VERSION ""

NS_ :

BS_:

BU_: ACU BrakeTemp_FL BrakeTemp_FR BrakeTemp_RL BrakeTemp_RR DGPS Debugger ECU InboardFloor_FL InboardFloor_FR InboardFloor_RL InboardFloor_RR Steering_Wheel Suspension_FL Suspension_FR Suspension_RL Suspension_RR TCM TireTemp_FL TireTemp_FR TireTemp_RL TireTemp_RR ALL

BO_ 2183159554 Steering_Wheel_Regen_Buttons_to_: 1 Steering_Wheel
 SG_ button_flags : 0|8@1+ (1,0) [0|0] ""  ECU

BO_ 2150629633 ACU_Debug_FD_to_Debugger: 64 ACU
 SG_ Debug_0 : 0|8@1+ (1,0) [0|0] ""  Debugger
 SG_ Debug_1 : 8|8@1+ (1,0) [0|0] ""  Debugger
 SG_ Debug_2 : 16|8@1+ (1,0) [0|0] ""  Debugger
 SG_ Debug_3 : 24|8@1+ (1,0) [0|0] ""  Debugger
 SG_ Debug_4 : 32|8@1+ (1,0) [0|0] ""  Debugger
 SG_ Debug_5 : 40|8@1+ (1,0) [0|0] ""  Debugger
 SG_ Debug_6 : 48|8@1+ (1,0) [0|0] ""  Debugger
 SG_ Debug_7 : 56|8@1+ (1,0) [0|0] ""  Debugger
 SG_ Debug_8 : 64|8@1+ (1,0) [0|0] ""  Debugger
 SG_ Debug_9 : 72|8@1+ (1,0) [0|0] ""  Debugger
 SG_ Debug_10 : 80|8@1+ (1,0) [0|0] ""  Debugger
 SG_ Debug_11 : 88|8@1+ (1,0) [0|0] ""  Debugger
 SG_ Debug_12 : 96|8@1+ (1,0) [0|0] ""  Debugger
 SG_ Debug_13 : 104|8@1+ (1,0) [0|0] ""  Debugger
 SG_ Debug_14 : 112|8@1+ (1,0) [0|0] ""  Debugger
 SG_ Debug_15 : 120|8@1+ (1,0) [0|0] ""  Debugger
 SG_ Debug_16 : 128|8@1+ (1,0) [0|0] ""  Debugger
 SG_ Debug_17 : 136|8@1+ (1,0) [0|0] ""  Debugger
 SG_ Debug_18 : 144|8@1+ (1,0) [0|0] ""  Debugger
 SG_ Debug_19 : 152|8@1+ (1,0) [0|0] ""  Debugger
 SG_ Debug_20 : 160|8@1+ (1,0) [0|0] ""  Debugger
 SG_ Debug_21 : 168|8@1+ (1,0) [0|0] ""  Debugger
 SG_ Debug_22 : 176|8@1+ (1,0) [0|0] ""  Debugger
 SG_ Debug_23 : 184|8@1+ (1,0) [0|0] ""  Debugger
 SG_ Debug_24 : 192|8@1+ (1,0) [0|0] ""  Debugger
 SG_ Debug_25 : 200|8@1+ (1,0) [0|0] ""  Debugger
 SG_ Debug_26 : 208|8@1+ (1,0) [0|0] ""  Debugger
 SG_ Debug_27 : 216|8@1+ (1,0) [0|0] ""  Debugger
 SG_ Debug_28 : 224|8@1+ (1,0) [0|0] ""  Debugger
 SG_ Debug_29 : 232|8@1+ (1,0) [0|0] ""  Debugger
 SG_ Debug_30 : 240|8@1+ (1,0) [0|0] ""  Debugger
 SG_ Debug_31 : 248|8@1+ (1,0) [0|0] ""  Debugger
 SG_ Debug_32 : 256|8@1+ (1,0) [0|0] ""  Debugger
 SG_ Debug_33 : 264|8@1+ (1,0) [0|0] ""  Debugger
 SG_ Debug_34 : 272|8@1+ (1,0) [0|0] ""  Debugger
 SG_ Debug_35 : 280|8@1+ (1,0) [0|0] ""  Debugger
 SG_ Debug_36 : 288|8@1+ (1,0) [0|0] ""  Debugger
 SG_ Debug_37 : 296|8@1+ (1,0) [0|0] ""  Debugger
 SG_ Debug_38 : 304|8@1+ (1,0) [0|0] ""  Debugger
 SG_ Debug_39 : 312|8@1+ (1,0) [0|0] ""  Debugger
 SG_ Debug_40 : 320|8@1+ (1,0) [0|0] ""  Debugger
 SG_ Debug_41 : 328|8@1+ (1,0) [0|0] ""  Debugger
 SG_ Debug_42 : 336|8@1+ (1,0) [0|0] ""  Debugger
 SG_ Debug_43 : 344|8@1+ (1,0) [0|0] ""  Debugger
 SG_ Debug_44 : 352|8@1+ (1,0) [0|0] ""  Debugger
 SG_ Debug_45 : 360|8@1+ (1,0) [0|0] ""  Debugger
 SG_ Debug_46 : 368|8@1+ (1,0) [0|0] ""  Debugger
 SG_ Debug_47 : 376|8@1+ (1,0) [0|0] ""  Debugger
 SG_ Debug_48 : 384|8@1+ (1,0) [0|0] ""  Debugger
 SG_ Debug_49 : 392|8@1+ (1,0) [0|0] ""  Debugger
 SG_ Debug_50 : 400|8@1+ (1,0) [0|0] ""  Debugger
 SG_ Debug_51 : 408|8@1+ (1,0) [0|0] ""  Debugger
 SG_ Debug_52 : 416|8@1+ (1,0) [0|0] ""  Debugger
 SG_ Debug_53 : 424|8@1+ (1,0) [0|0] ""  Debugger
 SG_ Debug_54 : 432|8@1+ (1,0) [0|0] ""  Debugger
 SG_ Debug_55 : 440|8@1+ (1,0) [0|0] ""  Debugger
 SG_ Debug_56 : 448|8@1+ (1,0) [0|0] ""  Debugger
 SG_ Debug_57 : 456|8@1+ (1,0) [0|0] ""  Debugger
 SG_ Debug_58 : 464|8@1+ (1,0) [0|0] ""  Debugger
 SG_ Debug_59 : 472|8@1+ (1,0) [0|0] ""  Debugger
 SG_ Debug_60 : 480|8@1+ (1,0) [0|0] ""  Debugger
 SG_ Debug_61 : 488|8@1+ (1,0) [0|0] ""  Debugger
 SG_ Debug_62 : 496|8@1+ (1,0) [0|0] ""  Debugger
 SG_ Debug_63 : 504|8@1+ (1,0) [0|0] ""  Debugger

BO_ 2150629889 ACU_Ping_to_Debugger: 4 ACU
 SG_ Timestamp : 0|32@1+ (1,0) [0|4294967295] "ms"  Debugger

BO_ 2150629890 ACU_Ping_to_ECU: 4 ACU
 SG_ Timestamp : 0|32@1+ (1,0) [0|4294967295] "ms"  ECU

BO_ 2150632706 ACU_ACU_Cell_Data_1_to_ECU: 64 ACU
 SG_ Cell_0_Voltage : 0|8@1+ (0.01,2) [2|4.55] "Volts"  ECU
 SG_ Cell_0_Temp : 8|8@1+ (0.25,0) [0|63.75] "Celsius"  ECU
 SG_ Cell_1_Voltage : 16|8@1+ (0.01,2) [2|4.55] "Volts"  ECU
 SG_ Cell_1_Temp : 24|8@1+ (0.25,0) [0|63.75] "Celsius"  ECU
 SG_ Cell_2_Voltage : 32|8@1+ (0.01,2) [2|4.55] "Volts"  ECU
 SG_ Cell_2_Temp : 40|8@1+ (0.25,0) [0|63.75] "Celsius"  ECU
 SG_ Cell_3_Voltage : 48|8@1+ (0.01,2) [2|4.55] "Volts"  ECU
 SG_ Cell_3_Temp : 56|8@1+ (0.25,0) [0|63.75] "Celsius"  ECU
 SG_ Cell_4_Voltage : 64|8@1+ (0.01,2) [2|4.55] "Volts"  ECU
 SG_ Cell_4_Temp : 72|8@1+ (0.25,0) [0|63.75] "Celsius"  ECU
 SG_ Cell_5_Voltage : 80|8@1+ (0.01,2) [2|4.55] "Volts"  ECU
 SG_ Cell_5_Temp : 88|8@1+ (0.25,0) [0|63.75] "Celsius"  ECU
 SG_ Cell_6_Voltage : 96|8@1+ (0.01,2) [2|4.55] "Volts"  ECU
 SG_ Cell_6_Temp : 104|8@1+ (0.25,0) [0|63.75] "Celsius"  ECU
 SG_ Cell_7_Voltage : 112|8@1+ (0.01,2) [2|4.55] "Volts"  ECU
 SG_ Cell_7_Temp : 120|8@1+ (0.25,0) [0|63.75] "Celsius"  ECU
 SG_ Cell_8_Voltage : 128|8@1+ (0.01,2) [2|4.55] "Volts"  ECU
 SG_ Cell_8_Temp : 136|8@1+ (0.25,0) [0|63.75] "Celsius"  ECU
 SG_ Cell_9_Voltage : 144|8@1+ (0.01,2) [2|4.55] "Volts"  ECU
 SG_ Cell_9_Temp : 152|8@1+ (0.25,0) [0|63.75] "Celsius"  ECU
 SG_ Cell_10_Voltage : 160|8@1+ (0.01,2) [2|4.55] "Volts"  ECU
 SG_ Cell_10_Temp : 168|8@1+ (0.25,0) [0|63.75] "Celsius"  ECU
 SG_ Cell_11_Voltage : 176|8@1+ (0.01,2) [2|4.55] "Volts"  ECU
 SG_ Cell_11_Temp : 184|8@1+ (0.25,0) [0|63.75] "Celsius"  ECU
 SG_ Cell_12_Voltage : 192|8@1+ (0.01,2) [2|4.55] "Volts"  ECU
 SG_ Cell_12_Temp : 200|8@1+ (0.25,0) [0|63.75] "Celsius"  ECU
 SG_ Cell_13_Voltage : 208|8@1+ (0.01,2) [2|4.55] "Volts"  ECU
 SG_ Cell_13_Temp : 216|8@1+ (0.25,0) [0|63.75] "Celsius"  ECU
 SG_ Cell_14_Voltage : 224|8@1+ (0.01,2) [2|4.55] "Volts"  ECU
 SG_ Cell_14_Temp : 232|8@1+ (0.25,0) [0|63.75] "Celsius"  ECU
 SG_ Cell_15_Voltage : 240|8@1+ (0.01,2) [2|4.55] "Volts"  ECU
 SG_ Cell_15_Temp : 248|8@1+ (0.25,0) [0|63.75] "Celsius"  ECU
 SG_ Cell_16_Voltage : 256|8@1+ (0.01,2) [2|4.55] "Volts"  ECU
 SG_ Cell_16_Temp : 264|8@1+ (0.25,0) [0|63.75] "Celsius"  ECU
 SG_ Cell_17_Voltage : 272|8@1+ (0.01,2) [2|4.55] "Volts"  ECU
 SG_ Cell_17_Temp : 280|8@1+ (0.25,0) [0|63.75] "Celsius"  ECU
 SG_ Cell_18_Voltage : 288|8@1+ (0.01,2) [2|4.55] "Volts"  ECU
 SG_ Cell_18_Temp : 296|8@1+ (0.25,0) [0|63.75] "Celsius"  ECU
 SG_ Cell_19_Voltage : 304|8@1+ (0.01,2) [2|4.55] "Volts"  ECU
 SG_ Cell_19_Temp : 312|8@1+ (0.25,0) [0|63.75] "Celsius"  ECU
 SG_ Cell_20_Voltage : 320|8@1+ (0.01,2) [2|4.55] "Volts"  ECU
 SG_ Cell_20_Temp : 328|8@1+ (0.25,0) [0|63.75] "Celsius"  ECU
 SG_ Cell_21_Voltage : 336|8@1+ (0.01,2) [2|4.55] "Volts"  ECU
 SG_ Cell_21_Temp : 344|8@1+ (0.25,0) [0|63.75] "Celsius"  ECU
 SG_ Cell_22_Voltage : 352|8@1+ (0.01,2) [2|4.55] "Volts"  ECU
 SG_ Cell_22_Temp : 360|8@1+ (0.25,0) [0|63.75] "Celsius"  ECU
 SG_ Cell_23_Voltage : 368|8@1+ (0.01,2) [2|4.55] "Volts"  ECU
 SG_ Cell_23_Temp : 376|8@1+ (0.25,0) [0|63.75] "Celsius"  ECU
 SG_ Cell_24_Voltage : 384|8@1+ (0.01,2) [2|4.55] "Volts"  ECU
 SG_ Cell_24_Temp : 392|8@1+ (0.25,0) [0|63.75] "Celsius"  ECU
 SG_ Cell_25_Voltage : 400|8@1+ (0.01,2) [2|4.55] "Volts"  ECU
 SG_ Cell_25_Temp : 408|8@1+ (0.25,0) [0|63.75] "Celsius"  ECU
 SG_ Cell_26_Voltage : 416|8@1+ (0.01,2) [2|4.55] "Volts"  ECU
 SG_ Cell_26_Temp : 424|8@1+ (0.25,0) [0|63.75] "Celsius"  ECU
 SG_ Cell_27_Voltage : 432|8@1+ (0.01,2) [2|4.55] "Volts"  ECU
 SG_ Cell_27_Temp : 440|8@1+ (0.25,0) [0|63.75] "Celsius"  ECU
 SG_ Cell_28_Voltage : 448|8@1+ (0.01,2) [2|4.55] "Volts"  ECU
 SG_ Cell_28_Temp : 456|8@1+ (0.25,0) [0|63.75] "Celsius"  ECU
 SG_ Cell_29_Voltage : 464|8@1+ (0.01,2) [2|4.55] "Volts"  ECU
 SG_ Cell_29_Temp : 472|8@1+ (0.25,0) [0|63.75] "Celsius"  ECU
 SG_ Cell_30_Voltage : 480|8@1+ (0.01,2) [2|4.55] "Volts"  ECU
 SG_ Cell_30_Temp : 488|8@1+ (0.25,0) [0|63.75] "Celsius"  ECU
 SG_ Cell_31_Voltage : 496|8@1+ (0.01,2) [2|4.55] "Volts"  ECU
 SG_ Cell_31_Temp : 504|8@1+ (0.25,0) [0|63.75] "Celsius"  ECU

BO_ 2150632962 ACU_ACU_Cell_Data_2_to_ECU: 64 ACU
 SG_ Cell_32_Voltage : 0|8@1+ (0.01,2) [2|4.55] "Volts"  ECU
 SG_ Cell_32_Temp : 8|8@1+ (0.25,0) [0|63.75] "Celsius"  ECU
 SG_ Cell_33_Voltage : 16|8@1+ (0.01,2) [2|4.55] "Volts"  ECU
 SG_ Cell_33_Temp : 24|8@1+ (0.25,0) [0|63.75] "Celsius"  ECU
 SG_ Cell_34_Voltage : 32|8@1+ (0.01,2) [2|4.55] "Volts"  ECU
 SG_ Cell_34_Temp : 40|8@1+ (0.25,0) [0|63.75] "Celsius"  ECU
 SG_ Cell_35_Voltage : 48|8@1+ (0.01,2) [2|4.55] "Volts"  ECU
 SG_ Cell_35_Temp : 56|8@1+ (0.25,0) [0|63.75] "Celsius"  ECU
 SG_ Cell_36_Voltage : 64|8@1+ (0.01,2) [2|4.55] "Volts"  ECU
 SG_ Cell_36_Temp : 72|8@1+ (0.25,0) [0|63.75] "Celsius"  ECU
 SG_ Cell_37_Voltage : 80|8@1+ (0.01,2) [2|4.55] "Volts"  ECU
 SG_ Cell_37_Temp : 88|8@1+ (0.25,0) [0|63.75] "Celsius"  ECU
 SG_ Cell_38_Voltage : 96|8@1+ (0.01,2) [2|4.55] "Volts"  ECU
 SG_ Cell_38_Temp : 104|8@1+ (0.25,0) [0|63.75] "Celsius"  ECU
 SG_ Cell_39_Voltage : 112|8@1+ (0.01,2) [2|4.55] "Volts"  ECU
 SG_ Cell_39_Temp : 120|8@1+ (0.25,0) [0|63.75] "Celsius"  ECU
 SG_ Cell_40_Voltage : 128|8@1+ (0.01,2) [2|4.55] "Volts"  ECU
 SG_ Cell_40_Temp : 136|8@1+ (0.25,0) [0|63.75] "Celsius"  ECU
 SG_ Cell_41_Voltage : 144|8@1+ (0.01,2) [2|4.55] "Volts"  ECU
 SG_ Cell_41_Temp : 152|8@1+ (0.25,0) [0|63.75] "Celsius"  ECU
 SG_ Cell_42_Voltage : 160|8@1+ (0.01,2) [2|4.55] "Volts"  ECU
 SG_ Cell_42_Temp : 168|8@1+ (0.25,0) [0|63.75] "Celsius"  ECU
 SG_ Cell_43_Voltage : 176|8@1+ (0.01,2) [2|4.55] "Volts"  ECU
 SG_ Cell_43_Temp : 184|8@1+ (0.25,0) [0|63.75] "Celsius"  ECU
 SG_ Cell_44_Voltage : 192|8@1+ (0.01,2) [2|4.55] "Volts"  ECU
 SG_ Cell_44_Temp : 200|8@1+ (0.25,0) [0|63.75] "Celsius"  ECU
 SG_ Cell_45_Voltage : 208|8@1+ (0.01,2) [2|4.55] "Volts"  ECU
 SG_ Cell_45_Temp : 216|8@1+ (0.25,0) [0|63.75] "Celsius"  ECU
 SG_ Cell_46_Voltage : 224|8@1+ (0.01,2) [2|4.55] "Volts"  ECU
 SG_ Cell_46_Temp : 232|8@1+ (0.25,0) [0|63.75] "Celsius"  ECU
 SG_ Cell_47_Voltage : 240|8@1+ (0.01,2) [2|4.55] "Volts"  ECU
 SG_ Cell_47_Temp : 248|8@1+ (0.25,0) [0|63.75] "Celsius"  ECU
 SG_ Cell_48_Voltage : 256|8@1+ (0.01,2) [2|4.55] "Volts"  ECU
 SG_ Cell_48_Temp : 264|8@1+ (0.25,0) [0|63.75] "Celsius"  ECU
 SG_ Cell_49_Voltage : 272|8@1+ (0.01,2) [2|4.55] "Volts"  ECU
 SG_ Cell_49_Temp : 280|8@1+ (0.25,0) [0|63.75] "Celsius"  ECU
 SG_ Cell_50_Voltage : 288|8@1+ (0.01,2) [2|4.55] "Volts"  ECU
 SG_ Cell_50_Temp : 296|8@1+ (0.25,0) [0|63.75] "Celsius"  ECU
 SG_ Cell_51_Voltage : 304|8@1+ (0.01,2) [2|4.55] "Volts"  ECU
 SG_ Cell_51_Temp : 312|8@1+ (0.25,0) [0|63.75] "Celsius"  ECU
 SG_ Cell_52_Voltage : 320|8@1+ (0.01,2) [2|4.55] "Volts"  ECU
 SG_ Cell_52_Temp : 328|8@1+ (0.25,0) [0|63.75] "Celsius"  ECU
 SG_ Cell_53_Voltage : 336|8@1+ (0.01,2) [2|4.55] "Volts"  ECU
 SG_ Cell_53_Temp : 344|8@1+ (0.25,0) [0|63.75] "Celsius"  ECU
 SG_ Cell_54_Voltage : 352|8@1+ (0.01,2) [2|4.55] "Volts"  ECU
 SG_ Cell_54_Temp : 360|8@1+ (0.25,0) [0|63.75] "Celsius"  ECU
 SG_ Cell_55_Voltage : 368|8@1+ (0.01,2) [2|4.55] "Volts"  ECU
 SG_ Cell_55_Temp : 376|8@1+ (0.25,0) [0|63.75] "Celsius"  ECU
 SG_ Cell_56_Voltage : 384|8@1+ (0.01,2) [2|4.55] "Volts"  ECU
 SG_ Cell_56_Temp : 392|8@1+ (0.25,0) [0|63.75] "Celsius"  ECU
 SG_ Cell_57_Voltage : 400|8@1+ (0.01,2) [2|4.55] "Volts"  ECU
 SG_ Cell_57_Temp : 408|8@1+ (0.25,0) [0|63.75] "Celsius"  ECU
 SG_ Cell_58_Voltage : 416|8@1+ (0.01,2) [2|4.55] "Volts"  ECU
 SG_ Cell_58_Temp : 424|8@1+ (0.25,0) [0|63.75] "Celsius"  ECU
 SG_ Cell_59_Voltage : 432|8@1+ (0.01,2) [2|4.55] "Volts"  ECU
 SG_ Cell_59_Temp : 440|8@1+ (0.25,0) [0|63.75] "Celsius"  ECU
 SG_ Cell_60_Voltage : 448|8@1+ (0.01,2) [2|4.55] "Volts"  ECU
 SG_ Cell_60_Temp : 456|8@1+ (0.25,0) [0|63.75] "Celsius"  ECU
 SG_ Cell_61_Voltage : 464|8@1+ (0.01,2) [2|4.55] "Volts"  ECU
 SG_ Cell_61_Temp : 472|8@1+ (0.25,0) [0|63.75] "Celsius"  ECU
 SG_ Cell_62_Voltage : 480|8@1+ (0.01,2) [2|4.55] "Volts"  ECU
 SG_ Cell_62_Temp : 488|8@1+ (0.25,0) [0|63.75] "Celsius"  ECU
 SG_ Cell_63_Voltage : 496|8@1+ (0.01,2) [2|4.55] "Volts"  ECU
 SG_ Cell_63_Temp : 504|8@1+ (0.25,0) [0|63.75] "Celsius"  ECU

BO_ 2150633218 ACU_ACU_Cell_Data_3_to_ECU: 64 ACU
 SG_ Cell_64_Voltage : 0|8@1+ (0.01,2) [2|4.55] "Volts"  ECU
 SG_ Cell_64_Temp : 8|8@1+ (0.25,0) [0|63.75] "Celsius"  ECU
 SG_ Cell_65_Voltage : 16|8@1+ (0.01,2) [2|4.55] "Volts"  ECU
 SG_ Cell_65_Temp : 24|8@1+ (0.25,0) [0|63.75] "Celsius"  ECU
 SG_ Cell_66_Voltage : 32|8@1+ (0.01,2) [2|4.55] "Volts"  ECU
 SG_ Cell_66_Temp : 40|8@1+ (0.25,0) [0|63.75] "Celsius"  ECU
 SG_ Cell_67_Voltage : 48|8@1+ (0.01,2) [2|4.55] "Volts"  ECU
 SG_ Cell_67_Temp : 56|8@1+ (0.25,0) [0|63.75] "Celsius"  ECU
 SG_ Cell_68_Voltage : 64|8@1+ (0.01,2) [2|4.55] "Volts"  ECU
 SG_ Cell_68_Temp : 72|8@1+ (0.25,0) [0|63.75] "Celsius"  ECU
 SG_ Cell_69_Voltage : 80|8@1+ (0.01,2) [2|4.55] "Volts"  ECU
 SG_ Cell_69_Temp : 88|8@1+ (0.25,0) [0|63.75] "Celsius"  ECU
 SG_ Cell_70_Voltage : 96|8@1+ (0.01,2) [2|4.55] "Volts"  ECU
 SG_ Cell_70_Temp : 104|8@1+ (0.25,0) [0|63.75] "Celsius"  ECU
 SG_ Cell_71_Voltage : 112|8@1+ (0.01,2) [2|4.55] "Volts"  ECU
 SG_ Cell_71_Temp : 120|8@1+ (0.25,0) [0|63.75] "Celsius"  ECU
 SG_ Cell_72_Voltage : 128|8@1+ (0.01,2) [2|4.55] "Volts"  ECU
 SG_ Cell_72_Temp : 136|8@1+ (0.25,0) [0|63.75] "Celsius"  ECU
 SG_ Cell_73_Voltage : 144|8@1+ (0.01,2) [2|4.55] "Volts"  ECU
 SG_ Cell_73_Temp : 152|8@1+ (0.25,0) [0|63.75] "Celsius"  ECU
 SG_ Cell_74_Voltage : 160|8@1+ (0.01,2) [2|4.55] "Volts"  ECU
 SG_ Cell_74_Temp : 168|8@1+ (0.25,0) [0|63.75] "Celsius"  ECU
 SG_ Cell_75_Voltage : 176|8@1+ (0.01,2) [2|4.55] "Volts"  ECU
 SG_ Cell_75_Temp : 184|8@1+ (0.25,0) [0|63.75] "Celsius"  ECU
 SG_ Cell_76_Voltage : 192|8@1+ (0.01,2) [2|4.55] "Volts"  ECU
 SG_ Cell_76_Temp : 200|8@1+ (0.25,0) [0|63.75] "Celsius"  ECU
 SG_ Cell_77_Voltage : 208|8@1+ (0.01,2) [2|4.55] "Volts"  ECU
 SG_ Cell_77_Temp : 216|8@1+ (0.25,0) [0|63.75] "Celsius"  ECU
 SG_ Cell_78_Voltage : 224|8@1+ (0.01,2) [2|4.55] "Volts"  ECU
 SG_ Cell_78_Temp : 232|8@1+ (0.25,0) [0|63.75] "Celsius"  ECU
 SG_ Cell_79_Voltage : 240|8@1+ (0.01,2) [2|4.55] "Volts"  ECU
 SG_ Cell_79_Temp : 248|8@1+ (0.25,0) [0|63.75] "Celsius"  ECU
 SG_ Cell_80_Voltage : 256|8@1+ (0.01,2) [2|4.55] "Volts"  ECU
 SG_ Cell_80_Temp : 264|8@1+ (0.25,0) [0|63.75] "Celsius"  ECU
 SG_ Cell_81_Voltage : 272|8@1+ (0.01,2) [2|4.55] "Volts"  ECU
 SG_ Cell_81_Temp : 280|8@1+ (0.25,0) [0|63.75] "Celsius"  ECU
 SG_ Cell_82_Voltage : 288|8@1+ (0.01,2) [2|4.55] "Volts"  ECU
 SG_ Cell_82_Temp : 296|8@1+ (0.25,0) [0|63.75] "Celsius"  ECU
 SG_ Cell_83_Voltage : 304|8@1+ (0.01,2) [2|4.55] "Volts"  ECU
 SG_ Cell_83_Temp : 312|8@1+ (0.25,0) [0|63.75] "Celsius"  ECU
 SG_ Cell_84_Voltage : 320|8@1+ (0.01,2) [2|4.55] "Volts"  ECU
 SG_ Cell_84_Temp : 328|8@1+ (0.25,0) [0|63.75] "Celsius"  ECU
 SG_ Cell_85_Voltage : 336|8@1+ (0.01,2) [2|4.55] "Volts"  ECU
 SG_ Cell_85_Temp : 344|8@1+ (0.25,0) [0|63.75] "Celsius"  ECU
 SG_ Cell_86_Voltage : 352|8@1+ (0.01,2) [2|4.55] "Volts"  ECU
 SG_ Cell_86_Temp : 360|8@1+ (0.25,0) [0|63.75] "Celsius"  ECU
 SG_ Cell_87_Voltage : 368|8@1+ (0.01,2) [2|4.55] "Volts"  ECU
 SG_ Cell_87_Temp : 376|8@1+ (0.25,0) [0|63.75] "Celsius"  ECU
 SG_ Cell_88_Voltage : 384|8@1+ (0.01,2) [2|4.55] "Volts"  ECU
 SG_ Cell_88_Temp : 392|8@1+ (0.25,0) [0|63.75] "Celsius"  ECU
 SG_ Cell_89_Voltage : 400|8@1+ (0.01,2) [2|4.55] "Volts"  ECU
 SG_ Cell_89_Temp : 408|8@1+ (0.25,0) [0|63.75] "Celsius"  ECU
 SG_ Cell_90_Voltage : 416|8@1+ (0.01,2) [2|4.55] "Volts"  ECU
 SG_ Cell_90_Temp : 424|8@1+ (0.25,0) [0|63.75] "Celsius"  ECU
 SG_ Cell_91_Voltage : 432|8@1+ (0.01,2) [2|4.55] "Volts"  ECU
 SG_ Cell_91_Temp : 440|8@1+ (0.25,0) [0|63.75] "Celsius"  ECU
 SG_ Cell_92_Voltage : 448|8@1+ (0.01,2) [2|4.55] "Volts"  ECU
 SG_ Cell_92_Temp : 456|8@1+ (0.25,0) [0|63.75] "Celsius"  ECU
 SG_ Cell_93_Voltage : 464|8@1+ (0.01,2) [2|4.55] "Volts"  ECU
 SG_ Cell_93_Temp : 472|8@1+ (0.25,0) [0|63.75] "Celsius"  ECU
 SG_ Cell_94_Voltage : 480|8@1+ (0.01,2) [2|4.55] "Volts"  ECU
 SG_ Cell_94_Temp : 488|8@1+ (0.25,0) [0|63.75] "Celsius"  ECU
 SG_ Cell_95_Voltage : 496|8@1+ (0.01,2) [2|4.55] "Volts"  ECU
 SG_ Cell_95_Temp : 504|8@1+ (0.25,0) [0|63.75] "Celsius"  ECU

BO_ 2150633474 ACU_ACU_Cell_Data_4_to_ECU: 64 ACU
 SG_ Cell_96_Voltage : 0|8@1+ (0.01,2) [2|4.55] "Volts"  ECU
 SG_ Cell_96_Temp : 8|8@1+ (0.25,0) [0|63.75] "Celsius"  ECU
 SG_ Cell_97_Voltage : 16|8@1+ (0.01,2) [2|4.55] "Volts"  ECU
 SG_ Cell_97_Temp : 24|8@1+ (0.25,0) [0|63.75] "Celsius"  ECU
 SG_ Cell_98_Voltage : 32|8@1+ (0.01,2) [2|4.55] "Volts"  ECU
 SG_ Cell_98_Temp : 40|8@1+ (0.25,0) [0|63.75] "Celsius"  ECU
 SG_ Cell_99_Voltage : 48|8@1+ (0.01,2) [2|4.55] "Volts"  ECU
 SG_ Cell_99_Temp : 56|8@1+ (0.25,0) [0|63.75] "Celsius"  ECU
 SG_ Cell_100_Voltage : 64|8@1+ (0.01,2) [2|4.55] "Volts"  ECU
 SG_ Cell_100_Temp : 72|8@1+ (0.25,0) [0|63.75] "Celsius"  ECU
 SG_ Cell_101_Voltage : 80|8@1+ (0.01,2) [2|4.55] "Volts"  ECU
 SG_ Cell_101_Temp : 88|8@1+ (0.25,0) [0|63.75] "Celsius"  ECU
 SG_ Cell_102_Voltage : 96|8@1+ (0.01,2) [2|4.55] "Volts"  ECU
 SG_ Cell_102_Temp : 104|8@1+ (0.25,0) [0|63.75] "Celsius"  ECU
 SG_ Cell_103_Voltage : 112|8@1+ (0.01,2) [2|4.55] "Volts"  ECU
 SG_ Cell_103_Temp : 120|8@1+ (0.25,0) [0|63.75] "Celsius"  ECU
 SG_ Cell_104_Voltage : 128|8@1+ (0.01,2) [2|4.55] "Volts"  ECU
 SG_ Cell_104_Temp : 136|8@1+ (0.25,0) [0|63.75] "Celsius"  ECU
 SG_ Cell_105_Voltage : 144|8@1+ (0.01,2) [2|4.55] "Volts"  ECU
 SG_ Cell_105_Temp : 152|8@1+ (0.25,0) [0|63.75] "Celsius"  ECU
 SG_ Cell_106_Voltage : 160|8@1+ (0.01,2) [2|4.55] "Volts"  ECU
 SG_ Cell_106_Temp : 168|8@1+ (0.25,0) [0|63.75] "Celsius"  ECU
 SG_ Cell_107_Voltage : 176|8@1+ (0.01,2) [2|4.55] "Volts"  ECU
 SG_ Cell_107_Temp : 184|8@1+ (0.25,0) [0|63.75] "Celsius"  ECU
 SG_ Cell_108_Voltage : 192|8@1+ (0.01,2) [2|4.55] "Volts"  ECU
 SG_ Cell_108_Temp : 200|8@1+ (0.25,0) [0|63.75] "Celsius"  ECU
 SG_ Cell_109_Voltage : 208|8@1+ (0.01,2) [2|4.55] "Volts"  ECU
 SG_ Cell_109_Temp : 216|8@1+ (0.25,0) [0|63.75] "Celsius"  ECU
 SG_ Cell_110_Voltage : 224|8@1+ (0.01,2) [2|4.55] "Volts"  ECU
 SG_ Cell_110_Temp : 232|8@1+ (0.25,0) [0|63.75] "Celsius"  ECU
 SG_ Cell_111_Voltage : 240|8@1+ (0.01,2) [2|4.55] "Volts"  ECU
 SG_ Cell_111_Temp : 248|8@1+ (0.25,0) [0|63.75] "Celsius"  ECU
 SG_ Cell_112_Voltage : 256|8@1+ (0.01,2) [2|4.55] "Volts"  ECU
 SG_ Cell_112_Temp : 264|8@1+ (0.25,0) [0|63.75] "Celsius"  ECU
 SG_ Cell_113_Voltage : 272|8@1+ (0.01,2) [2|4.55] "Volts"  ECU
 SG_ Cell_113_Temp : 280|8@1+ (0.25,0) [0|63.75] "Celsius"  ECU
 SG_ Cell_114_Voltage : 288|8@1+ (0.01,2) [2|4.55] "Volts"  ECU
 SG_ Cell_114_Temp : 296|8@1+ (0.25,0) [0|63.75] "Celsius"  ECU
 SG_ Cell_115_Voltage : 304|8@1+ (0.01,2) [2|4.55] "Volts"  ECU
 SG_ Cell_115_Temp : 312|8@1+ (0.25,0) [0|63.75] "Celsius"  ECU
 SG_ Cell_116_Voltage : 320|8@1+ (0.01,2) [2|4.55] "Volts"  ECU
 SG_ Cell_116_Temp : 328|8@1+ (0.25,0) [0|63.75] "Celsius"  ECU
 SG_ Cell_117_Voltage : 336|8@1+ (0.01,2) [2|4.55] "Volts"  ECU
 SG_ Cell_117_Temp : 344|8@1+ (0.25,0) [0|63.75] "Celsius"  ECU
 SG_ Cell_118_Voltage : 352|8@1+ (0.01,2) [2|4.55] "Volts"  ECU
 SG_ Cell_118_Temp : 360|8@1+ (0.25,0) [0|63.75] "Celsius"  ECU
 SG_ Cell_119_Voltage : 368|8@1+ (0.01,2) [2|4.55] "Volts"  ECU
 SG_ Cell_119_Temp : 376|8@1+ (0.25,0) [0|63.75] "Celsius"  ECU
 SG_ Cell_120_Voltage : 384|8@1+ (0.01,2) [2|4.55] "Volts"  ECU
 SG_ Cell_120_Temp : 392|8@1+ (0.25,0) [0|63.75] "Celsius"  ECU
 SG_ Cell_121_Voltage : 400|8@1+ (0.01,2) [2|4.55] "Volts"  ECU
 SG_ Cell_121_Temp : 408|8@1+ (0.25,0) [0|63.75] "Celsius"  ECU
 SG_ Cell_122_Voltage : 416|8@1+ (0.01,2) [2|4.55] "Volts"  ECU
 SG_ Cell_122_Temp : 424|8@1+ (0.25,0) [0|63.75] "Celsius"  ECU
 SG_ Cell_123_Voltage : 432|8@1+ (0.01,2) [2|4.55] "Volts"  ECU
 SG_ Cell_123_Temp : 440|8@1+ (0.25,0) [0|63.75] "Celsius"  ECU
 SG_ Cell_124_Voltage : 448|8@1+ (0.01,2) [2|4.55] "Volts"  ECU
 SG_ Cell_124_Temp : 456|8@1+ (0.25,0) [0|63.75] "Celsius"  ECU
 SG_ Cell_125_Voltage : 464|8@1+ (0.01,2) [2|4.55] "Volts"  ECU
 SG_ Cell_125_Temp : 472|8@1+ (0.25,0) [0|63.75] "Celsius"  ECU
 SG_ Cell_126_Voltage : 480|8@1+ (0.01,2) [2|4.55] "Volts"  ECU
 SG_ Cell_126_Temp : 488|8@1+ (0.25,0) [0|63.75] "Celsius"  ECU
 SG_ Cell_127_Voltage : 496|8@1+ (0.01,2) [2|4.55] "Volts"  ECU
 SG_ Cell_127_Temp : 504|8@1+ (0.25,0) [0|63.75] "Celsius"  ECU

BO_ 2150633730 ACU_ACU_Cell_Data_5_to_ECU: 64 ACU
 SG_ Cell_128_Voltage : 0|8@1+ (0.01,2) [2|4.55] "Volts"  ECU
 SG_ Cell_128_Temp : 8|8@1+ (0.25,0) [0|63.75] "Celsius"  ECU
 SG_ Cell_129_Voltage : 16|8@1+ (0.01,2) [2|4.55] "Volts"  ECU
 SG_ Cell_129_Temp : 24|8@1+ (0.25,0) [0|63.75] "Celsius"  ECU
 SG_ Cell_130_Voltage : 32|8@1+ (0.01,2) [2|4.55] "Volts"  ECU
 SG_ Cell_130_Temp : 40|8@1+ (0.25,0) [0|63.75] "Celsius"  ECU
 SG_ Cell_131_Voltage : 48|8@1+ (0.01,2) [2|4.55] "Volts"  ECU
 SG_ Cell_131_Temp : 56|8@1+ (0.25,0) [0|63.75] "Celsius"  ECU
 SG_ Cell_132_Voltage : 64|8@1+ (0.01,2) [2|4.55] "Volts"  ECU
 SG_ Cell_132_Temp : 72|8@1+ (0.25,0) [0|63.75] "Celsius"  ECU
 SG_ Cell_133_Voltage : 80|8@1+ (0.01,2) [2|4.55] "Volts"  ECU
 SG_ Cell_133_Temp : 88|8@1+ (0.25,0) [0|63.75] "Celsius"  ECU
 SG_ Cell_134_Voltage : 96|8@1+ (0.01,2) [2|4.55] "Volts"  ECU
 SG_ Cell_134_Temp : 104|8@1+ (0.25,0) [0|63.75] "Celsius"  ECU
 SG_ Cell_135_Voltage : 112|8@1+ (0.01,2) [2|4.55] "Volts"  ECU
 SG_ Cell_135_Temp : 120|8@1+ (0.25,0) [0|63.75] "Celsius"  ECU
 SG_ Cell_136_Voltage : 128|8@1+ (0.01,2) [2|4.55] "Volts"  ECU
 SG_ Cell_136_Temp : 136|8@1+ (0.25,0) [0|63.75] "Celsius"  ECU
 SG_ Cell_137_Voltage : 144|8@1+ (0.01,2) [2|4.55] "Volts"  ECU
 SG_ Cell_137_Temp : 152|8@1+ (0.25,0) [0|63.75] "Celsius"  ECU
 SG_ Cell_138_Voltage : 160|8@1+ (0.01,2) [2|4.55] "Volts"  ECU
 SG_ Cell_138_Temp : 168|8@1+ (0.25,0) [0|63.75] "Celsius"  ECU
 SG_ Cell_139_Voltage : 176|8@1+ (0.01,2) [2|4.55] "Volts"  ECU
 SG_ Cell_139_Temp : 184|8@1+ (0.25,0) [0|63.75] "Celsius"  ECU
 SG_ Cell_140_Voltage : 192|8@1+ (0.01,2) [2|4.55] "Volts"  ECU
 SG_ Cell_140_Temp : 200|8@1+ (0.25,0) [0|63.75] "Celsius"  ECU
 SG_ Cell_141_Voltage : 208|8@1+ (0.01,2) [2|4.55] "Volts"  ECU
 SG_ Cell_141_Temp : 216|8@1+ (0.25,0) [0|63.75] "Celsius"  ECU
 SG_ Cell_142_Voltage : 224|8@1+ (0.01,2) [2|4.55] "Volts"  ECU
 SG_ Cell_142_Temp : 232|8@1+ (0.25,0) [0|63.75] "Celsius"  ECU
 SG_ Cell_143_Voltage : 240|8@1+ (0.01,2) [2|4.55] "Volts"  ECU
 SG_ Cell_143_Temp : 248|8@1+ (0.25,0) [0|63.75] "Celsius"  ECU
 SG_ Cell_144_Voltage : 256|8@1+ (0.01,2) [2|4.55] "Volts"  ECU
 SG_ Cell_144_Temp : 264|8@1+ (0.25,0) [0|63.75] "Celsius"  ECU
 SG_ Cell_145_Voltage : 272|8@1+ (0.01,2) [2|4.55] "Volts"  ECU
 SG_ Cell_145_Temp : 280|8@1+ (0.25,0) [0|63.75] "Celsius"  ECU
 SG_ Cell_146_Voltage : 288|8@1+ (0.01,2) [2|4.55] "Volts"  ECU
 SG_ Cell_146_Temp : 296|8@1+ (0.25,0) [0|63.75] "Celsius"  ECU
 SG_ Cell_147_Voltage : 304|8@1+ (0.01,2) [2|4.55] "Volts"  ECU
 SG_ Cell_147_Temp : 312|8@1+ (0.25,0) [0|63.75] "Celsius"  ECU
 SG_ Cell_148_Voltage : 320|8@1+ (0.01,2) [2|4.55] "Volts"  ECU
 SG_ Cell_148_Temp : 328|8@1+ (0.25,0) [0|63.75] "Celsius"  ECU
 SG_ Cell_149_Voltage : 336|8@1+ (0.01,2) [2|4.55] "Volts"  ECU
 SG_ Cell_149_Temp : 344|8@1+ (0.25,0) [0|63.75] "Celsius"  ECU
 SG_ Cell_150_Voltage : 352|8@1+ (0.01,2) [2|4.55] "Volts"  ECU
 SG_ Cell_150_Temp : 360|8@1+ (0.25,0) [0|63.75] "Celsius"  ECU
 SG_ Cell_151_Voltage : 368|8@1+ (0.01,2) [2|4.55] "Volts"  ECU
 SG_ Cell_151_Temp : 376|8@1+ (0.25,0) [0|63.75] "Celsius"  ECU
 SG_ Cell_152_Voltage : 384|8@1+ (0.01,2) [2|4.55] "Volts"  ECU
 SG_ Cell_152_Temp : 392|8@1+ (0.25,0) [0|63.75] "Celsius"  ECU
 SG_ Cell_153_Voltage : 400|8@1+ (0.01,2) [2|4.55] "Volts"  ECU
 SG_ Cell_153_Temp : 408|8@1+ (0.25,0) [0|63.75] "Celsius"  ECU
 SG_ Cell_154_Voltage : 416|8@1+ (0.01,2) [2|4.55] "Volts"  ECU
 SG_ Cell_154_Temp : 424|8@1+ (0.25,0) [0|63.75] "Celsius"  ECU
 SG_ Cell_155_Voltage : 432|8@1+ (0.01,2) [2|4.55] "Volts"  ECU
 SG_ Cell_155_Temp : 440|8@1+ (0.25,0) [0|63.75] "Celsius"  ECU
 SG_ Cell_156_Voltage : 448|8@1+ (0.01,2) [2|4.55] "Volts"  ECU
 SG_ Cell_156_Temp : 456|8@1+ (0.25,0) [0|63.75] "Celsius"  ECU
 SG_ Cell_157_Voltage : 464|8@1+ (0.01,2) [2|4.55] "Volts"  ECU
 SG_ Cell_157_Temp : 472|8@1+ (0.25,0) [0|63.75] "Celsius"  ECU
 SG_ Cell_158_Voltage : 480|8@1+ (0.01,2) [2|4.55] "Volts"  ECU
 SG_ Cell_158_Temp : 488|8@1+ (0.25,0) [0|63.75] "Celsius"  ECU
 SG_ Cell_159_Voltage : 496|8@1+ (0.01,2) [2|4.55] "Volts"  ECU
 SG_ Cell_159_Temp : 504|8@1+ (0.25,0) [0|63.75] "Celsius"  ECU

BO_ 2148532482 Debugger_FD_to_ECU: 64 Debugger
 SG_ Debug_0 : 0|8@1+ (1,0) [0|0] ""  ECU
 SG_ Debug_1 : 8|8@1+ (1,0) [0|0] ""  ECU
 SG_ Debug_2 : 16|8@1+ (1,0) [0|0] ""  ECU
 SG_ Debug_3 : 24|8@1+ (1,0) [0|0] ""  ECU
 SG_ Debug_4 : 32|8@1+ (1,0) [0|0] ""  ECU
 SG_ Debug_5 : 40|8@1+ (1,0) [0|0] ""  ECU
 SG_ Debug_6 : 48|8@1+ (1,0) [0|0] ""  ECU
 SG_ Debug_7 : 56|8@1+ (1,0) [0|0] ""  ECU
 SG_ Debug_8 : 64|8@1+ (1,0) [0|0] ""  ECU
 SG_ Debug_9 : 72|8@1+ (1,0) [0|0] ""  ECU
 SG_ Debug_10 : 80|8@1+ (1,0) [0|0] ""  ECU
 SG_ Debug_11 : 88|8@1+ (1,0) [0|0] ""  ECU
 SG_ Debug_12 : 96|8@1+ (1,0) [0|0] ""  ECU
 SG_ Debug_13 : 104|8@1+ (1,0) [0|0] ""  ECU
 SG_ Debug_14 : 112|8@1+ (1,0) [0|0] ""  ECU
 SG_ Debug_15 : 120|8@1+ (1,0) [0|0] ""  ECU
 SG_ Debug_16 : 128|8@1+ (1,0) [0|0] ""  ECU
 SG_ Debug_17 : 136|8@1+ (1,0) [0|0] ""  ECU
 SG_ Debug_18 : 144|8@1+ (1,0) [0|0] ""  ECU
 SG_ Debug_19 : 152|8@1+ (1,0) [0|0] ""  ECU
 SG_ Debug_20 : 160|8@1+ (1,0) [0|0] ""  ECU
 SG_ Debug_21 : 168|8@1+ (1,0) [0|0] ""  ECU
 SG_ Debug_22 : 176|8@1+ (1,0) [0|0] ""  ECU
 SG_ Debug_23 : 184|8@1+ (1,0) [0|0] ""  ECU
 SG_ Debug_24 : 192|8@1+ (1,0) [0|0] ""  ECU
 SG_ Debug_25 : 200|8@1+ (1,0) [0|0] ""  ECU
 SG_ Debug_26 : 208|8@1+ (1,0) [0|0] ""  ECU
 SG_ Debug_27 : 216|8@1+ (1,0) [0|0] ""  ECU
 SG_ Debug_28 : 224|8@1+ (1,0) [0|0] ""  ECU
 SG_ Debug_29 : 232|8@1+ (1,0) [0|0] ""  ECU
 SG_ Debug_30 : 240|8@1+ (1,0) [0|0] ""  ECU
 SG_ Debug_31 : 248|8@1+ (1,0) [0|0] ""  ECU
 SG_ Debug_32 : 256|8@1+ (1,0) [0|0] ""  ECU
 SG_ Debug_33 : 264|8@1+ (1,0) [0|0] ""  ECU
 SG_ Debug_34 : 272|8@1+ (1,0) [0|0] ""  ECU
 SG_ Debug_35 : 280|8@1+ (1,0) [0|0] ""  ECU
 SG_ Debug_36 : 288|8@1+ (1,0) [0|0] ""  ECU
 SG_ Debug_37 : 296|8@1+ (1,0) [0|0] ""  ECU
 SG_ Debug_38 : 304|8@1+ (1,0) [0|0] ""  ECU
 SG_ Debug_39 : 312|8@1+ (1,0) [0|0] ""  ECU
 SG_ Debug_40 : 320|8@1+ (1,0) [0|0] ""  ECU
 SG_ Debug_41 : 328|8@1+ (1,0) [0|0] ""  ECU
 SG_ Debug_42 : 336|8@1+ (1,0) [0|0] ""  ECU
 SG_ Debug_43 : 344|8@1+ (1,0) [0|0] ""  ECU
 SG_ Debug_44 : 352|8@1+ (1,0) [0|0] ""  ECU
 SG_ Debug_45 : 360|8@1+ (1,0) [0|0] ""  ECU
 SG_ Debug_46 : 368|8@1+ (1,0) [0|0] ""  ECU
 SG_ Debug_47 : 376|8@1+ (1,0) [0|0] ""  ECU
 SG_ Debug_48 : 384|8@1+ (1,0) [0|0] ""  ECU
 SG_ Debug_49 : 392|8@1+ (1,0) [0|0] ""  ECU
 SG_ Debug_50 : 400|8@1+ (1,0) [0|0] ""  ECU
 SG_ Debug_51 : 408|8@1+ (1,0) [0|0] ""  ECU
 SG_ Debug_52 : 416|8@1+ (1,0) [0|0] ""  ECU
 SG_ Debug_53 : 424|8@1+ (1,0) [0|0] ""  ECU
 SG_ Debug_54 : 432|8@1+ (1,0) [0|0] ""  ECU
 SG_ Debug_55 : 440|8@1+ (1,0) [0|0] ""  ECU
 SG_ Debug_56 : 448|8@1+ (1,0) [0|0] ""  ECU
 SG_ Debug_57 : 456|8@1+ (1,0) [0|0] ""  ECU
 SG_ Debug_58 : 464|8@1+ (1,0) [0|0] ""  ECU
 SG_ Debug_59 : 472|8@1+ (1,0) [0|0] ""  ECU
 SG_ Debug_60 : 480|8@1+ (1,0) [0|0] ""  ECU
 SG_ Debug_61 : 488|8@1+ (1,0) [0|0] ""  ECU
 SG_ Debug_62 : 496|8@1+ (1,0) [0|0] ""  ECU
 SG_ Debug_63 : 504|8@1+ (1,0) [0|0] ""  ECU

BO_ 2148532738 Debugger_Ping_to_ECU: 4 Debugger
 SG_ Timestamp : 0|32@1+ (1,0) [0|4294967295] "ms"  ECU

BO_ 2148532483 Debugger_FD_to_ACU: 64 Debugger
 SG_ Debug_0 : 0|8@1+ (1,0) [0|0] ""  ACU
 SG_ Debug_1 : 8|8@1+ (1,0) [0|0] ""  ACU
 SG_ Debug_2 : 16|8@1+ (1,0) [0|0] ""  ACU
 SG_ Debug_3 : 24|8@1+ (1,0) [0|0] ""  ACU
 SG_ Debug_4 : 32|8@1+ (1,0) [0|0] ""  ACU
 SG_ Debug_5 : 40|8@1+ (1,0) [0|0] ""  ACU
 SG_ Debug_6 : 48|8@1+ (1,0) [0|0] ""  ACU
 SG_ Debug_7 : 56|8@1+ (1,0) [0|0] ""  ACU
 SG_ Debug_8 : 64|8@1+ (1,0) [0|0] ""  ACU
 SG_ Debug_9 : 72|8@1+ (1,0) [0|0] ""  ACU
 SG_ Debug_10 : 80|8@1+ (1,0) [0|0] ""  ACU
 SG_ Debug_11 : 88|8@1+ (1,0) [0|0] ""  ACU
 SG_ Debug_12 : 96|8@1+ (1,0) [0|0] ""  ACU
 SG_ Debug_13 : 104|8@1+ (1,0) [0|0] ""  ACU
 SG_ Debug_14 : 112|8@1+ (1,0) [0|0] ""  ACU
 SG_ Debug_15 : 120|8@1+ (1,0) [0|0] ""  ACU
 SG_ Debug_16 : 128|8@1+ (1,0) [0|0] ""  ACU
 SG_ Debug_17 : 136|8@1+ (1,0) [0|0] ""  ACU
 SG_ Debug_18 : 144|8@1+ (1,0) [0|0] ""  ACU
 SG_ Debug_19 : 152|8@1+ (1,0) [0|0] ""  ACU
 SG_ Debug_20 : 160|8@1+ (1,0) [0|0] ""  ACU
 SG_ Debug_21 : 168|8@1+ (1,0) [0|0] ""  ACU
 SG_ Debug_22 : 176|8@1+ (1,0) [0|0] ""  ACU
 SG_ Debug_23 : 184|8@1+ (1,0) [0|0] ""  ACU
 SG_ Debug_24 : 192|8@1+ (1,0) [0|0] ""  ACU
 SG_ Debug_25 : 200|8@1+ (1,0) [0|0] ""  ACU
 SG_ Debug_26 : 208|8@1+ (1,0) [0|0] ""  ACU
 SG_ Debug_27 : 216|8@1+ (1,0) [0|0] ""  ACU
 SG_ Debug_28 : 224|8@1+ (1,0) [0|0] ""  ACU
 SG_ Debug_29 : 232|8@1+ (1,0) [0|0] ""  ACU
 SG_ Debug_30 : 240|8@1+ (1,0) [0|0] ""  ACU
 SG_ Debug_31 : 248|8@1+ (1,0) [0|0] ""  ACU
 SG_ Debug_32 : 256|8@1+ (1,0) [0|0] ""  ACU
 SG_ Debug_33 : 264|8@1+ (1,0) [0|0] ""  ACU
 SG_ Debug_34 : 272|8@1+ (1,0) [0|0] ""  ACU
 SG_ Debug_35 : 280|8@1+ (1,0) [0|0] ""  ACU
 SG_ Debug_36 : 288|8@1+ (1,0) [0|0] ""  ACU
 SG_ Debug_37 : 296|8@1+ (1,0) [0|0] ""  ACU
 SG_ Debug_38 : 304|8@1+ (1,0) [0|0] ""  ACU
 SG_ Debug_39 : 312|8@1+ (1,0) [0|0] ""  ACU
 SG_ Debug_40 : 320|8@1+ (1,0) [0|0] ""  ACU
 SG_ Debug_41 : 328|8@1+ (1,0) [0|0] ""  ACU
 SG_ Debug_42 : 336|8@1+ (1,0) [0|0] ""  ACU
 SG_ Debug_43 : 344|8@1+ (1,0) [0|0] ""  ACU
 SG_ Debug_44 : 352|8@1+ (1,0) [0|0] ""  ACU
 SG_ Debug_45 : 360|8@1+ (1,0) [0|0] ""  ACU
 SG_ Debug_46 : 368|8@1+ (1,0) [0|0] ""  ACU
 SG_ Debug_47 : 376|8@1+ (1,0) [0|0] ""  ACU
 SG_ Debug_48 : 384|8@1+ (1,0) [0|0] ""  ACU
 SG_ Debug_49 : 392|8@1+ (1,0) [0|0] ""  ACU
 SG_ Debug_50 : 400|8@1+ (1,0) [0|0] ""  ACU
 SG_ Debug_51 : 408|8@1+ (1,0) [0|0] ""  ACU
 SG_ Debug_52 : 416|8@1+ (1,0) [0|0] ""  ACU
 SG_ Debug_53 : 424|8@1+ (1,0) [0|0] ""  ACU
 SG_ Debug_54 : 432|8@1+ (1,0) [0|0] ""  ACU
 SG_ Debug_55 : 440|8@1+ (1,0) [0|0] ""  ACU
 SG_ Debug_56 : 448|8@1+ (1,0) [0|0] ""  ACU
 SG_ Debug_57 : 456|8@1+ (1,0) [0|0] ""  ACU
 SG_ Debug_58 : 464|8@1+ (1,0) [0|0] ""  ACU
 SG_ Debug_59 : 472|8@1+ (1,0) [0|0] ""  ACU
 SG_ Debug_60 : 480|8@1+ (1,0) [0|0] ""  ACU
 SG_ Debug_61 : 488|8@1+ (1,0) [0|0] ""  ACU
 SG_ Debug_62 : 496|8@1+ (1,0) [0|0] ""  ACU
 SG_ Debug_63 : 504|8@1+ (1,0) [0|0] ""  ACU

BO_ 2148532739 Debugger_Ping_to_ACU: 4 Debugger
 SG_ Timestamp : 0|32@1+ (1,0) [0|4294967295] "ms"  ACU

BO_ 2148532484 Debugger_FD_to_TCM: 64 Debugger
 SG_ Debug_0 : 0|8@1+ (1,0) [0|0] ""  TCM
 SG_ Debug_1 : 8|8@1+ (1,0) [0|0] ""  TCM
 SG_ Debug_2 : 16|8@1+ (1,0) [0|0] ""  TCM
 SG_ Debug_3 : 24|8@1+ (1,0) [0|0] ""  TCM
 SG_ Debug_4 : 32|8@1+ (1,0) [0|0] ""  TCM
 SG_ Debug_5 : 40|8@1+ (1,0) [0|0] ""  TCM
 SG_ Debug_6 : 48|8@1+ (1,0) [0|0] ""  TCM
 SG_ Debug_7 : 56|8@1+ (1,0) [0|0] ""  TCM
 SG_ Debug_8 : 64|8@1+ (1,0) [0|0] ""  TCM
 SG_ Debug_9 : 72|8@1+ (1,0) [0|0] ""  TCM
 SG_ Debug_10 : 80|8@1+ (1,0) [0|0] ""  TCM
 SG_ Debug_11 : 88|8@1+ (1,0) [0|0] ""  TCM
 SG_ Debug_12 : 96|8@1+ (1,0) [0|0] ""  TCM
 SG_ Debug_13 : 104|8@1+ (1,0) [0|0] ""  TCM
 SG_ Debug_14 : 112|8@1+ (1,0) [0|0] ""  TCM
 SG_ Debug_15 : 120|8@1+ (1,0) [0|0] ""  TCM
 SG_ Debug_16 : 128|8@1+ (1,0) [0|0] ""  TCM
 SG_ Debug_17 : 136|8@1+ (1,0) [0|0] ""  TCM
 SG_ Debug_18 : 144|8@1+ (1,0) [0|0] ""  TCM
 SG_ Debug_19 : 152|8@1+ (1,0) [0|0] ""  TCM
 SG_ Debug_20 : 160|8@1+ (1,0) [0|0] ""  TCM
 SG_ Debug_21 : 168|8@1+ (1,0) [0|0] ""  TCM
 SG_ Debug_22 : 176|8@1+ (1,0) [0|0] ""  TCM
 SG_ Debug_23 : 184|8@1+ (1,0) [0|0] ""  TCM
 SG_ Debug_24 : 192|8@1+ (1,0) [0|0] ""  TCM
 SG_ Debug_25 : 200|8@1+ (1,0) [0|0] ""  TCM
 SG_ Debug_26 : 208|8@1+ (1,0) [0|0] ""  TCM
 SG_ Debug_27 : 216|8@1+ (1,0) [0|0] ""  TCM
 SG_ Debug_28 : 224|8@1+ (1,0) [0|0] ""  TCM
 SG_ Debug_29 : 232|8@1+ (1,0) [0|0] ""  TCM
 SG_ Debug_30 : 240|8@1+ (1,0) [0|0] ""  TCM
 SG_ Debug_31 : 248|8@1+ (1,0) [0|0] ""  TCM
 SG_ Debug_32 : 256|8@1+ (1,0) [0|0] ""  TCM
 SG_ Debug_33 : 264|8@1+ (1,0) [0|0] ""  TCM
 SG_ Debug_34 : 272|8@1+ (1,0) [0|0] ""  TCM
 SG_ Debug_35 : 280|8@1+ (1,0) [0|0] ""  TCM
 SG_ Debug_36 : 288|8@1+ (1,0) [0|0] ""  TCM
 SG_ Debug_37 : 296|8@1+ (1,0) [0|0] ""  TCM
 SG_ Debug_38 : 304|8@1+ (1,0) [0|0] ""  TCM
 SG_ Debug_39 : 312|8@1+ (1,0) [0|0] ""  TCM
 SG_ Debug_40 : 320|8@1+ (1,0) [0|0] ""  TCM
 SG_ Debug_41 : 328|8@1+ (1,0) [0|0] ""  TCM
 SG_ Debug_42 : 336|8@1+ (1,0) [0|0] ""  TCM
 SG_ Debug_43 : 344|8@1+ (1,0) [0|0] ""  TCM
 SG_ Debug_44 : 352|8@1+ (1,0) [0|0] ""  TCM
 SG_ Debug_45 : 360|8@1+ (1,0) [0|0] ""  TCM
 SG_ Debug_46 : 368|8@1+ (1,0) [0|0] ""  TCM
 SG_ Debug_47 : 376|8@1+ (1,0) [0|0] ""  TCM
 SG_ Debug_48 : 384|8@1+ (1,0) [0|0] ""  TCM
 SG_ Debug_49 : 392|8@1+ (1,0) [0|0] ""  TCM
 SG_ Debug_50 : 400|8@1+ (1,0) [0|0] ""  TCM
 SG_ Debug_51 : 408|8@1+ (1,0) [0|0] ""  TCM
 SG_ Debug_52 : 416|8@1+ (1,0) [0|0] ""  TCM
 SG_ Debug_53 : 424|8@1+ (1,0) [0|0] ""  TCM
 SG_ Debug_54 : 432|8@1+ (1,0) [0|0] ""  TCM
 SG_ Debug_55 : 440|8@1+ (1,0) [0|0] ""  TCM
 SG_ Debug_56 : 448|8@1+ (1,0) [0|0] ""  TCM
 SG_ Debug_57 : 456|8@1+ (1,0) [0|0] ""  TCM
 SG_ Debug_58 : 464|8@1+ (1,0) [0|0] ""  TCM
 SG_ Debug_59 : 472|8@1+ (1,0) [0|0] ""  TCM
 SG_ Debug_60 : 480|8@1+ (1,0) [0|0] ""  TCM
 SG_ Debug_61 : 488|8@1+ (1,0) [0|0] ""  TCM
 SG_ Debug_62 : 496|8@1+ (1,0) [0|0] ""  TCM
 SG_ Debug_63 : 504|8@1+ (1,0) [0|0] ""  TCM

BO_ 2148532740 Debugger_Ping_to_TCM: 4 Debugger
 SG_ Timestamp : 0|32@1+ (1,0) [0|4294967295] "ms"  TCM

BO_ 2149581057 ECU_Debug_FD_to_Debugger: 64 ECU
 SG_ Debug_0 : 0|8@1+ (1,0) [0|0] ""  Debugger
 SG_ Debug_1 : 8|8@1+ (1,0) [0|0] ""  Debugger
 SG_ Debug_2 : 16|8@1+ (1,0) [0|0] ""  Debugger
 SG_ Debug_3 : 24|8@1+ (1,0) [0|0] ""  Debugger
 SG_ Debug_4 : 32|8@1+ (1,0) [0|0] ""  Debugger
 SG_ Debug_5 : 40|8@1+ (1,0) [0|0] ""  Debugger
 SG_ Debug_6 : 48|8@1+ (1,0) [0|0] ""  Debugger
 SG_ Debug_7 : 56|8@1+ (1,0) [0|0] ""  Debugger
 SG_ Debug_8 : 64|8@1+ (1,0) [0|0] ""  Debugger
 SG_ Debug_9 : 72|8@1+ (1,0) [0|0] ""  Debugger
 SG_ Debug_10 : 80|8@1+ (1,0) [0|0] ""  Debugger
 SG_ Debug_11 : 88|8@1+ (1,0) [0|0] ""  Debugger
 SG_ Debug_12 : 96|8@1+ (1,0) [0|0] ""  Debugger
 SG_ Debug_13 : 104|8@1+ (1,0) [0|0] ""  Debugger
 SG_ Debug_14 : 112|8@1+ (1,0) [0|0] ""  Debugger
 SG_ Debug_15 : 120|8@1+ (1,0) [0|0] ""  Debugger
 SG_ Debug_16 : 128|8@1+ (1,0) [0|0] ""  Debugger
 SG_ Debug_17 : 136|8@1+ (1,0) [0|0] ""  Debugger
 SG_ Debug_18 : 144|8@1+ (1,0) [0|0] ""  Debugger
 SG_ Debug_19 : 152|8@1+ (1,0) [0|0] ""  Debugger
 SG_ Debug_20 : 160|8@1+ (1,0) [0|0] ""  Debugger
 SG_ Debug_21 : 168|8@1+ (1,0) [0|0] ""  Debugger
 SG_ Debug_22 : 176|8@1+ (1,0) [0|0] ""  Debugger
 SG_ Debug_23 : 184|8@1+ (1,0) [0|0] ""  Debugger
 SG_ Debug_24 : 192|8@1+ (1,0) [0|0] ""  Debugger
 SG_ Debug_25 : 200|8@1+ (1,0) [0|0] ""  Debugger
 SG_ Debug_26 : 208|8@1+ (1,0) [0|0] ""  Debugger
 SG_ Debug_27 : 216|8@1+ (1,0) [0|0] ""  Debugger
 SG_ Debug_28 : 224|8@1+ (1,0) [0|0] ""  Debugger
 SG_ Debug_29 : 232|8@1+ (1,0) [0|0] ""  Debugger
 SG_ Debug_30 : 240|8@1+ (1,0) [0|0] ""  Debugger
 SG_ Debug_31 : 248|8@1+ (1,0) [0|0] ""  Debugger
 SG_ Debug_32 : 256|8@1+ (1,0) [0|0] ""  Debugger
 SG_ Debug_33 : 264|8@1+ (1,0) [0|0] ""  Debugger
 SG_ Debug_34 : 272|8@1+ (1,0) [0|0] ""  Debugger
 SG_ Debug_35 : 280|8@1+ (1,0) [0|0] ""  Debugger
 SG_ Debug_36 : 288|8@1+ (1,0) [0|0] ""  Debugger
 SG_ Debug_37 : 296|8@1+ (1,0) [0|0] ""  Debugger
 SG_ Debug_38 : 304|8@1+ (1,0) [0|0] ""  Debugger
 SG_ Debug_39 : 312|8@1+ (1,0) [0|0] ""  Debugger
 SG_ Debug_40 : 320|8@1+ (1,0) [0|0] ""  Debugger
 SG_ Debug_41 : 328|8@1+ (1,0) [0|0] ""  Debugger
 SG_ Debug_42 : 336|8@1+ (1,0) [0|0] ""  Debugger
 SG_ Debug_43 : 344|8@1+ (1,0) [0|0] ""  Debugger
 SG_ Debug_44 : 352|8@1+ (1,0) [0|0] ""  Debugger
 SG_ Debug_45 : 360|8@1+ (1,0) [0|0] ""  Debugger
 SG_ Debug_46 : 368|8@1+ (1,0) [0|0] ""  Debugger
 SG_ Debug_47 : 376|8@1+ (1,0) [0|0] ""  Debugger
 SG_ Debug_48 : 384|8@1+ (1,0) [0|0] ""  Debugger
 SG_ Debug_49 : 392|8@1+ (1,0) [0|0] ""  Debugger
 SG_ Debug_50 : 400|8@1+ (1,0) [0|0] ""  Debugger
 SG_ Debug_51 : 408|8@1+ (1,0) [0|0] ""  Debugger
 SG_ Debug_52 : 416|8@1+ (1,0) [0|0] ""  Debugger
 SG_ Debug_53 : 424|8@1+ (1,0) [0|0] ""  Debugger
 SG_ Debug_54 : 432|8@1+ (1,0) [0|0] ""  Debugger
 SG_ Debug_55 : 440|8@1+ (1,0) [0|0] ""  Debugger
 SG_ Debug_56 : 448|8@1+ (1,0) [0|0] ""  Debugger
 SG_ Debug_57 : 456|8@1+ (1,0) [0|0] ""  Debugger
 SG_ Debug_58 : 464|8@1+ (1,0) [0|0] ""  Debugger
 SG_ Debug_59 : 472|8@1+ (1,0) [0|0] ""  Debugger
 SG_ Debug_60 : 480|8@1+ (1,0) [0|0] ""  Debugger
 SG_ Debug_61 : 488|8@1+ (1,0) [0|0] ""  Debugger
 SG_ Debug_62 : 496|8@1+ (1,0) [0|0] ""  Debugger
 SG_ Debug_63 : 504|8@1+ (1,0) [0|0] ""  Debugger

BO_ 2149581313 ECU_Ping_to_Debugger: 4 ECU
 SG_ Timestamp : 0|32@1+ (1,0) [0|4294967295] "ms"  Debugger

BO_ 2149592580 ECU_ECU_Analog_Data_to_TCM: 20 ECU
 SG_ BSPD_Signal : 0|16@1+ (0.0015259021896696422,0) [0|100] "%"  TCM
 SG_ BSE_Signal : 16|16@1+ (0.0015259021896696422,0) [0|100] "%"  TCM
 SG_ APPS_1_Signal : 32|16@1+ (0.0015259021896696422,0) [0|100] "%"  TCM
 SG_ APPS_2_Signal : 48|16@1+ (0.0015259021896696422,0) [0|100] "%"  TCM
 SG_ Brakeline_F_Signal : 64|16@1+ (0.0015259021896696422,0) [0|100] "%"  TCM
 SG_ Brakeline_R_Signal : 80|16@1+ (0.0015259021896696422,0) [0|100] "%"  TCM
 SG_ Steering_Angle_Signal : 96|16@1+ (0.0015259021896696422,0) [0|100] "%"  TCM
 SG_ AUX_Signal : 112|16@1+ (0.0015259021896696422,0) [0|100] "%"  TCM
 SG_ Acc_Pedal_Travel : 128|16@1+ (0.0015259021896696422,0) [0|100] "%"  TCM
 SG_ Brake_Pedal_Pressure : 144|16@1+ (1,0) [0|5000] "PSI"  TCM

BO_ 2149592324 ECU_ECU_Pinging_RTT_to_TCM: 24 ECU
 SG_ ACU_RTT : 0|8@1+ (1,0) [0|0] "ms"  TCM
 SG_ GR_Inv_RTT : 8|8@1+ (1,0) [0|0] "ms"  TCM
 SG_ Fan_Ctrl_1_RTT : 16|8@1+ (1,0) [0|0] "ms"  TCM
 SG_ Fan_Ctrl_2_RTT : 24|8@1+ (1,0) [0|0] "ms"  TCM
 SG_ Fan_Ctrl_3_RTT : 32|8@1+ (1,0) [0|0] "ms"  TCM
 SG_ Dash_Panel_RTT : 40|8@1+ (1,0) [0|0] "ms"  TCM
 SG_ TCM_RTT : 48|8@1+ (1,0) [0|0] "ms"  TCM
 SG_ Tire_Temp_FL_RTT : 56|8@1+ (1,0) [0|0] "ms"  TCM
 SG_ Tire_Temp_FR_RTT : 64|8@1+ (1,0) [0|0] "ms"  TCM
 SG_ Tire_Temp_RL_RTT : 72|8@1+ (1,0) [0|0] "ms"  TCM
 SG_ Tire_Temp_RR_RTT : 80|8@1+ (1,0) [0|0] "ms"  TCM
 SG_ Suspension_Node_FL_RTT : 88|8@1+ (1,0) [0|0] "ms"  TCM
 SG_ Suspension_Node_FR_RTT : 96|8@1+ (1,0) [0|0] "ms"  TCM
 SG_ Suspension_Node_RL_RTT : 104|8@1+ (1,0) [0|0] "ms"  TCM
 SG_ Suspension_Node_RR_RTT : 112|8@1+ (1,0) [0|0] "ms"  TCM
 SG_ Inboard_Floor_FL_RTT : 120|8@1+ (1,0) [0|0] "ms"  TCM
 SG_ Inboard_Floor_FR_RTT : 128|8@1+ (1,0) [0|0] "ms"  TCM
 SG_ Inboard_Floor_RL_RTT : 136|8@1+ (1,0) [0|0] "ms"  TCM
 SG_ Inboard_Floor_RR_RTT : 144|8@1+ (1,0) [0|0] "ms"  TCM
 SG_ Brake_Temp_FL_RTT : 152|8@1+ (1,0) [0|0] "ms"  TCM
 SG_ Brake_Temp_FR_RTT : 160|8@1+ (1,0) [0|0] "ms"  TCM
 SG_ Brake_Temp_RL_RTT : 168|8@1+ (1,0) [0|0] "ms"  TCM
 SG_ Brake_Temp_RR_RTT : 176|8@1+ (1,0) [0|0] "ms"  TCM
 SG_ DGPS_RTT : 184|8@1+ (1,0) [0|0] "ms"  TCM

BO_ 2149592836 ECU_ECU_Config_to_TCM: 20 ECU
 SG_ Ping_Timeout_Delay : 0|8@1+ (10,0) [0|2550] "ms"  TCM
 SG_ Brake_F_Min : 8|8@1+ (25,0) [0|6375] "PSI"  TCM
 SG_ Brake_R_Min : 16|8@1+ (25,0) [0|6375] "PSI"  TCM
 SG_ Brake_BSE_Min : 24|8@1+ (25,0) [0|6375] "PSI"  TCM
 SG_ APPS_1_Min : 32|8@1+ (10,0) [0|2550] "ADC"  TCM
 SG_ APPS_2_Min : 40|8@1+ (10,0) [0|2550] "ADC"  TCM
 SG_ APPS_1_Max : 48|8@1+ (10,0) [0|2550] "ADC"  TCM
 SG_ APPS_2_Max : 56|8@1+ (10,0) [0|2550] "ADC"  TCM
 SG_ APPS_Deadzone : 64|8@1+ (0.0392156862745098,0) [0|100] "%"  TCM
 SG_ BMS_Min_Threshold : 72|8@1+ (0.05,0) [0|12.75] "V"  TCM
 SG_ BMS_Max_Threshold : 80|8@1+ (0.05,0) [0|12.75] "V"  TCM
 SG_ IMD_Min_Threshold : 88|8@1+ (0.05,0) [0|12.75] "V"  TCM
 SG_ IMD_Max_Threshold : 96|8@1+ (0.05,0) [0|12.75] "V"  TCM
 SG_ BSPD_Min_Threshold : 104|8@1+ (0.05,0) [0|12.75] "V"  TCM
 SG_ BSPD_Max_Threshold : 112|8@1+ (0.05,0) [0|12.75] "V"  TCM
 SG_ Max_Precharge_Time : 120|8@1+ (10,0) [0|2550] "ms"  TCM
 SG_ Regen_Strength : 128|8@1+ (0.1,0) [0|25.5] "Ratio"  TCM
 SG_ Enable_Regen : 136|1@1+ (1,0) [0|0] "Bool"  TCM

BO_ 2149581312 ECU_Ping_to_ALL: 4 ECU
 SG_ Timestamp : 0|32@1+ (1,0) [0|4294967295] "ms"  ALL

BO_ 2151689986 TCM_ECU_Config_to_ECU: 20 TCM
 SG_ Ping_Timeout_Delay : 0|8@1+ (10,0) [0|2550] "ms"  ECU
 SG_ Brake_F_Min : 8|8@1+ (25,0) [0|6375] "PSI"  ECU
 SG_ Brake_R_Min : 16|8@1+ (25,0) [0|6375] "PSI"  ECU
 SG_ Brake_BSE_Min : 24|8@1+ (25,0) [0|6375] "PSI"  ECU
 SG_ APPS_1_Min : 32|8@1+ (10,0) [0|2550] "ADC"  ECU
 SG_ APPS_2_Min : 40|8@1+ (10,0) [0|2550] "ADC"  ECU
 SG_ APPS_1_Max : 48|8@1+ (10,0) [0|2550] "ADC"  ECU
 SG_ APPS_2_Max : 56|8@1+ (10,0) [0|2550] "ADC"  ECU
 SG_ APPS_Deadzone : 64|8@1+ (0.0392156862745098,0) [0|100] "%"  ECU
 SG_ BMS_Min_Threshold : 72|8@1+ (0.05,0) [0|12.75] "V"  ECU
 SG_ BMS_Max_Threshold : 80|8@1+ (0.05,0) [0|12.75] "V"  ECU
 SG_ IMD_Min_Threshold : 88|8@1+ (0.05,0) [0|12.75] "V"  ECU
 SG_ IMD_Max_Threshold : 96|8@1+ (0.05,0) [0|12.75] "V"  ECU
 SG_ BSPD_Min_Threshold : 104|8@1+ (0.05,0) [0|12.75] "V"  ECU
 SG_ BSPD_Max_Threshold : 112|8@1+ (0.05,0) [0|12.75] "V"  ECU
 SG_ Max_Precharge_Time : 120|8@1+ (10,0) [0|2550] "ms"  ECU
 SG_ Regen_Strength : 128|8@1+ (0.1,0) [0|25.5] "Ratio"  ECU
 SG_ Enable_Regen : 136|1@1+ (1,0) [0|0] "Bool"  ECU

BO_ 2151678465 TCM_Ping_to_Debugger: 4 TCM
 SG_ Timestamp : 0|32@1+ (1,0) [0|4294967295] "ms"  Debugger

BO_ 2181038594 DGPS_Ping_to_ECU: 4 DGPS
 SG_ Timestamp : 0|32@1+ (1,0) [0|4294967295] "ms"  ECU

BO_ 2181051140 DGPS_GPS_ALT_to_TCM: 8 DGPS
 SG_ ALT : 0|64@1- (1,0) [0|0] ""  TCM

BO_ 2181050628 DGPS_GPS_LAT_to_TCM: 8 DGPS
 SG_ LAT : 0|64@1- (1,0) [0|0] ""  TCM

BO_ 2181050884 DGPS_GPS_LON_to_TCM: 8 DGPS
 SG_ LON : 0|64@1- (1,0) [0|0] ""  TCM

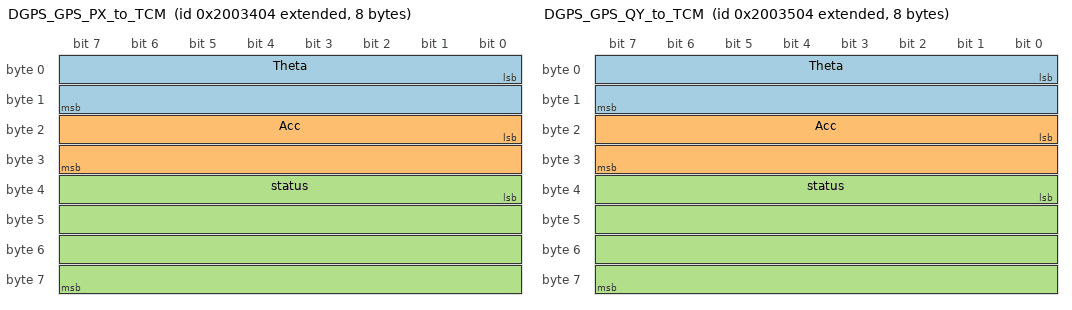
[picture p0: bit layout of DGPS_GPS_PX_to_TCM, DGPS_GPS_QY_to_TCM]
BO_ 2181051396 DGPS_GPS_PX_to_TCM: 8 DGPS
 SG_ Theta : 0|16@1- (0.001,0) [0|0] ""  TCM
 SG_ Acc : 16|16@1- (0.01,0) [0|0] ""  TCM
 SG_ status : 32|32@1+ (1,0) [0|0] ""  TCM

BO_ 2181051652 DGPS_GPS_QY_to_TCM: 8 DGPS
 SG_ Theta : 0|16@1- (0.001,0) [0|0] ""  TCM
 SG_ Acc : 16|16@1- (0.01,0) [0|0] ""  TCM
 SG_ status : 32|32@1+ (1,0) [0|0] ""  TCM

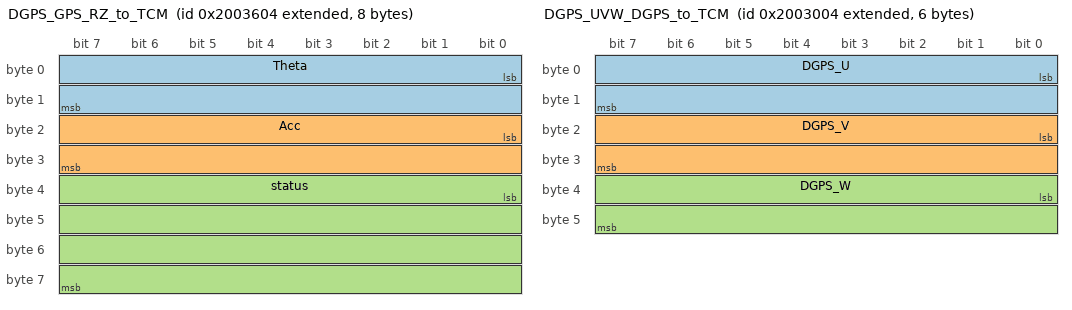
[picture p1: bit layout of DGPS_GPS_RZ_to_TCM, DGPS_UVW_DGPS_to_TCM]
BO_ 2181051908 DGPS_GPS_RZ_to_TCM: 8 DGPS
 SG_ Theta : 0|16@1- (0.001,0) [0|0] ""  TCM
 SG_ Acc : 16|16@1- (0.01,0) [0|0] ""  TCM
 SG_ status : 32|32@1+ (1,0) [0|0] ""  TCM

BO_ 2181050372 DGPS_UVW_DGPS_to_TCM: 6 DGPS
 SG_ DGPS_U : 0|16@1- (0.01,0) [0|0] ""  TCM
 SG_ DGPS_V : 16|16@1- (0.01,0) [0|0] ""  TCM
 SG_ DGPS_W : 32|16@1- (0.01,0) [0|0] ""  TCM

BO_ 2168455682 Suspension_FL_Ping_to_ECU: 4 Suspension_FL
 SG_ Timestamp : 0|32@1+ (1,0) [0|4294967295] "ms"  ECU

BO_ 2168475908 Suspension_FL_IMU_Mag_Data_to_TC: 24 Suspension_FL
 SG_ bmi323_acc_x : 0|16@1+ (1,0) [0|0] ""  TCM
 SG_ bmi323_acc_y : 16|16@1+ (1,0) [0|0] ""  TCM
 SG_ bmi323_acc_z : 32|16@1+ (1,0) [0|0] ""  TCM
 SG_ bmi323_gyro_x : 48|16@1+ (1,0) [0|0] ""  TCM
 SG_ bmi323_gyro_y : 64|16@1+ (1,0) [0|0] ""  TCM
 SG_ bmi323_gyro_z : 80|16@1+ (1,0) [0|0] ""  TCM
 SG_ bmi323_temp : 96|16@1+ (1,0) [0|0] ""  TCM
 SG_ bmi323_status : 112|16@1+ (1,0) [0|0] ""  TCM
 SG_ mag_temp : 128|16@1+ (1,0) [0|0] ""  TCM
 SG_ mag_hysteresis : 144|16@1+ (1,0) [0|0] ""  TCM
 SG_ mag_angle : 160|16@1+ (1,0) [0|0] ""  TCM
 SG_ mag_turns : 176|16@1- (1,0) [0|0] ""  TCM

BO_ 2169504258 Suspension_FR_Ping_to_ECU: 4 Suspension_FR
 SG_ Timestamp : 0|32@1+ (1,0) [0|4294967295] "ms"  ECU

BO_ 2169524484 Suspension_FR_IMU_Mag_Data_to_TC: 24 Suspension_FR
 SG_ bmi323_acc_x : 0|16@1+ (1,0) [0|0] ""  TCM
 SG_ bmi323_acc_y : 16|16@1+ (1,0) [0|0] ""  TCM
 SG_ bmi323_acc_z : 32|16@1+ (1,0) [0|0] ""  TCM
 SG_ bmi323_gyro_x : 48|16@1+ (1,0) [0|0] ""  TCM
 SG_ bmi323_gyro_y : 64|16@1+ (1,0) [0|0] ""  TCM
 SG_ bmi323_gyro_z : 80|16@1+ (1,0) [0|0] ""  TCM
 SG_ bmi323_temp : 96|16@1+ (1,0) [0|0] ""  TCM
 SG_ bmi323_status : 112|16@1+ (1,0) [0|0] ""  TCM
 SG_ mag_temp : 128|16@1+ (1,0) [0|0] ""  TCM
 SG_ mag_hysteresis : 144|16@1+ (1,0) [0|0] ""  TCM
 SG_ mag_angle : 160|16@1+ (1,0) [0|0] ""  TCM
 SG_ mag_turns : 176|16@1- (1,0) [0|0] ""  TCM

BO_ 2170552834 Suspension_RL_Ping_to_ECU: 4 Suspension_RL
 SG_ Timestamp : 0|32@1+ (1,0) [0|4294967295] "ms"  ECU

BO_ 2170573060 Suspension_RL_IMU_Mag_Data_to_TC: 24 Suspension_RL
 SG_ bmi323_acc_x : 0|16@1+ (1,0) [0|0] ""  TCM
 SG_ bmi323_acc_y : 16|16@1+ (1,0) [0|0] ""  TCM
 SG_ bmi323_acc_z : 32|16@1+ (1,0) [0|0] ""  TCM
 SG_ bmi323_gyro_x : 48|16@1+ (1,0) [0|0] ""  TCM
 SG_ bmi323_gyro_y : 64|16@1+ (1,0) [0|0] ""  TCM
 SG_ bmi323_gyro_z : 80|16@1+ (1,0) [0|0] ""  TCM
 SG_ bmi323_temp : 96|16@1+ (1,0) [0|0] ""  TCM
 SG_ bmi323_status : 112|16@1+ (1,0) [0|0] ""  TCM
 SG_ mag_temp : 128|16@1+ (1,0) [0|0] ""  TCM
 SG_ mag_hysteresis : 144|16@1+ (1,0) [0|0] ""  TCM
 SG_ mag_angle : 160|16@1+ (1,0) [0|0] ""  TCM
 SG_ mag_turns : 176|16@1- (1,0) [0|0] ""  TCM

BO_ 2171601410 Suspension_RR_Ping_to_ECU: 4 Suspension_RR
 SG_ Timestamp : 0|32@1+ (1,0) [0|4294967295] "ms"  ECU

BO_ 2171621636 Suspension_RR_IMU_Mag_Data_to_TC: 24 Suspension_RR
 SG_ bmi323_acc_x : 0|16@1+ (1,0) [0|0] ""  TCM
 SG_ bmi323_acc_y : 16|16@1+ (1,0) [0|0] ""  TCM
 SG_ bmi323_acc_z : 32|16@1+ (1,0) [0|0] ""  TCM
 SG_ bmi323_gyro_x : 48|16@1+ (1,0) [0|0] ""  TCM
 SG_ bmi323_gyro_y : 64|16@1+ (1,0) [0|0] ""  TCM
 SG_ bmi323_gyro_z : 80|16@1+ (1,0) [0|0] ""  TCM
 SG_ bmi323_temp : 96|16@1+ (1,0) [0|0] ""  TCM
 SG_ bmi323_status : 112|16@1+ (1,0) [0|0] ""  TCM
 SG_ mag_temp : 128|16@1+ (1,0) [0|0] ""  TCM
 SG_ mag_hysteresis : 144|16@1+ (1,0) [0|0] ""  TCM
 SG_ mag_angle : 160|16@1+ (1,0) [0|0] ""  TCM
 SG_ mag_turns : 176|16@1- (1,0) [0|0] ""  TCM

BO_ 2172649986 InboardFloor_FL_Ping_to_ECU: 4 InboardFloor_FL
 SG_ Timestamp : 0|32@1+ (1,0) [0|4294967295] "ms"  ECU

BO_ 2172670468 InboardFloor_FL_IMU_ToF_Data_to_: 32 InboardFloor_FL
 SG_ bmi323_acc_x : 0|16@1+ (1,0) [0|0] ""  TCM
 SG_ bmi323_acc_y : 16|16@1+ (1,0) [0|0] ""  TCM
 SG_ bmi323_acc_z : 32|16@1+ (1,0) [0|0] ""  TCM
 SG_ bmi323_gyro_x : 48|16@1+ (1,0) [0|0] ""  TCM
 SG_ bmi323_gyro_y : 64|16@1+ (1,0) [0|0] ""  TCM
 SG_ bmi323_gyro_z : 80|16@1+ (1,0) [0|0] ""  TCM
 SG_ bmi323_temp : 96|16@1+ (1,0) [0|0] ""  TCM
 SG_ bmi323_status : 112|16@1+ (1,0) [0|0] ""  TCM
 SG_ range_status : 128|8@1+ (1,0) [0|0] ""  TCM
 SG_ distance_mm : 136|16@1+ (1,0) [0|0] "mm"  TCM
 SG_ ambient_rate_kcps : 152|16@1+ (1,0) [0|0] "kcps"  TCM
 SG_ ambient_per_spad_kcps : 168|16@1+ (1,0) [0|0] "kcps"  TCM
 SG_ signal_rate_kcps : 184|16@1+ (1,0) [0|0] "kcps"  TCM
 SG_ signal_per_spad_kcps : 200|16@1+ (1,0) [0|0] "kcps"  TCM
 SG_ number_of_spad : 216|16@1+ (1,0) [0|0] ""  TCM
 SG_ sigma_mm : 232|16@1+ (1,0) [0|0] "mm"  TCM

BO_ 2173698562 InboardFloor_FR_Ping_to_ECU: 4 InboardFloor_FR
 SG_ Timestamp : 0|32@1+ (1,0) [0|4294967295] "ms"  ECU

BO_ 2173719044 InboardFloor_FR_IMU_ToF_Data_to_: 32 InboardFloor_FR
 SG_ bmi323_acc_x : 0|16@1+ (1,0) [0|0] ""  TCM
 SG_ bmi323_acc_y : 16|16@1+ (1,0) [0|0] ""  TCM
 SG_ bmi323_acc_z : 32|16@1+ (1,0) [0|0] ""  TCM
 SG_ bmi323_gyro_x : 48|16@1+ (1,0) [0|0] ""  TCM
 SG_ bmi323_gyro_y : 64|16@1+ (1,0) [0|0] ""  TCM
 SG_ bmi323_gyro_z : 80|16@1+ (1,0) [0|0] ""  TCM
 SG_ bmi323_temp : 96|16@1+ (1,0) [0|0] ""  TCM
 SG_ bmi323_status : 112|16@1+ (1,0) [0|0] ""  TCM
 SG_ range_status : 128|8@1+ (1,0) [0|0] ""  TCM
 SG_ distance_mm : 136|16@1+ (1,0) [0|0] "mm"  TCM
 SG_ ambient_rate_kcps : 152|16@1+ (1,0) [0|0] "kcps"  TCM
 SG_ ambient_per_spad_kcps : 168|16@1+ (1,0) [0|0] "kcps"  TCM
 SG_ signal_rate_kcps : 184|16@1+ (1,0) [0|0] "kcps"  TCM
 SG_ signal_per_spad_kcps : 200|16@1+ (1,0) [0|0] "kcps"  TCM
 SG_ number_of_spad : 216|16@1+ (1,0) [0|0] ""  TCM
 SG_ sigma_mm : 232|16@1+ (1,0) [0|0] "mm"  TCM

BO_ 2174747138 InboardFloor_RL_Ping_to_ECU: 4 InboardFloor_RL
 SG_ Timestamp : 0|32@1+ (1,0) [0|4294967295] "ms"  ECU

BO_ 2174767620 InboardFloor_RL_IMU_ToF_Data_to_: 32 InboardFloor_RL
 SG_ bmi323_acc_x : 0|16@1+ (1,0) [0|0] ""  TCM
 SG_ bmi323_acc_y : 16|16@1+ (1,0) [0|0] ""  TCM
 SG_ bmi323_acc_z : 32|16@1+ (1,0) [0|0] ""  TCM
 SG_ bmi323_gyro_x : 48|16@1+ (1,0) [0|0] ""  TCM
 SG_ bmi323_gyro_y : 64|16@1+ (1,0) [0|0] ""  TCM
 SG_ bmi323_gyro_z : 80|16@1+ (1,0) [0|0] ""  TCM
 SG_ bmi323_temp : 96|16@1+ (1,0) [0|0] ""  TCM
 SG_ bmi323_status : 112|16@1+ (1,0) [0|0] ""  TCM
 SG_ range_status : 128|8@1+ (1,0) [0|0] ""  TCM
 SG_ distance_mm : 136|16@1+ (1,0) [0|0] "mm"  TCM
 SG_ ambient_rate_kcps : 152|16@1+ (1,0) [0|0] "kcps"  TCM
 SG_ ambient_per_spad_kcps : 168|16@1+ (1,0) [0|0] "kcps"  TCM
 SG_ signal_rate_kcps : 184|16@1+ (1,0) [0|0] "kcps"  TCM
 SG_ signal_per_spad_kcps : 200|16@1+ (1,0) [0|0] "kcps"  TCM
 SG_ number_of_spad : 216|16@1+ (1,0) [0|0] ""  TCM
 SG_ sigma_mm : 232|16@1+ (1,0) [0|0] "mm"  TCM

BO_ 2175795714 InboardFloor_RR_Ping_to_ECU: 4 InboardFloor_RR
 SG_ Timestamp : 0|32@1+ (1,0) [0|4294967295] "ms"  ECU

BO_ 2175816196 InboardFloor_RR_IMU_ToF_Data_to_: 32 InboardFloor_RR
 SG_ bmi323_acc_x : 0|16@1+ (1,0) [0|0] ""  TCM
 SG_ bmi323_acc_y : 16|16@1+ (1,0) [0|0] ""  TCM
 SG_ bmi323_acc_z : 32|16@1+ (1,0) [0|0] ""  TCM
 SG_ bmi323_gyro_x : 48|16@1+ (1,0) [0|0] ""  TCM
 SG_ bmi323_gyro_y : 64|16@1+ (1,0) [0|0] ""  TCM
 SG_ bmi323_gyro_z : 80|16@1+ (1,0) [0|0] ""  TCM
 SG_ bmi323_temp : 96|16@1+ (1,0) [0|0] ""  TCM
 SG_ bmi323_status : 112|16@1+ (1,0) [0|0] ""  TCM
 SG_ range_status : 128|8@1+ (1,0) [0|0] ""  TCM
 SG_ distance_mm : 136|16@1+ (1,0) [0|0] "mm"  TCM
 SG_ ambient_rate_kcps : 152|16@1+ (1,0) [0|0] "kcps"  TCM
 SG_ ambient_per_spad_kcps : 168|16@1+ (1,0) [0|0] "kcps"  TCM
 SG_ signal_rate_kcps : 184|16@1+ (1,0) [0|0] "kcps"  TCM
 SG_ signal_per_spad_kcps : 200|16@1+ (1,0) [0|0] "kcps"  TCM
 SG_ number_of_spad : 216|16@1+ (1,0) [0|0] ""  TCM
 SG_ sigma_mm : 232|16@1+ (1,0) [0|0] "mm"  TCM

BO_ 2164261378 TireTemp_FL_Ping_to_ECU: 4 TireTemp_FL
 SG_ Timestamp : 0|32@1+ (1,0) [0|4294967295] "ms"  ECU

BO_ 2164274948 TireTemp_FL_Frame_0_to_TCM: 64 TireTemp_FL
 SG_ pixel0 : 0|16@1+ (0.00518798828125,-40) [0|0] "C"  TCM
 SG_ pixel1 : 16|16@1+ (0.00518798828125,-40) [0|0] "C"  TCM
 SG_ pixel2 : 32|16@1+ (0.00518798828125,-40) [0|0] "C"  TCM
 SG_ pixel3 : 48|16@1+ (0.00518798828125,-40) [0|0] "C"  TCM
 SG_ pixel4 : 64|16@1+ (0.00518798828125,-40) [0|0] "C"  TCM
 SG_ pixel5 : 80|16@1+ (0.00518798828125,-40) [0|0] "C"  TCM
 SG_ pixel6 : 96|16@1+ (0.00518798828125,-40) [0|0] "C"  TCM
 SG_ pixel7 : 112|16@1+ (0.00518798828125,-40) [0|0] "C"  TCM
 SG_ pixel8 : 128|16@1+ (0.00518798828125,-40) [0|0] "C"  TCM
 SG_ pixel9 : 144|16@1+ (0.00518798828125,-40) [0|0] "C"  TCM
 SG_ pixel10 : 160|16@1+ (0.00518798828125,-40) [0|0] "C"  TCM
 SG_ pixel11 : 176|16@1+ (0.00518798828125,-40) [0|0] "C"  TCM
 SG_ pixel12 : 192|16@1+ (0.00518798828125,-40) [0|0] "C"  TCM
 SG_ pixel13 : 208|16@1+ (0.00518798828125,-40) [0|0] "C"  TCM
 SG_ pixel14 : 224|16@1+ (0.00518798828125,-40) [0|0] "C"  TCM
 SG_ pixel15 : 240|16@1+ (0.00518798828125,-40) [0|0] "C"  TCM
 SG_ pixel16 : 256|16@1+ (0.00518798828125,-40) [0|0] "C"  TCM
 SG_ pixel17 : 272|16@1+ (0.00518798828125,-40) [0|0] "C"  TCM
 SG_ pixel18 : 288|16@1+ (0.00518798828125,-40) [0|0] "C"  TCM
 SG_ pixel19 : 304|16@1+ (0.00518798828125,-40) [0|0] "C"  TCM
 SG_ pixel20 : 320|16@1+ (0.00518798828125,-40) [0|0] "C"  TCM
 SG_ pixel21 : 336|16@1+ (0.00518798828125,-40) [0|0] "C"  TCM
 SG_ pixel22 : 352|16@1+ (0.00518798828125,-40) [0|0] "C"  TCM
 SG_ pixel23 : 368|16@1+ (0.00518798828125,-40) [0|0] "C"  TCM
 SG_ pixel24 : 384|16@1+ (0.00518798828125,-40) [0|0] "C"  TCM
 SG_ pixel25 : 400|16@1+ (0.00518798828125,-40) [0|0] "C"  TCM
 SG_ pixel26 : 416|16@1+ (0.00518798828125,-40) [0|0] "C"  TCM
 SG_ pixel27 : 432|16@1+ (0.00518798828125,-40) [0|0] "C"  TCM
 SG_ pixel28 : 448|16@1+ (0.00518798828125,-40) [0|0] "C"  TCM
 SG_ pixel29 : 464|16@1+ (0.00518798828125,-40) [0|0] "C"  TCM
 SG_ pixel30 : 480|16@1+ (0.00518798828125,-40) [0|0] "C"  TCM
 SG_ pixel31 : 496|16@1+ (0.00518798828125,-40) [0|0] "C"  TCM

BO_ 2164275204 TireTemp_FL_Frame_1_to_TCM: 64 TireTemp_FL
 SG_ pixel0 : 0|16@1+ (0.00518798828125,-40) [0|0] "C"  TCM
 SG_ pixel1 : 16|16@1+ (0.00518798828125,-40) [0|0] "C"  TCM
 SG_ pixel2 : 32|16@1+ (0.00518798828125,-40) [0|0] "C"  TCM
 SG_ pixel3 : 48|16@1+ (0.00518798828125,-40) [0|0] "C"  TCM
 SG_ pixel4 : 64|16@1+ (0.00518798828125,-40) [0|0] "C"  TCM
 SG_ pixel5 : 80|16@1+ (0.00518798828125,-40) [0|0] "C"  TCM
 SG_ pixel6 : 96|16@1+ (0.00518798828125,-40) [0|0] "C"  TCM
 SG_ pixel7 : 112|16@1+ (0.00518798828125,-40) [0|0] "C"  TCM
 SG_ pixel8 : 128|16@1+ (0.00518798828125,-40) [0|0] "C"  TCM
 SG_ pixel9 : 144|16@1+ (0.00518798828125,-40) [0|0] "C"  TCM
 SG_ pixel10 : 160|16@1+ (0.00518798828125,-40) [0|0] "C"  TCM
 SG_ pixel11 : 176|16@1+ (0.00518798828125,-40) [0|0] "C"  TCM
 SG_ pixel12 : 192|16@1+ (0.00518798828125,-40) [0|0] "C"  TCM
 SG_ pixel13 : 208|16@1+ (0.00518798828125,-40) [0|0] "C"  TCM
 SG_ pixel14 : 224|16@1+ (0.00518798828125,-40) [0|0] "C"  TCM
 SG_ pixel15 : 240|16@1+ (0.00518798828125,-40) [0|0] "C"  TCM
 SG_ pixel16 : 256|16@1+ (0.00518798828125,-40) [0|0] "C"  TCM
 SG_ pixel17 : 272|16@1+ (0.00518798828125,-40) [0|0] "C"  TCM
 SG_ pixel18 : 288|16@1+ (0.00518798828125,-40) [0|0] "C"  TCM
 SG_ pixel19 : 304|16@1+ (0.00518798828125,-40) [0|0] "C"  TCM
 SG_ pixel20 : 320|16@1+ (0.00518798828125,-40) [0|0] "C"  TCM
 SG_ pixel21 : 336|16@1+ (0.00518798828125,-40) [0|0] "C"  TCM
 SG_ pixel22 : 352|16@1+ (0.00518798828125,-40) [0|0] "C"  TCM
 SG_ pixel23 : 368|16@1+ (0.00518798828125,-40) [0|0] "C"  TCM
 SG_ pixel24 : 384|16@1+ (0.00518798828125,-40) [0|0] "C"  TCM
 SG_ pixel25 : 400|16@1+ (0.00518798828125,-40) [0|0] "C"  TCM
 SG_ pixel26 : 416|16@1+ (0.00518798828125,-40) [0|0] "C"  TCM
 SG_ pixel27 : 432|16@1+ (0.00518798828125,-40) [0|0] "C"  TCM
 SG_ pixel28 : 448|16@1+ (0.00518798828125,-40) [0|0] "C"  TCM
 SG_ pixel29 : 464|16@1+ (0.00518798828125,-40) [0|0] "C"  TCM
 SG_ pixel30 : 480|16@1+ (0.00518798828125,-40) [0|0] "C"  TCM
 SG_ pixel31 : 496|16@1+ (0.00518798828125,-40) [0|0] "C"  TCM

BO_ 2164275460 TireTemp_FL_Frame_2_to_TCM: 64 TireTemp_FL
 SG_ pixel0 : 0|16@1+ (0.00518798828125,-40) [0|0] "C"  TCM
 SG_ pixel1 : 16|16@1+ (0.00518798828125,-40) [0|0] "C"  TCM
 SG_ pixel2 : 32|16@1+ (0.00518798828125,-40) [0|0] "C"  TCM
 SG_ pixel3 : 48|16@1+ (0.00518798828125,-40) [0|0] "C"  TCM
 SG_ pixel4 : 64|16@1+ (0.00518798828125,-40) [0|0] "C"  TCM
 SG_ pixel5 : 80|16@1+ (0.00518798828125,-40) [0|0] "C"  TCM
 SG_ pixel6 : 96|16@1+ (0.00518798828125,-40) [0|0] "C"  TCM
 SG_ pixel7 : 112|16@1+ (0.00518798828125,-40) [0|0] "C"  TCM
 SG_ pixel8 : 128|16@1+ (0.00518798828125,-40) [0|0] "C"  TCM
 SG_ pixel9 : 144|16@1+ (0.00518798828125,-40) [0|0] "C"  TCM
 SG_ pixel10 : 160|16@1+ (0.00518798828125,-40) [0|0] "C"  TCM
 SG_ pixel11 : 176|16@1+ (0.00518798828125,-40) [0|0] "C"  TCM
 SG_ pixel12 : 192|16@1+ (0.00518798828125,-40) [0|0] "C"  TCM
 SG_ pixel13 : 208|16@1+ (0.00518798828125,-40) [0|0] "C"  TCM
 SG_ pixel14 : 224|16@1+ (0.00518798828125,-40) [0|0] "C"  TCM
 SG_ pixel15 : 240|16@1+ (0.00518798828125,-40) [0|0] "C"  TCM
 SG_ pixel16 : 256|16@1+ (0.00518798828125,-40) [0|0] "C"  TCM
 SG_ pixel17 : 272|16@1+ (0.00518798828125,-40) [0|0] "C"  TCM
 SG_ pixel18 : 288|16@1+ (0.00518798828125,-40) [0|0] "C"  TCM
 SG_ pixel19 : 304|16@1+ (0.00518798828125,-40) [0|0] "C"  TCM
 SG_ pixel20 : 320|16@1+ (0.00518798828125,-40) [0|0] "C"  TCM
 SG_ pixel21 : 336|16@1+ (0.00518798828125,-40) [0|0] "C"  TCM
 SG_ pixel22 : 352|16@1+ (0.00518798828125,-40) [0|0] "C"  TCM
 SG_ pixel23 : 368|16@1+ (0.00518798828125,-40) [0|0] "C"  TCM
 SG_ pixel24 : 384|16@1+ (0.00518798828125,-40) [0|0] "C"  TCM
 SG_ pixel25 : 400|16@1+ (0.00518798828125,-40) [0|0] "C"  TCM
 SG_ pixel26 : 416|16@1+ (0.00518798828125,-40) [0|0] "C"  TCM
 SG_ pixel27 : 432|16@1+ (0.00518798828125,-40) [0|0] "C"  TCM
 SG_ pixel28 : 448|16@1+ (0.00518798828125,-40) [0|0] "C"  TCM
 SG_ pixel29 : 464|16@1+ (0.00518798828125,-40) [0|0] "C"  TCM
 SG_ pixel30 : 480|16@1+ (0.00518798828125,-40) [0|0] "C"  TCM
 SG_ pixel31 : 496|16@1+ (0.00518798828125,-40) [0|0] "C"  TCM

BO_ 2164275716 TireTemp_FL_Frame_3_to_TCM: 64 TireTemp_FL
 SG_ pixel0 : 0|16@1+ (0.00518798828125,-40) [0|0] "C"  TCM
 SG_ pixel1 : 16|16@1+ (0.00518798828125,-40) [0|0] "C"  TCM
 SG_ pixel2 : 32|16@1+ (0.00518798828125,-40) [0|0] "C"  TCM
 SG_ pixel3 : 48|16@1+ (0.00518798828125,-40) [0|0] "C"  TCM
 SG_ pixel4 : 64|16@1+ (0.00518798828125,-40) [0|0] "C"  TCM
 SG_ pixel5 : 80|16@1+ (0.00518798828125,-40) [0|0] "C"  TCM
 SG_ pixel6 : 96|16@1+ (0.00518798828125,-40) [0|0] "C"  TCM
 SG_ pixel7 : 112|16@1+ (0.00518798828125,-40) [0|0] "C"  TCM
 SG_ pixel8 : 128|16@1+ (0.00518798828125,-40) [0|0] "C"  TCM
 SG_ pixel9 : 144|16@1+ (0.00518798828125,-40) [0|0] "C"  TCM
 SG_ pixel10 : 160|16@1+ (0.00518798828125,-40) [0|0] "C"  TCM
 SG_ pixel11 : 176|16@1+ (0.00518798828125,-40) [0|0] "C"  TCM
 SG_ pixel12 : 192|16@1+ (0.00518798828125,-40) [0|0] "C"  TCM
 SG_ pixel13 : 208|16@1+ (0.00518798828125,-40) [0|0] "C"  TCM
 SG_ pixel14 : 224|16@1+ (0.00518798828125,-40) [0|0] "C"  TCM
 SG_ pixel15 : 240|16@1+ (0.00518798828125,-40) [0|0] "C"  TCM
 SG_ pixel16 : 256|16@1+ (0.00518798828125,-40) [0|0] "C"  TCM
 SG_ pixel17 : 272|16@1+ (0.00518798828125,-40) [0|0] "C"  TCM
 SG_ pixel18 : 288|16@1+ (0.00518798828125,-40) [0|0] "C"  TCM
 SG_ pixel19 : 304|16@1+ (0.00518798828125,-40) [0|0] "C"  TCM
 SG_ pixel20 : 320|16@1+ (0.00518798828125,-40) [0|0] "C"  TCM
 SG_ pixel21 : 336|16@1+ (0.00518798828125,-40) [0|0] "C"  TCM
 SG_ pixel22 : 352|16@1+ (0.00518798828125,-40) [0|0] "C"  TCM
 SG_ pixel23 : 368|16@1+ (0.00518798828125,-40) [0|0] "C"  TCM
 SG_ pixel24 : 384|16@1+ (0.00518798828125,-40) [0|0] "C"  TCM
 SG_ pixel25 : 400|16@1+ (0.00518798828125,-40) [0|0] "C"  TCM
 SG_ pixel26 : 416|16@1+ (0.00518798828125,-40) [0|0] "C"  TCM
 SG_ pixel27 : 432|16@1+ (0.00518798828125,-40) [0|0] "C"  TCM
 SG_ pixel28 : 448|16@1+ (0.00518798828125,-40) [0|0] "C"  TCM
 SG_ pixel29 : 464|16@1+ (0.00518798828125,-40) [0|0] "C"  TCM
 SG_ pixel30 : 480|16@1+ (0.00518798828125,-40) [0|0] "C"  TCM
 SG_ pixel31 : 496|16@1+ (0.00518798828125,-40) [0|0] "C"  TCM

BO_ 2164275972 TireTemp_FL_Frame_4_to_TCM: 64 TireTemp_FL
 SG_ pixel0 : 0|16@1+ (0.00518798828125,-40) [0|0] "C"  TCM
 SG_ pixel1 : 16|16@1+ (0.00518798828125,-40) [0|0] "C"  TCM
 SG_ pixel2 : 32|16@1+ (0.00518798828125,-40) [0|0] "C"  TCM
 SG_ pixel3 : 48|16@1+ (0.00518798828125,-40) [0|0] "C"  TCM
 SG_ pixel4 : 64|16@1+ (0.00518798828125,-40) [0|0] "C"  TCM
 SG_ pixel5 : 80|16@1+ (0.00518798828125,-40) [0|0] "C"  TCM
 SG_ pixel6 : 96|16@1+ (0.00518798828125,-40) [0|0] "C"  TCM
 SG_ pixel7 : 112|16@1+ (0.00518798828125,-40) [0|0] "C"  TCM
 SG_ pixel8 : 128|16@1+ (0.00518798828125,-40) [0|0] "C"  TCM
 SG_ pixel9 : 144|16@1+ (0.00518798828125,-40) [0|0] "C"  TCM
 SG_ pixel10 : 160|16@1+ (0.00518798828125,-40) [0|0] "C"  TCM
 SG_ pixel11 : 176|16@1+ (0.00518798828125,-40) [0|0] "C"  TCM
 SG_ pixel12 : 192|16@1+ (0.00518798828125,-40) [0|0] "C"  TCM
 SG_ pixel13 : 208|16@1+ (0.00518798828125,-40) [0|0] "C"  TCM
 SG_ pixel14 : 224|16@1+ (0.00518798828125,-40) [0|0] "C"  TCM
 SG_ pixel15 : 240|16@1+ (0.00518798828125,-40) [0|0] "C"  TCM
 SG_ pixel16 : 256|16@1+ (0.00518798828125,-40) [0|0] "C"  TCM
 SG_ pixel17 : 272|16@1+ (0.00518798828125,-40) [0|0] "C"  TCM
 SG_ pixel18 : 288|16@1+ (0.00518798828125,-40) [0|0] "C"  TCM
 SG_ pixel19 : 304|16@1+ (0.00518798828125,-40) [0|0] "C"  TCM
 SG_ pixel20 : 320|16@1+ (0.00518798828125,-40) [0|0] "C"  TCM
 SG_ pixel21 : 336|16@1+ (0.00518798828125,-40) [0|0] "C"  TCM
 SG_ pixel22 : 352|16@1+ (0.00518798828125,-40) [0|0] "C"  TCM
 SG_ pixel23 : 368|16@1+ (0.00518798828125,-40) [0|0] "C"  TCM
 SG_ pixel24 : 384|16@1+ (0.00518798828125,-40) [0|0] "C"  TCM
 SG_ pixel25 : 400|16@1+ (0.00518798828125,-40) [0|0] "C"  TCM
 SG_ pixel26 : 416|16@1+ (0.00518798828125,-40) [0|0] "C"  TCM
 SG_ pixel27 : 432|16@1+ (0.00518798828125,-40) [0|0] "C"  TCM
 SG_ pixel28 : 448|16@1+ (0.00518798828125,-40) [0|0] "C"  TCM
 SG_ pixel29 : 464|16@1+ (0.00518798828125,-40) [0|0] "C"  TCM
 SG_ pixel30 : 480|16@1+ (0.00518798828125,-40) [0|0] "C"  TCM
 SG_ pixel31 : 496|16@1+ (0.00518798828125,-40) [0|0] "C"  TCM

BO_ 2164276228 TireTemp_FL_Frame_5_to_TCM: 64 TireTemp_FL
 SG_ pixel0 : 0|16@1+ (0.00518798828125,-40) [0|0] "C"  TCM
 SG_ pixel1 : 16|16@1+ (0.00518798828125,-40) [0|0] "C"  TCM
 SG_ pixel2 : 32|16@1+ (0.00518798828125,-40) [0|0] "C"  TCM
 SG_ pixel3 : 48|16@1+ (0.00518798828125,-40) [0|0] "C"  TCM
 SG_ pixel4 : 64|16@1+ (0.00518798828125,-40) [0|0] "C"  TCM
 SG_ pixel5 : 80|16@1+ (0.00518798828125,-40) [0|0] "C"  TCM
 SG_ pixel6 : 96|16@1+ (0.00518798828125,-40) [0|0] "C"  TCM
 SG_ pixel7 : 112|16@1+ (0.00518798828125,-40) [0|0] "C"  TCM
 SG_ pixel8 : 128|16@1+ (0.00518798828125,-40) [0|0] "C"  TCM
 SG_ pixel9 : 144|16@1+ (0.00518798828125,-40) [0|0] "C"  TCM
 SG_ pixel10 : 160|16@1+ (0.00518798828125,-40) [0|0] "C"  TCM
 SG_ pixel11 : 176|16@1+ (0.00518798828125,-40) [0|0] "C"  TCM
 SG_ pixel12 : 192|16@1+ (0.00518798828125,-40) [0|0] "C"  TCM
 SG_ pixel13 : 208|16@1+ (0.00518798828125,-40) [0|0] "C"  TCM
 SG_ pixel14 : 224|16@1+ (0.00518798828125,-40) [0|0] "C"  TCM
 SG_ pixel15 : 240|16@1+ (0.00518798828125,-40) [0|0] "C"  TCM
 SG_ pixel16 : 256|16@1+ (0.00518798828125,-40) [0|0] "C"  TCM
 SG_ pixel17 : 272|16@1+ (0.00518798828125,-40) [0|0] "C"  TCM
 SG_ pixel18 : 288|16@1+ (0.00518798828125,-40) [0|0] "C"  TCM
 SG_ pixel19 : 304|16@1+ (0.00518798828125,-40) [0|0] "C"  TCM
 SG_ pixel20 : 320|16@1+ (0.00518798828125,-40) [0|0] "C"  TCM
 SG_ pixel21 : 336|16@1+ (0.00518798828125,-40) [0|0] "C"  TCM
 SG_ pixel22 : 352|16@1+ (0.00518798828125,-40) [0|0] "C"  TCM
 SG_ pixel23 : 368|16@1+ (0.00518798828125,-40) [0|0] "C"  TCM
 SG_ pixel24 : 384|16@1+ (0.00518798828125,-40) [0|0] "C"  TCM
 SG_ pixel25 : 400|16@1+ (0.00518798828125,-40) [0|0] "C"  TCM
 SG_ pixel26 : 416|16@1+ (0.00518798828125,-40) [0|0] "C"  TCM
 SG_ pixel27 : 432|16@1+ (0.00518798828125,-40) [0|0] "C"  TCM
 SG_ pixel28 : 448|16@1+ (0.00518798828125,-40) [0|0] "C"  TCM
 SG_ pixel29 : 464|16@1+ (0.00518798828125,-40) [0|0] "C"  TCM
 SG_ pixel30 : 480|16@1+ (0.00518798828125,-40) [0|0] "C"  TCM
 SG_ pixel31 : 496|16@1+ (0.00518798828125,-40) [0|0] "C"  TCM

BO_ 2164276484 TireTemp_FL_Frame_6_to_TCM: 64 TireTemp_FL
 SG_ pixel0 : 0|16@1+ (0.00518798828125,-40) [0|0] "C"  TCM
 SG_ pixel1 : 16|16@1+ (0.00518798828125,-40) [0|0] "C"  TCM
 SG_ pixel2 : 32|16@1+ (0.00518798828125,-40) [0|0] "C"  TCM
 SG_ pixel3 : 48|16@1+ (0.00518798828125,-40) [0|0] "C"  TCM
 SG_ pixel4 : 64|16@1+ (0.00518798828125,-40) [0|0] "C"  TCM
 SG_ pixel5 : 80|16@1+ (0.00518798828125,-40) [0|0] "C"  TCM
 SG_ pixel6 : 96|16@1+ (0.00518798828125,-40) [0|0] "C"  TCM
 SG_ pixel7 : 112|16@1+ (0.00518798828125,-40) [0|0] "C"  TCM
 SG_ pixel8 : 128|16@1+ (0.00518798828125,-40) [0|0] "C"  TCM
 SG_ pixel9 : 144|16@1+ (0.00518798828125,-40) [0|0] "C"  TCM
 SG_ pixel10 : 160|16@1+ (0.00518798828125,-40) [0|0] "C"  TCM
 SG_ pixel11 : 176|16@1+ (0.00518798828125,-40) [0|0] "C"  TCM
 SG_ pixel12 : 192|16@1+ (0.00518798828125,-40) [0|0] "C"  TCM
 SG_ pixel13 : 208|16@1+ (0.00518798828125,-40) [0|0] "C"  TCM
 SG_ pixel14 : 224|16@1+ (0.00518798828125,-40) [0|0] "C"  TCM
 SG_ pixel15 : 240|16@1+ (0.00518798828125,-40) [0|0] "C"  TCM
 SG_ pixel16 : 256|16@1+ (0.00518798828125,-40) [0|0] "C"  TCM
 SG_ pixel17 : 272|16@1+ (0.00518798828125,-40) [0|0] "C"  TCM
 SG_ pixel18 : 288|16@1+ (0.00518798828125,-40) [0|0] "C"  TCM
 SG_ pixel19 : 304|16@1+ (0.00518798828125,-40) [0|0] "C"  TCM
 SG_ pixel20 : 320|16@1+ (0.00518798828125,-40) [0|0] "C"  TCM
 SG_ pixel21 : 336|16@1+ (0.00518798828125,-40) [0|0] "C"  TCM
 SG_ pixel22 : 352|16@1+ (0.00518798828125,-40) [0|0] "C"  TCM
 SG_ pixel23 : 368|16@1+ (0.00518798828125,-40) [0|0] "C"  TCM
 SG_ pixel24 : 384|16@1+ (0.00518798828125,-40) [0|0] "C"  TCM
 SG_ pixel25 : 400|16@1+ (0.00518798828125,-40) [0|0] "C"  TCM
 SG_ pixel26 : 416|16@1+ (0.00518798828125,-40) [0|0] "C"  TCM
 SG_ pixel27 : 432|16@1+ (0.00518798828125,-40) [0|0] "C"  TCM
 SG_ pixel28 : 448|16@1+ (0.00518798828125,-40) [0|0] "C"  TCM
 SG_ pixel29 : 464|16@1+ (0.00518798828125,-40) [0|0] "C"  TCM
 SG_ pixel30 : 480|16@1+ (0.00518798828125,-40) [0|0] "C"  TCM
 SG_ pixel31 : 496|16@1+ (0.00518798828125,-40) [0|0] "C"  TCM

BO_ 2164276740 TireTemp_FL_Frame_7_to_TCM: 64 TireTemp_FL
 SG_ pixel0 : 0|16@1+ (0.00518798828125,-40) [0|0] "C"  TCM
 SG_ pixel1 : 16|16@1+ (0.00518798828125,-40) [0|0] "C"  TCM
 SG_ pixel2 : 32|16@1+ (0.00518798828125,-40) [0|0] "C"  TCM
 SG_ pixel3 : 48|16@1+ (0.00518798828125,-40) [0|0] "C"  TCM
 SG_ pixel4 : 64|16@1+ (0.00518798828125,-40) [0|0] "C"  TCM
 SG_ pixel5 : 80|16@1+ (0.00518798828125,-40) [0|0] "C"  TCM
 SG_ pixel6 : 96|16@1+ (0.00518798828125,-40) [0|0] "C"  TCM
 SG_ pixel7 : 112|16@1+ (0.00518798828125,-40) [0|0] "C"  TCM
 SG_ pixel8 : 128|16@1+ (0.00518798828125,-40) [0|0] "C"  TCM
 SG_ pixel9 : 144|16@1+ (0.00518798828125,-40) [0|0] "C"  TCM
 SG_ pixel10 : 160|16@1+ (0.00518798828125,-40) [0|0] "C"  TCM
 SG_ pixel11 : 176|16@1+ (0.00518798828125,-40) [0|0] "C"  TCM
 SG_ pixel12 : 192|16@1+ (0.00518798828125,-40) [0|0] "C"  TCM
 SG_ pixel13 : 208|16@1+ (0.00518798828125,-40) [0|0] "C"  TCM
 SG_ pixel14 : 224|16@1+ (0.00518798828125,-40) [0|0] "C"  TCM
 SG_ pixel15 : 240|16@1+ (0.00518798828125,-40) [0|0] "C"  TCM
 SG_ pixel16 : 256|16@1+ (0.00518798828125,-40) [0|0] "C"  TCM
 SG_ pixel17 : 272|16@1+ (0.00518798828125,-40) [0|0] "C"  TCM
 SG_ pixel18 : 288|16@1+ (0.00518798828125,-40) [0|0] "C"  TCM
 SG_ pixel19 : 304|16@1+ (0.00518798828125,-40) [0|0] "C"  TCM
 SG_ pixel20 : 320|16@1+ (0.00518798828125,-40) [0|0] "C"  TCM
 SG_ pixel21 : 336|16@1+ (0.00518798828125,-40) [0|0] "C"  TCM
 SG_ pixel22 : 352|16@1+ (0.00518798828125,-40) [0|0] "C"  TCM
 SG_ pixel23 : 368|16@1+ (0.00518798828125,-40) [0|0] "C"  TCM
 SG_ pixel24 : 384|16@1+ (0.00518798828125,-40) [0|0] "C"  TCM
 SG_ pixel25 : 400|16@1+ (0.00518798828125,-40) [0|0] "C"  TCM
 SG_ pixel26 : 416|16@1+ (0.00518798828125,-40) [0|0] "C"  TCM
 SG_ pixel27 : 432|16@1+ (0.00518798828125,-40) [0|0] "C"  TCM
 SG_ pixel28 : 448|16@1+ (0.00518798828125,-40) [0|0] "C"  TCM
 SG_ pixel29 : 464|16@1+ (0.00518798828125,-40) [0|0] "C"  TCM
 SG_ pixel30 : 480|16@1+ (0.00518798828125,-40) [0|0] "C"  TCM
 SG_ pixel31 : 496|16@1+ (0.00518798828125,-40) [0|0] "C"  TCM

BO_ 2164276996 TireTemp_FL_Frame_8_to_TCM: 64 TireTemp_FL
 SG_ pixel0 : 0|16@1+ (0.00518798828125,-40) [0|0] "C"  TCM
 SG_ pixel1 : 16|16@1+ (0.00518798828125,-40) [0|0] "C"  TCM
 SG_ pixel2 : 32|16@1+ (0.00518798828125,-40) [0|0] "C"  TCM
 SG_ pixel3 : 48|16@1+ (0.00518798828125,-40) [0|0] "C"  TCM
 SG_ pixel4 : 64|16@1+ (0.00518798828125,-40) [0|0] "C"  TCM
 SG_ pixel5 : 80|16@1+ (0.00518798828125,-40) [0|0] "C"  TCM
 SG_ pixel6 : 96|16@1+ (0.00518798828125,-40) [0|0] "C"  TCM
 SG_ pixel7 : 112|16@1+ (0.00518798828125,-40) [0|0] "C"  TCM
 SG_ pixel8 : 128|16@1+ (0.00518798828125,-40) [0|0] "C"  TCM
 SG_ pixel9 : 144|16@1+ (0.00518798828125,-40) [0|0] "C"  TCM
 SG_ pixel10 : 160|16@1+ (0.00518798828125,-40) [0|0] "C"  TCM
 SG_ pixel11 : 176|16@1+ (0.00518798828125,-40) [0|0] "C"  TCM
 SG_ pixel12 : 192|16@1+ (0.00518798828125,-40) [0|0] "C"  TCM
 SG_ pixel13 : 208|16@1+ (0.00518798828125,-40) [0|0] "C"  TCM
 SG_ pixel14 : 224|16@1+ (0.00518798828125,-40) [0|0] "C"  TCM
 SG_ pixel15 : 240|16@1+ (0.00518798828125,-40) [0|0] "C"  TCM
 SG_ pixel16 : 256|16@1+ (0.00518798828125,-40) [0|0] "C"  TCM
 SG_ pixel17 : 272|16@1+ (0.00518798828125,-40) [0|0] "C"  TCM
 SG_ pixel18 : 288|16@1+ (0.00518798828125,-40) [0|0] "C"  TCM
 SG_ pixel19 : 304|16@1+ (0.00518798828125,-40) [0|0] "C"  TCM
 SG_ pixel20 : 320|16@1+ (0.00518798828125,-40) [0|0] "C"  TCM
 SG_ pixel21 : 336|16@1+ (0.00518798828125,-40) [0|0] "C"  TCM
 SG_ pixel22 : 352|16@1+ (0.00518798828125,-40) [0|0] "C"  TCM
 SG_ pixel23 : 368|16@1+ (0.00518798828125,-40) [0|0] "C"  TCM
 SG_ pixel24 : 384|16@1+ (0.00518798828125,-40) [0|0] "C"  TCM
 SG_ pixel25 : 400|16@1+ (0.00518798828125,-40) [0|0] "C"  TCM
 SG_ pixel26 : 416|16@1+ (0.00518798828125,-40) [0|0] "C"  TCM
 SG_ pixel27 : 432|16@1+ (0.00518798828125,-40) [0|0] "C"  TCM
 SG_ pixel28 : 448|16@1+ (0.00518798828125,-40) [0|0] "C"  TCM
 SG_ pixel29 : 464|16@1+ (0.00518798828125,-40) [0|0] "C"  TCM
 SG_ pixel30 : 480|16@1+ (0.00518798828125,-40) [0|0] "C"  TCM
 SG_ pixel31 : 496|16@1+ (0.00518798828125,-40) [0|0] "C"  TCM

BO_ 2164277252 TireTemp_FL_Frame_9_to_TCM: 64 TireTemp_FL
 SG_ pixel0 : 0|16@1+ (0.00518798828125,-40) [0|0] "C"  TCM
 SG_ pixel1 : 16|16@1+ (0.00518798828125,-40) [0|0] "C"  TCM
 SG_ pixel2 : 32|16@1+ (0.00518798828125,-40) [0|0] "C"  TCM
 SG_ pixel3 : 48|16@1+ (0.00518798828125,-40) [0|0] "C"  TCM
 SG_ pixel4 : 64|16@1+ (0.00518798828125,-40) [0|0] "C"  TCM
 SG_ pixel5 : 80|16@1+ (0.00518798828125,-40) [0|0] "C"  TCM
 SG_ pixel6 : 96|16@1+ (0.00518798828125,-40) [0|0] "C"  TCM
 SG_ pixel7 : 112|16@1+ (0.00518798828125,-40) [0|0] "C"  TCM
 SG_ pixel8 : 128|16@1+ (0.00518798828125,-40) [0|0] "C"  TCM
 SG_ pixel9 : 144|16@1+ (0.00518798828125,-40) [0|0] "C"  TCM
 SG_ pixel10 : 160|16@1+ (0.00518798828125,-40) [0|0] "C"  TCM
 SG_ pixel11 : 176|16@1+ (0.00518798828125,-40) [0|0] "C"  TCM
 SG_ pixel12 : 192|16@1+ (0.00518798828125,-40) [0|0] "C"  TCM
 SG_ pixel13 : 208|16@1+ (0.00518798828125,-40) [0|0] "C"  TCM
 SG_ pixel14 : 224|16@1+ (0.00518798828125,-40) [0|0] "C"  TCM
 SG_ pixel15 : 240|16@1+ (0.00518798828125,-40) [0|0] "C"  TCM
 SG_ pixel16 : 256|16@1+ (0.00518798828125,-40) [0|0] "C"  TCM
 SG_ pixel17 : 272|16@1+ (0.00518798828125,-40) [0|0] "C"  TCM
 SG_ pixel18 : 288|16@1+ (0.00518798828125,-40) [0|0] "C"  TCM
 SG_ pixel19 : 304|16@1+ (0.00518798828125,-40) [0|0] "C"  TCM
 SG_ pixel20 : 320|16@1+ (0.00518798828125,-40) [0|0] "C"  TCM
 SG_ pixel21 : 336|16@1+ (0.00518798828125,-40) [0|0] "C"  TCM
 SG_ pixel22 : 352|16@1+ (0.00518798828125,-40) [0|0] "C"  TCM
 SG_ pixel23 : 368|16@1+ (0.00518798828125,-40) [0|0] "C"  TCM
 SG_ pixel24 : 384|16@1+ (0.00518798828125,-40) [0|0] "C"  TCM
 SG_ pixel25 : 400|16@1+ (0.00518798828125,-40) [0|0] "C"  TCM
 SG_ pixel26 : 416|16@1+ (0.00518798828125,-40) [0|0] "C"  TCM
 SG_ pixel27 : 432|16@1+ (0.00518798828125,-40) [0|0] "C"  TCM
 SG_ pixel28 : 448|16@1+ (0.00518798828125,-40) [0|0] "C"  TCM
 SG_ pixel29 : 464|16@1+ (0.00518798828125,-40) [0|0] "C"  TCM
 SG_ pixel30 : 480|16@1+ (0.00518798828125,-40) [0|0] "C"  TCM
 SG_ pixel31 : 496|16@1+ (0.00518798828125,-40) [0|0] "C"  TCM

BO_ 2164277508 TireTemp_FL_Frame_10_to_TCM: 64 TireTemp_FL
 SG_ pixel0 : 0|16@1+ (0.00518798828125,-40) [0|0] "C"  TCM
 SG_ pixel1 : 16|16@1+ (0.00518798828125,-40) [0|0] "C"  TCM
 SG_ pixel2 : 32|16@1+ (0.00518798828125,-40) [0|0] "C"  TCM
 SG_ pixel3 : 48|16@1+ (0.00518798828125,-40) [0|0] "C"  TCM
 SG_ pixel4 : 64|16@1+ (0.00518798828125,-40) [0|0] "C"  TCM
 SG_ pixel5 : 80|16@1+ (0.00518798828125,-40) [0|0] "C"  TCM
 SG_ pixel6 : 96|16@1+ (0.00518798828125,-40) [0|0] "C"  TCM
 SG_ pixel7 : 112|16@1+ (0.00518798828125,-40) [0|0] "C"  TCM
 SG_ pixel8 : 128|16@1+ (0.00518798828125,-40) [0|0] "C"  TCM
 SG_ pixel9 : 144|16@1+ (0.00518798828125,-40) [0|0] "C"  TCM
 SG_ pixel10 : 160|16@1+ (0.00518798828125,-40) [0|0] "C"  TCM
 SG_ pixel11 : 176|16@1+ (0.00518798828125,-40) [0|0] "C"  TCM
 SG_ pixel12 : 192|16@1+ (0.00518798828125,-40) [0|0] "C"  TCM
 SG_ pixel13 : 208|16@1+ (0.00518798828125,-40) [0|0] "C"  TCM
 SG_ pixel14 : 224|16@1+ (0.00518798828125,-40) [0|0] "C"  TCM
 SG_ pixel15 : 240|16@1+ (0.00518798828125,-40) [0|0] "C"  TCM
 SG_ pixel16 : 256|16@1+ (0.00518798828125,-40) [0|0] "C"  TCM
 SG_ pixel17 : 272|16@1+ (0.00518798828125,-40) [0|0] "C"  TCM
 SG_ pixel18 : 288|16@1+ (0.00518798828125,-40) [0|0] "C"  TCM
 SG_ pixel19 : 304|16@1+ (0.00518798828125,-40) [0|0] "C"  TCM
 SG_ pixel20 : 320|16@1+ (0.00518798828125,-40) [0|0] "C"  TCM
 SG_ pixel21 : 336|16@1+ (0.00518798828125,-40) [0|0] "C"  TCM
 SG_ pixel22 : 352|16@1+ (0.00518798828125,-40) [0|0] "C"  TCM
 SG_ pixel23 : 368|16@1+ (0.00518798828125,-40) [0|0] "C"  TCM
 SG_ pixel24 : 384|16@1+ (0.00518798828125,-40) [0|0] "C"  TCM
 SG_ pixel25 : 400|16@1+ (0.00518798828125,-40) [0|0] "C"  TCM
 SG_ pixel26 : 416|16@1+ (0.00518798828125,-40) [0|0] "C"  TCM
 SG_ pixel27 : 432|16@1+ (0.00518798828125,-40) [0|0] "C"  TCM
 SG_ pixel28 : 448|16@1+ (0.00518798828125,-40) [0|0] "C"  TCM
 SG_ pixel29 : 464|16@1+ (0.00518798828125,-40) [0|0] "C"  TCM
 SG_ pixel30 : 480|16@1+ (0.00518798828125,-40) [0|0] "C"  TCM
 SG_ pixel31 : 496|16@1+ (0.00518798828125,-40) [0|0] "C"  TCM

BO_ 2164277764 TireTemp_FL_Frame_11_to_TCM: 64 TireTemp_FL
 SG_ pixel0 : 0|16@1+ (0.00518798828125,-40) [0|0] "C"  TCM
 SG_ pixel1 : 16|16@1+ (0.00518798828125,-40) [0|0] "C"  TCM
 SG_ pixel2 : 32|16@1+ (0.00518798828125,-40) [0|0] "C"  TCM
 SG_ pixel3 : 48|16@1+ (0.00518798828125,-40) [0|0] "C"  TCM
 SG_ pixel4 : 64|16@1+ (0.00518798828125,-40) [0|0] "C"  TCM
 SG_ pixel5 : 80|16@1+ (0.00518798828125,-40) [0|0] "C"  TCM
 SG_ pixel6 : 96|16@1+ (0.00518798828125,-40) [0|0] "C"  TCM
 SG_ pixel7 : 112|16@1+ (0.00518798828125,-40) [0|0] "C"  TCM
 SG_ pixel8 : 128|16@1+ (0.00518798828125,-40) [0|0] "C"  TCM
 SG_ pixel9 : 144|16@1+ (0.00518798828125,-40) [0|0] "C"  TCM
 SG_ pixel10 : 160|16@1+ (0.00518798828125,-40) [0|0] "C"  TCM
 SG_ pixel11 : 176|16@1+ (0.00518798828125,-40) [0|0] "C"  TCM
 SG_ pixel12 : 192|16@1+ (0.00518798828125,-40) [0|0] "C"  TCM
 SG_ pixel13 : 208|16@1+ (0.00518798828125,-40) [0|0] "C"  TCM
 SG_ pixel14 : 224|16@1+ (0.00518798828125,-40) [0|0] "C"  TCM
 SG_ pixel15 : 240|16@1+ (0.00518798828125,-40) [0|0] "C"  TCM
 SG_ pixel16 : 256|16@1+ (0.00518798828125,-40) [0|0] "C"  TCM
 SG_ pixel17 : 272|16@1+ (0.00518798828125,-40) [0|0] "C"  TCM
 SG_ pixel18 : 288|16@1+ (0.00518798828125,-40) [0|0] "C"  TCM
 SG_ pixel19 : 304|16@1+ (0.00518798828125,-40) [0|0] "C"  TCM
 SG_ pixel20 : 320|16@1+ (0.00518798828125,-40) [0|0] "C"  TCM
 SG_ pixel21 : 336|16@1+ (0.00518798828125,-40) [0|0] "C"  TCM
 SG_ pixel22 : 352|16@1+ (0.00518798828125,-40) [0|0] "C"  TCM
 SG_ pixel23 : 368|16@1+ (0.00518798828125,-40) [0|0] "C"  TCM
 SG_ pixel24 : 384|16@1+ (0.00518798828125,-40) [0|0] "C"  TCM
 SG_ pixel25 : 400|16@1+ (0.00518798828125,-40) [0|0] "C"  TCM
 SG_ pixel26 : 416|16@1+ (0.00518798828125,-40) [0|0] "C"  TCM
 SG_ pixel27 : 432|16@1+ (0.00518798828125,-40) [0|0] "C"  TCM
 SG_ pixel28 : 448|16@1+ (0.00518798828125,-40) [0|0] "C"  TCM
 SG_ pixel29 : 464|16@1+ (0.00518798828125,-40) [0|0] "C"  TCM
 SG_ pixel30 : 480|16@1+ (0.00518798828125,-40) [0|0] "C"  TCM
 SG_ pixel31 : 496|16@1+ (0.00518798828125,-40) [0|0] "C"  TCM

BO_ 2164278020 TireTemp_FL_Frame_12_to_TCM: 64 TireTemp_FL
 SG_ pixel0 : 0|16@1+ (0.00518798828125,-40) [0|0] "C"  TCM
 SG_ pixel1 : 16|16@1+ (0.00518798828125,-40) [0|0] "C"  TCM
 SG_ pixel2 : 32|16@1+ (0.00518798828125,-40) [0|0] "C"  TCM
 SG_ pixel3 : 48|16@1+ (0.00518798828125,-40) [0|0] "C"  TCM
 SG_ pixel4 : 64|16@1+ (0.00518798828125,-40) [0|0] "C"  TCM
 SG_ pixel5 : 80|16@1+ (0.00518798828125,-40) [0|0] "C"  TCM
 SG_ pixel6 : 96|16@1+ (0.00518798828125,-40) [0|0] "C"  TCM
 SG_ pixel7 : 112|16@1+ (0.00518798828125,-40) [0|0] "C"  TCM
 SG_ pixel8 : 128|16@1+ (0.00518798828125,-40) [0|0] "C"  TCM
 SG_ pixel9 : 144|16@1+ (0.00518798828125,-40) [0|0] "C"  TCM
 SG_ pixel10 : 160|16@1+ (0.00518798828125,-40) [0|0] "C"  TCM
 SG_ pixel11 : 176|16@1+ (0.00518798828125,-40) [0|0] "C"  TCM
 SG_ pixel12 : 192|16@1+ (0.00518798828125,-40) [0|0] "C"  TCM
 SG_ pixel13 : 208|16@1+ (0.00518798828125,-40) [0|0] "C"  TCM
 SG_ pixel14 : 224|16@1+ (0.00518798828125,-40) [0|0] "C"  TCM
 SG_ pixel15 : 240|16@1+ (0.00518798828125,-40) [0|0] "C"  TCM
 SG_ pixel16 : 256|16@1+ (0.00518798828125,-40) [0|0] "C"  TCM
 SG_ pixel17 : 272|16@1+ (0.00518798828125,-40) [0|0] "C"  TCM
 SG_ pixel18 : 288|16@1+ (0.00518798828125,-40) [0|0] "C"  TCM
 SG_ pixel19 : 304|16@1+ (0.00518798828125,-40) [0|0] "C"  TCM
 SG_ pixel20 : 320|16@1+ (0.00518798828125,-40) [0|0] "C"  TCM
 SG_ pixel21 : 336|16@1+ (0.00518798828125,-40) [0|0] "C"  TCM
 SG_ pixel22 : 352|16@1+ (0.00518798828125,-40) [0|0] "C"  TCM
 SG_ pixel23 : 368|16@1+ (0.00518798828125,-40) [0|0] "C"  TCM
 SG_ pixel24 : 384|16@1+ (0.00518798828125,-40) [0|0] "C"  TCM
 SG_ pixel25 : 400|16@1+ (0.00518798828125,-40) [0|0] "C"  TCM
 SG_ pixel26 : 416|16@1+ (0.00518798828125,-40) [0|0] "C"  TCM
 SG_ pixel27 : 432|16@1+ (0.00518798828125,-40) [0|0] "C"  TCM
 SG_ pixel28 : 448|16@1+ (0.00518798828125,-40) [0|0] "C"  TCM
 SG_ pixel29 : 464|16@1+ (0.00518798828125,-40) [0|0] "C"  TCM
 SG_ pixel30 : 480|16@1+ (0.00518798828125,-40) [0|0] "C"  TCM
 SG_ pixel31 : 496|16@1+ (0.00518798828125,-40) [0|0] "C"  TCM

BO_ 2164278276 TireTemp_FL_Frame_13_to_TCM: 64 TireTemp_FL
 SG_ pixel0 : 0|16@1+ (0.00518798828125,-40) [0|0] "C"  TCM
 SG_ pixel1 : 16|16@1+ (0.00518798828125,-40) [0|0] "C"  TCM
 SG_ pixel2 : 32|16@1+ (0.00518798828125,-40) [0|0] "C"  TCM
 SG_ pixel3 : 48|16@1+ (0.00518798828125,-40) [0|0] "C"  TCM
 SG_ pixel4 : 64|16@1+ (0.00518798828125,-40) [0|0] "C"  TCM
 SG_ pixel5 : 80|16@1+ (0.00518798828125,-40) [0|0] "C"  TCM
 SG_ pixel6 : 96|16@1+ (0.00518798828125,-40) [0|0] "C"  TCM
 SG_ pixel7 : 112|16@1+ (0.00518798828125,-40) [0|0] "C"  TCM
 SG_ pixel8 : 128|16@1+ (0.00518798828125,-40) [0|0] "C"  TCM
 SG_ pixel9 : 144|16@1+ (0.00518798828125,-40) [0|0] "C"  TCM
 SG_ pixel10 : 160|16@1+ (0.00518798828125,-40) [0|0] "C"  TCM
 SG_ pixel11 : 176|16@1+ (0.00518798828125,-40) [0|0] "C"  TCM
 SG_ pixel12 : 192|16@1+ (0.00518798828125,-40) [0|0] "C"  TCM
 SG_ pixel13 : 208|16@1+ (0.00518798828125,-40) [0|0] "C"  TCM
 SG_ pixel14 : 224|16@1+ (0.00518798828125,-40) [0|0] "C"  TCM
 SG_ pixel15 : 240|16@1+ (0.00518798828125,-40) [0|0] "C"  TCM
 SG_ pixel16 : 256|16@1+ (0.00518798828125,-40) [0|0] "C"  TCM
 SG_ pixel17 : 272|16@1+ (0.00518798828125,-40) [0|0] "C"  TCM
 SG_ pixel18 : 288|16@1+ (0.00518798828125,-40) [0|0] "C"  TCM
 SG_ pixel19 : 304|16@1+ (0.00518798828125,-40) [0|0] "C"  TCM
 SG_ pixel20 : 320|16@1+ (0.00518798828125,-40) [0|0] "C"  TCM
 SG_ pixel21 : 336|16@1+ (0.00518798828125,-40) [0|0] "C"  TCM
 SG_ pixel22 : 352|16@1+ (0.00518798828125,-40) [0|0] "C"  TCM
 SG_ pixel23 : 368|16@1+ (0.00518798828125,-40) [0|0] "C"  TCM
 SG_ pixel24 : 384|16@1+ (0.00518798828125,-40) [0|0] "C"  TCM
 SG_ pixel25 : 400|16@1+ (0.00518798828125,-40) [0|0] "C"  TCM
 SG_ pixel26 : 416|16@1+ (0.00518798828125,-40) [0|0] "C"  TCM
 SG_ pixel27 : 432|16@1+ (0.00518798828125,-40) [0|0] "C"  TCM
 SG_ pixel28 : 448|16@1+ (0.00518798828125,-40) [0|0] "C"  TCM
 SG_ pixel29 : 464|16@1+ (0.00518798828125,-40) [0|0] "C"  TCM
 SG_ pixel30 : 480|16@1+ (0.00518798828125,-40) [0|0] "C"  TCM
 SG_ pixel31 : 496|16@1+ (0.00518798828125,-40) [0|0] "C"  TCM

BO_ 2164278532 TireTemp_FL_Frame_14_to_TCM: 64 TireTemp_FL
 SG_ pixel0 : 0|16@1+ (0.00518798828125,-40) [0|0] "C"  TCM
 SG_ pixel1 : 16|16@1+ (0.00518798828125,-40) [0|0] "C"  TCM
 SG_ pixel2 : 32|16@1+ (0.00518798828125,-40) [0|0] "C"  TCM
 SG_ pixel3 : 48|16@1+ (0.00518798828125,-40) [0|0] "C"  TCM
 SG_ pixel4 : 64|16@1+ (0.00518798828125,-40) [0|0] "C"  TCM
 SG_ pixel5 : 80|16@1+ (0.00518798828125,-40) [0|0] "C"  TCM
 SG_ pixel6 : 96|16@1+ (0.00518798828125,-40) [0|0] "C"  TCM
 SG_ pixel7 : 112|16@1+ (0.00518798828125,-40) [0|0] "C"  TCM
 SG_ pixel8 : 128|16@1+ (0.00518798828125,-40) [0|0] "C"  TCM
 SG_ pixel9 : 144|16@1+ (0.00518798828125,-40) [0|0] "C"  TCM
 SG_ pixel10 : 160|16@1+ (0.00518798828125,-40) [0|0] "C"  TCM
 SG_ pixel11 : 176|16@1+ (0.00518798828125,-40) [0|0] "C"  TCM
 SG_ pixel12 : 192|16@1+ (0.00518798828125,-40) [0|0] "C"  TCM
 SG_ pixel13 : 208|16@1+ (0.00518798828125,-40) [0|0] "C"  TCM
 SG_ pixel14 : 224|16@1+ (0.00518798828125,-40) [0|0] "C"  TCM
 SG_ pixel15 : 240|16@1+ (0.00518798828125,-40) [0|0] "C"  TCM
 SG_ pixel16 : 256|16@1+ (0.00518798828125,-40) [0|0] "C"  TCM
 SG_ pixel17 : 272|16@1+ (0.00518798828125,-40) [0|0] "C"  TCM
 SG_ pixel18 : 288|16@1+ (0.00518798828125,-40) [0|0] "C"  TCM
 SG_ pixel19 : 304|16@1+ (0.00518798828125,-40) [0|0] "C"  TCM
 SG_ pixel20 : 320|16@1+ (0.00518798828125,-40) [0|0] "C"  TCM
 SG_ pixel21 : 336|16@1+ (0.00518798828125,-40) [0|0] "C"  TCM
 SG_ pixel22 : 352|16@1+ (0.00518798828125,-40) [0|0] "C"  TCM
 SG_ pixel23 : 368|16@1+ (0.00518798828125,-40) [0|0] "C"  TCM
 SG_ pixel24 : 384|16@1+ (0.00518798828125,-40) [0|0] "C"  TCM
 SG_ pixel25 : 400|16@1+ (0.00518798828125,-40) [0|0] "C"  TCM
 SG_ pixel26 : 416|16@1+ (0.00518798828125,-40) [0|0] "C"  TCM
 SG_ pixel27 : 432|16@1+ (0.00518798828125,-40) [0|0] "C"  TCM
 SG_ pixel28 : 448|16@1+ (0.00518798828125,-40) [0|0] "C"  TCM
 SG_ pixel29 : 464|16@1+ (0.00518798828125,-40) [0|0] "C"  TCM
 SG_ pixel30 : 480|16@1+ (0.00518798828125,-40) [0|0] "C"  TCM
 SG_ pixel31 : 496|16@1+ (0.00518798828125,-40) [0|0] "C"  TCM

BO_ 2164278788 TireTemp_FL_Frame_15_to_TCM: 64 TireTemp_FL
 SG_ pixel0 : 0|16@1+ (0.00518798828125,-40) [0|0] "C"  TCM
 SG_ pixel1 : 16|16@1+ (0.00518798828125,-40) [0|0] "C"  TCM
 SG_ pixel2 : 32|16@1+ (0.00518798828125,-40) [0|0] "C"  TCM
 SG_ pixel3 : 48|16@1+ (0.00518798828125,-40) [0|0] "C"  TCM
 SG_ pixel4 : 64|16@1+ (0.00518798828125,-40) [0|0] "C"  TCM
 SG_ pixel5 : 80|16@1+ (0.00518798828125,-40) [0|0] "C"  TCM
 SG_ pixel6 : 96|16@1+ (0.00518798828125,-40) [0|0] "C"  TCM
 SG_ pixel7 : 112|16@1+ (0.00518798828125,-40) [0|0] "C"  TCM
 SG_ pixel8 : 128|16@1+ (0.00518798828125,-40) [0|0] "C"  TCM
 SG_ pixel9 : 144|16@1+ (0.00518798828125,-40) [0|0] "C"  TCM
 SG_ pixel10 : 160|16@1+ (0.00518798828125,-40) [0|0] "C"  TCM
 SG_ pixel11 : 176|16@1+ (0.00518798828125,-40) [0|0] "C"  TCM
 SG_ pixel12 : 192|16@1+ (0.00518798828125,-40) [0|0] "C"  TCM
 SG_ pixel13 : 208|16@1+ (0.00518798828125,-40) [0|0] "C"  TCM
 SG_ pixel14 : 224|16@1+ (0.00518798828125,-40) [0|0] "C"  TCM
 SG_ pixel15 : 240|16@1+ (0.00518798828125,-40) [0|0] "C"  TCM
 SG_ pixel16 : 256|16@1+ (0.00518798828125,-40) [0|0] "C"  TCM
 SG_ pixel17 : 272|16@1+ (0.00518798828125,-40) [0|0] "C"  TCM
 SG_ pixel18 : 288|16@1+ (0.00518798828125,-40) [0|0] "C"  TCM
 SG_ pixel19 : 304|16@1+ (0.00518798828125,-40) [0|0] "C"  TCM
 SG_ pixel20 : 320|16@1+ (0.00518798828125,-40) [0|0] "C"  TCM
 SG_ pixel21 : 336|16@1+ (0.00518798828125,-40) [0|0] "C"  TCM
 SG_ pixel22 : 352|16@1+ (0.00518798828125,-40) [0|0] "C"  TCM
 SG_ pixel23 : 368|16@1+ (0.00518798828125,-40) [0|0] "C"  TCM
 SG_ pixel24 : 384|16@1+ (0.00518798828125,-40) [0|0] "C"  TCM
 SG_ pixel25 : 400|16@1+ (0.00518798828125,-40) [0|0] "C"  TCM
 SG_ pixel26 : 416|16@1+ (0.00518798828125,-40) [0|0] "C"  TCM
 SG_ pixel27 : 432|16@1+ (0.00518798828125,-40) [0|0] "C"  TCM
 SG_ pixel28 : 448|16@1+ (0.00518798828125,-40) [0|0] "C"  TCM
 SG_ pixel29 : 464|16@1+ (0.00518798828125,-40) [0|0] "C"  TCM
 SG_ pixel30 : 480|16@1+ (0.00518798828125,-40) [0|0] "C"  TCM
 SG_ pixel31 : 496|16@1+ (0.00518798828125,-40) [0|0] "C"  TCM

CM_ BO_ 2150629633 "Essentially a print statement up to 64 bytes long that whichever targeted can parse";
CM_ BO_ 2148532482 "Essentially a print statement up to 64 bytes long that whichever targeted can parse";
CM_ BO_ 2148532483 "Essentially a print statement up to 64 bytes long that whichever targeted can parse";
CM_ BO_ 2148532484 "Essentially a print statement up to 64 bytes long that whichever targeted can parse";
CM_ BO_ 2149581057 "Essentially a print statement up to 64 bytes long that whichever targeted can parse";
CM_ SG_ 2183159554 button_flags "[Byte 0 / Bits 0-7] bit 0 (mask 0x01) left held. Bit 1 (mask 0x02) right held. Bits 2-7 Reserved";
CM_ SG_ 2150629889 Timestamp "Time in millis";
CM_ SG_ 2150629890 Timestamp "Time in millis";
CM_ SG_ 2150632706 Cell_0_Voltage "Cell  n voltage";
CM_ SG_ 2150632706 Cell_0_Temp "Cell n Temp";
CM_ SG_ 2150632706 Cell_1_Voltage "Cell  n voltage";
CM_ SG_ 2150632706 Cell_1_Temp "Cell n Temp";
CM_ SG_ 2150632706 Cell_2_Voltage "Cell  n voltage";
CM_ SG_ 2150632706 Cell_2_Temp "Cell n Temp";
CM_ SG_ 2150632706 Cell_3_Voltage "Cell  n voltage";
CM_ SG_ 2150632706 Cell_3_Temp "Cell n Temp";
CM_ SG_ 2150632706 Cell_4_Voltage "Cell  n voltage";
CM_ SG_ 2150632706 Cell_4_Temp "Cell n Temp";
CM_ SG_ 2150632706 Cell_5_Voltage "Cell  n voltage";
CM_ SG_ 2150632706 Cell_5_Temp "Cell n Temp";
CM_ SG_ 2150632706 Cell_6_Voltage "Cell  n voltage";
CM_ SG_ 2150632706 Cell_6_Temp "Cell n Temp";
CM_ SG_ 2150632706 Cell_7_Voltage "Cell  n voltage";
CM_ SG_ 2150632706 Cell_7_Temp "Cell n Temp";
CM_ SG_ 2150632706 Cell_8_Voltage "Cell  n voltage";
CM_ SG_ 2150632706 Cell_8_Temp "Cell n Temp";
CM_ SG_ 2150632706 Cell_9_Voltage "Cell  n voltage";
CM_ SG_ 2150632706 Cell_9_Temp "Cell n Temp";
CM_ SG_ 2150632706 Cell_10_Voltage "Cell  n voltage";
CM_ SG_ 2150632706 Cell_10_Temp "Cell n Temp";
CM_ SG_ 2150632706 Cell_11_Voltage "Cell  n voltage";
CM_ SG_ 2150632706 Cell_11_Temp "Cell n Temp";
CM_ SG_ 2150632706 Cell_12_Voltage "Cell  n voltage";
CM_ SG_ 2150632706 Cell_12_Temp "Cell n Temp";
CM_ SG_ 2150632706 Cell_13_Voltage "Cell  n voltage";
CM_ SG_ 2150632706 Cell_13_Temp "Cell n Temp";
CM_ SG_ 2150632706 Cell_14_Voltage "Cell  n voltage";
CM_ SG_ 2150632706 Cell_14_Temp "Cell n Temp";
CM_ SG_ 2150632706 Cell_15_Voltage "Cell  n voltage";
CM_ SG_ 2150632706 Cell_15_Temp "Cell n Temp";
CM_ SG_ 2150632706 Cell_16_Voltage "Cell  n voltage";
CM_ SG_ 2150632706 Cell_16_Temp "Cell n Temp";
CM_ SG_ 2150632706 Cell_17_Voltage "Cell  n voltage";
CM_ SG_ 2150632706 Cell_17_Temp "Cell n Temp";
CM_ SG_ 2150632706 Cell_18_Voltage "Cell  n voltage";
CM_ SG_ 2150632706 Cell_18_Temp "Cell n Temp";
CM_ SG_ 2150632706 Cell_19_Voltage "Cell  n voltage";
CM_ SG_ 2150632706 Cell_19_Temp "Cell n Temp";
CM_ SG_ 2150632706 Cell_20_Voltage "Cell  n voltage";
CM_ SG_ 2150632706 Cell_20_Temp "Cell n Temp";
CM_ SG_ 2150632706 Cell_21_Voltage "Cell  n voltage";
CM_ SG_ 2150632706 Cell_21_Temp "Cell n Temp";
CM_ SG_ 2150632706 Cell_22_Voltage "Cell  n voltage";
CM_ SG_ 2150632706 Cell_22_Temp "Cell n Temp";
CM_ SG_ 2150632706 Cell_23_Voltage "Cell  n voltage";
CM_ SG_ 2150632706 Cell_23_Temp "Cell n Temp";
CM_ SG_ 2150632706 Cell_24_Voltage "Cell  n voltage";
CM_ SG_ 2150632706 Cell_24_Temp "Cell n Temp";
CM_ SG_ 2150632706 Cell_25_Voltage "Cell  n voltage";
CM_ SG_ 2150632706 Cell_25_Temp "Cell n Temp";
CM_ SG_ 2150632706 Cell_26_Voltage "Cell  n voltage";
CM_ SG_ 2150632706 Cell_26_Temp "Cell n Temp";
CM_ SG_ 2150632706 Cell_27_Voltage "Cell  n voltage";
CM_ SG_ 2150632706 Cell_27_Temp "Cell n Temp";
CM_ SG_ 2150632706 Cell_28_Voltage "Cell  n voltage";
CM_ SG_ 2150632706 Cell_28_Temp "Cell n Temp";
CM_ SG_ 2150632706 Cell_29_Voltage "Cell  n voltage";
CM_ SG_ 2150632706 Cell_29_Temp "Cell n Temp";
CM_ SG_ 2150632706 Cell_30_Voltage "Cell  n voltage";
CM_ SG_ 2150632706 Cell_30_Temp "Cell n Temp";
CM_ SG_ 2150632706 Cell_31_Voltage "Cell  n voltage";
CM_ SG_ 2150632706 Cell_31_Temp "Cell n Temp";
CM_ SG_ 2150632962 Cell_32_Voltage "Cell  n voltage";
CM_ SG_ 2150632962 Cell_32_Temp "Cell n Temp";
CM_ SG_ 2150632962 Cell_33_Voltage "Cell  n voltage";
CM_ SG_ 2150632962 Cell_33_Temp "Cell n Temp";
CM_ SG_ 2150632962 Cell_34_Voltage "Cell  n voltage";
CM_ SG_ 2150632962 Cell_34_Temp "Cell n Temp";
CM_ SG_ 2150632962 Cell_35_Voltage "Cell  n voltage";
CM_ SG_ 2150632962 Cell_35_Temp "Cell n Temp";
CM_ SG_ 2150632962 Cell_36_Voltage "Cell  n voltage";
CM_ SG_ 2150632962 Cell_36_Temp "Cell n Temp";
CM_ SG_ 2150632962 Cell_37_Voltage "Cell  n voltage";
CM_ SG_ 2150632962 Cell_37_Temp "Cell n Temp";
CM_ SG_ 2150632962 Cell_38_Voltage "Cell  n voltage";
CM_ SG_ 2150632962 Cell_38_Temp "Cell n Temp";
CM_ SG_ 2150632962 Cell_39_Voltage "Cell  n voltage";
CM_ SG_ 2150632962 Cell_39_Temp "Cell n Temp";
CM_ SG_ 2150632962 Cell_40_Voltage "Cell  n voltage";
CM_ SG_ 2150632962 Cell_40_Temp "Cell n Temp";
CM_ SG_ 2150632962 Cell_41_Voltage "Cell  n voltage";
CM_ SG_ 2150632962 Cell_41_Temp "Cell n Temp";
CM_ SG_ 2150632962 Cell_42_Voltage "Cell  n voltage";
CM_ SG_ 2150632962 Cell_42_Temp "Cell n Temp";
CM_ SG_ 2150632962 Cell_43_Voltage "Cell  n voltage";
CM_ SG_ 2150632962 Cell_43_Temp "Cell n Temp";
CM_ SG_ 2150632962 Cell_44_Voltage "Cell  n voltage";
CM_ SG_ 2150632962 Cell_44_Temp "Cell n Temp";
CM_ SG_ 2150632962 Cell_45_Voltage "Cell  n voltage";
CM_ SG_ 2150632962 Cell_45_Temp "Cell n Temp";
CM_ SG_ 2150632962 Cell_46_Voltage "Cell  n voltage";
CM_ SG_ 2150632962 Cell_46_Temp "Cell n Temp";
CM_ SG_ 2150632962 Cell_47_Voltage "Cell  n voltage";
CM_ SG_ 2150632962 Cell_47_Temp "Cell n Temp";
CM_ SG_ 2150632962 Cell_48_Voltage "Cell  n voltage";
CM_ SG_ 2150632962 Cell_48_Temp "Cell n Temp";
CM_ SG_ 2150632962 Cell_49_Voltage "Cell  n voltage";
CM_ SG_ 2150632962 Cell_49_Temp "Cell n Temp";
CM_ SG_ 2150632962 Cell_50_Voltage "Cell  n voltage";
CM_ SG_ 2150632962 Cell_50_Temp "Cell n Temp";
CM_ SG_ 2150632962 Cell_51_Voltage "Cell  n voltage";
CM_ SG_ 2150632962 Cell_51_Temp "Cell n Temp";
CM_ SG_ 2150632962 Cell_52_Voltage "Cell  n voltage";
CM_ SG_ 2150632962 Cell_52_Temp "Cell n Temp";
CM_ SG_ 2150632962 Cell_53_Voltage "Cell  n voltage";
CM_ SG_ 2150632962 Cell_53_Temp "Cell n Temp";
CM_ SG_ 2150632962 Cell_54_Voltage "Cell  n voltage";
CM_ SG_ 2150632962 Cell_54_Temp "Cell n Temp";
CM_ SG_ 2150632962 Cell_55_Voltage "Cell  n voltage";
CM_ SG_ 2150632962 Cell_55_Temp "Cell n Temp";
CM_ SG_ 2150632962 Cell_56_Voltage "Cell  n voltage";
CM_ SG_ 2150632962 Cell_56_Temp "Cell n Temp";
CM_ SG_ 2150632962 Cell_57_Voltage "Cell  n voltage";
CM_ SG_ 2150632962 Cell_57_Temp "Cell n Temp";
CM_ SG_ 2150632962 Cell_58_Voltage "Cell  n voltage";
CM_ SG_ 2150632962 Cell_58_Temp "Cell n Temp";
CM_ SG_ 2150632962 Cell_59_Voltage "Cell  n voltage";
CM_ SG_ 2150632962 Cell_59_Temp "Cell n Temp";
CM_ SG_ 2150632962 Cell_60_Voltage "Cell  n voltage";
CM_ SG_ 2150632962 Cell_60_Temp "Cell n Temp";
CM_ SG_ 2150632962 Cell_61_Voltage "Cell  n voltage";
CM_ SG_ 2150632962 Cell_61_Temp "Cell n Temp";
CM_ SG_ 2150632962 Cell_62_Voltage "Cell  n voltage";
CM_ SG_ 2150632962 Cell_62_Temp "Cell n Temp";
CM_ SG_ 2150632962 Cell_63_Voltage "Cell  n voltage";
CM_ SG_ 2150632962 Cell_63_Temp "Cell n Temp";
CM_ SG_ 2150633218 Cell_64_Voltage "Cell  n voltage";
CM_ SG_ 2150633218 Cell_64_Temp "Cell n Temp";
CM_ SG_ 2150633218 Cell_65_Voltage "Cell  n voltage";
CM_ SG_ 2150633218 Cell_65_Temp "Cell n Temp";
CM_ SG_ 2150633218 Cell_66_Voltage "Cell  n voltage";
CM_ SG_ 2150633218 Cell_66_Temp "Cell n Temp";
CM_ SG_ 2150633218 Cell_67_Voltage "Cell  n voltage";
CM_ SG_ 2150633218 Cell_67_Temp "Cell n Temp";
CM_ SG_ 2150633218 Cell_68_Voltage "Cell  n voltage";
CM_ SG_ 2150633218 Cell_68_Temp "Cell n Temp";
CM_ SG_ 2150633218 Cell_69_Voltage "Cell  n voltage";
CM_ SG_ 2150633218 Cell_69_Temp "Cell n Temp";
CM_ SG_ 2150633218 Cell_70_Voltage "Cell  n voltage";
CM_ SG_ 2150633218 Cell_70_Temp "Cell n Temp";
CM_ SG_ 2150633218 Cell_71_Voltage "Cell  n voltage";
CM_ SG_ 2150633218 Cell_71_Temp "Cell n Temp";
CM_ SG_ 2150633218 Cell_72_Voltage "Cell  n voltage";
CM_ SG_ 2150633218 Cell_72_Temp "Cell n Temp";
CM_ SG_ 2150633218 Cell_73_Voltage "Cell  n voltage";
CM_ SG_ 2150633218 Cell_73_Temp "Cell n Temp";
CM_ SG_ 2150633218 Cell_74_Voltage "Cell  n voltage";
CM_ SG_ 2150633218 Cell_74_Temp "Cell n Temp";
CM_ SG_ 2150633218 Cell_75_Voltage "Cell  n voltage";
CM_ SG_ 2150633218 Cell_75_Temp "Cell n Temp";
CM_ SG_ 2150633218 Cell_76_Voltage "Cell  n voltage";
CM_ SG_ 2150633218 Cell_76_Temp "Cell n Temp";
CM_ SG_ 2150633218 Cell_77_Voltage "Cell  n voltage";
CM_ SG_ 2150633218 Cell_77_Temp "Cell n Temp";
CM_ SG_ 2150633218 Cell_78_Voltage "Cell  n voltage";
CM_ SG_ 2150633218 Cell_78_Temp "Cell n Temp";
CM_ SG_ 2150633218 Cell_79_Voltage "Cell  n voltage";
CM_ SG_ 2150633218 Cell_79_Temp "Cell n Temp";
CM_ SG_ 2150633218 Cell_80_Voltage "Cell  n voltage";
CM_ SG_ 2150633218 Cell_80_Temp "Cell n Temp";
CM_ SG_ 2150633218 Cell_81_Voltage "Cell  n voltage";
CM_ SG_ 2150633218 Cell_81_Temp "Cell n Temp";
CM_ SG_ 2150633218 Cell_82_Voltage "Cell  n voltage";
CM_ SG_ 2150633218 Cell_82_Temp "Cell n Temp";
CM_ SG_ 2150633218 Cell_83_Voltage "Cell  n voltage";
CM_ SG_ 2150633218 Cell_83_Temp "Cell n Temp";
CM_ SG_ 2150633218 Cell_84_Voltage "Cell  n voltage";
CM_ SG_ 2150633218 Cell_84_Temp "Cell n Temp";
CM_ SG_ 2150633218 Cell_85_Voltage "Cell  n voltage";
CM_ SG_ 2150633218 Cell_85_Temp "Cell n Temp";
CM_ SG_ 2150633218 Cell_86_Voltage "Cell  n voltage";
CM_ SG_ 2150633218 Cell_86_Temp "Cell n Temp";
CM_ SG_ 2150633218 Cell_87_Voltage "Cell  n voltage";
CM_ SG_ 2150633218 Cell_87_Temp "Cell n Temp";
CM_ SG_ 2150633218 Cell_88_Voltage "Cell  n voltage";
CM_ SG_ 2150633218 Cell_88_Temp "Cell n Temp";
CM_ SG_ 2150633218 Cell_89_Voltage "Cell  n voltage";
CM_ SG_ 2150633218 Cell_89_Temp "Cell n Temp";
CM_ SG_ 2150633218 Cell_90_Voltage "Cell  n voltage";
CM_ SG_ 2150633218 Cell_90_Temp "Cell n Temp";
CM_ SG_ 2150633218 Cell_91_Voltage "Cell  n voltage";
CM_ SG_ 2150633218 Cell_91_Temp "Cell n Temp";
CM_ SG_ 2150633218 Cell_92_Voltage "Cell  n voltage";
CM_ SG_ 2150633218 Cell_92_Temp "Cell n Temp";
CM_ SG_ 2150633218 Cell_93_Voltage "Cell  n voltage";
CM_ SG_ 2150633218 Cell_93_Temp "Cell n Temp";
CM_ SG_ 2150633218 Cell_94_Voltage "Cell  n voltage";
CM_ SG_ 2150633218 Cell_94_Temp "Cell n Temp";
CM_ SG_ 2150633218 Cell_95_Voltage "Cell  n voltage";
CM_ SG_ 2150633218 Cell_95_Temp "Cell n Temp";
CM_ SG_ 2150633474 Cell_96_Voltage "Cell  n voltage";
CM_ SG_ 2150633474 Cell_96_Temp "Cell n Temp";
CM_ SG_ 2150633474 Cell_97_Voltage "Cell  n voltage";
CM_ SG_ 2150633474 Cell_97_Temp "Cell n Temp";
CM_ SG_ 2150633474 Cell_98_Voltage "Cell  n voltage";
CM_ SG_ 2150633474 Cell_98_Temp "Cell n Temp";
CM_ SG_ 2150633474 Cell_99_Voltage "Cell  n voltage";
CM_ SG_ 2150633474 Cell_99_Temp "Cell n Temp";
CM_ SG_ 2150633474 Cell_100_Voltage "Cell  n voltage";
CM_ SG_ 2150633474 Cell_100_Temp "Cell n Temp";
CM_ SG_ 2150633474 Cell_101_Voltage "Cell  n voltage";
CM_ SG_ 2150633474 Cell_101_Temp "Cell n Temp";
CM_ SG_ 2150633474 Cell_102_Voltage "Cell  n voltage";
CM_ SG_ 2150633474 Cell_102_Temp "Cell n Temp";
CM_ SG_ 2150633474 Cell_103_Voltage "Cell  n voltage";
CM_ SG_ 2150633474 Cell_103_Temp "Cell n Temp";
CM_ SG_ 2150633474 Cell_104_Voltage "Cell  n voltage";
CM_ SG_ 2150633474 Cell_104_Temp "Cell n Temp";
CM_ SG_ 2150633474 Cell_105_Voltage "Cell  n voltage";
CM_ SG_ 2150633474 Cell_105_Temp "Cell n Temp";
CM_ SG_ 2150633474 Cell_106_Voltage "Cell  n voltage";
CM_ SG_ 2150633474 Cell_106_Temp "Cell n Temp";
CM_ SG_ 2150633474 Cell_107_Voltage "Cell  n voltage";
CM_ SG_ 2150633474 Cell_107_Temp "Cell n Temp";
CM_ SG_ 2150633474 Cell_108_Voltage "Cell  n voltage";
CM_ SG_ 2150633474 Cell_108_Temp "Cell n Temp";
CM_ SG_ 2150633474 Cell_109_Voltage "Cell  n voltage";
CM_ SG_ 2150633474 Cell_109_Temp "Cell n Temp";
CM_ SG_ 2150633474 Cell_110_Voltage "Cell  n voltage";
CM_ SG_ 2150633474 Cell_110_Temp "Cell n Temp";
CM_ SG_ 2150633474 Cell_111_Voltage "Cell  n voltage";
CM_ SG_ 2150633474 Cell_111_Temp "Cell n Temp";
CM_ SG_ 2150633474 Cell_112_Voltage "Cell  n voltage";
CM_ SG_ 2150633474 Cell_112_Temp "Cell n Temp";
CM_ SG_ 2150633474 Cell_113_Voltage "Cell  n voltage";
CM_ SG_ 2150633474 Cell_113_Temp "Cell n Temp";
CM_ SG_ 2150633474 Cell_114_Voltage "Cell  n voltage";
CM_ SG_ 2150633474 Cell_114_Temp "Cell n Temp";
CM_ SG_ 2150633474 Cell_115_Voltage "Cell  n voltage";
CM_ SG_ 2150633474 Cell_115_Temp "Cell n Temp";
CM_ SG_ 2150633474 Cell_116_Voltage "Cell  n voltage";
CM_ SG_ 2150633474 Cell_116_Temp "Cell n Temp";
CM_ SG_ 2150633474 Cell_117_Voltage "Cell  n voltage";
CM_ SG_ 2150633474 Cell_117_Temp "Cell n Temp";
CM_ SG_ 2150633474 Cell_118_Voltage "Cell  n voltage";
CM_ SG_ 2150633474 Cell_118_Temp "Cell n Temp";
CM_ SG_ 2150633474 Cell_119_Voltage "Cell  n voltage";
CM_ SG_ 2150633474 Cell_119_Temp "Cell n Temp";
CM_ SG_ 2150633474 Cell_120_Voltage "Cell  n voltage";
CM_ SG_ 2150633474 Cell_120_Temp "Cell n Temp";
CM_ SG_ 2150633474 Cell_121_Voltage "Cell  n voltage";
CM_ SG_ 2150633474 Cell_121_Temp "Cell n Temp";
CM_ SG_ 2150633474 Cell_122_Voltage "Cell  n voltage";
CM_ SG_ 2150633474 Cell_122_Temp "Cell n Temp";
CM_ SG_ 2150633474 Cell_123_Voltage "Cell  n voltage";
CM_ SG_ 2150633474 Cell_123_Temp "Cell n Temp";
CM_ SG_ 2150633474 Cell_124_Voltage "Cell  n voltage";
CM_ SG_ 2150633474 Cell_124_Temp "Cell n Temp";
CM_ SG_ 2150633474 Cell_125_Voltage "Cell  n voltage";
CM_ SG_ 2150633474 Cell_125_Temp "Cell n Temp";
CM_ SG_ 2150633474 Cell_126_Voltage "Cell  n voltage";
CM_ SG_ 2150633474 Cell_126_Temp "Cell n Temp";
CM_ SG_ 2150633474 Cell_127_Voltage "Cell  n voltage";
CM_ SG_ 2150633474 Cell_127_Temp "Cell n Temp";
CM_ SG_ 2150633730 Cell_128_Voltage "Cell  n voltage";
CM_ SG_ 2150633730 Cell_128_Temp "Cell n Temp";
CM_ SG_ 2150633730 Cell_129_Voltage "Cell  n voltage";
CM_ SG_ 2150633730 Cell_129_Temp "Cell n Temp";
CM_ SG_ 2150633730 Cell_130_Voltage "Cell  n voltage";
CM_ SG_ 2150633730 Cell_130_Temp "Cell n Temp";
CM_ SG_ 2150633730 Cell_131_Voltage "Cell  n voltage";
CM_ SG_ 2150633730 Cell_131_Temp "Cell n Temp";
CM_ SG_ 2150633730 Cell_132_Voltage "Cell  n voltage";
CM_ SG_ 2150633730 Cell_132_Temp "Cell n Temp";
CM_ SG_ 2150633730 Cell_133_Voltage "Cell  n voltage";
CM_ SG_ 2150633730 Cell_133_Temp "Cell n Temp";
CM_ SG_ 2150633730 Cell_134_Voltage "Cell  n voltage";
CM_ SG_ 2150633730 Cell_134_Temp "Cell n Temp";
CM_ SG_ 2150633730 Cell_135_Voltage "Cell  n voltage";
CM_ SG_ 2150633730 Cell_135_Temp "Cell n Temp";
CM_ SG_ 2150633730 Cell_136_Voltage "Cell  n voltage";
CM_ SG_ 2150633730 Cell_136_Temp "Cell n Temp";
CM_ SG_ 2150633730 Cell_137_Voltage "Cell  n voltage";
CM_ SG_ 2150633730 Cell_137_Temp "Cell n Temp";
CM_ SG_ 2150633730 Cell_138_Voltage "Cell  n voltage";
CM_ SG_ 2150633730 Cell_138_Temp "Cell n Temp";
CM_ SG_ 2150633730 Cell_139_Voltage "Cell  n voltage";
CM_ SG_ 2150633730 Cell_139_Temp "Cell n Temp";
CM_ SG_ 2150633730 Cell_140_Voltage "Cell  n voltage";
CM_ SG_ 2150633730 Cell_140_Temp "Cell n Temp";
CM_ SG_ 2150633730 Cell_141_Voltage "Cell  n voltage";
CM_ SG_ 2150633730 Cell_141_Temp "Cell n Temp";
CM_ SG_ 2150633730 Cell_142_Voltage "Cell  n voltage";
CM_ SG_ 2150633730 Cell_142_Temp "Cell n Temp";
CM_ SG_ 2150633730 Cell_143_Voltage "Cell  n voltage";
CM_ SG_ 2150633730 Cell_143_Temp "Cell n Temp";
CM_ SG_ 2150633730 Cell_144_Voltage "Cell  n voltage";
CM_ SG_ 2150633730 Cell_144_Temp "Cell n Temp";
CM_ SG_ 2150633730 Cell_145_Voltage "Cell  n voltage";
CM_ SG_ 2150633730 Cell_145_Temp "Cell n Temp";
CM_ SG_ 2150633730 Cell_146_Voltage "Cell  n voltage";
CM_ SG_ 2150633730 Cell_146_Temp "Cell n Temp";
CM_ SG_ 2150633730 Cell_147_Voltage "Cell  n voltage";
CM_ SG_ 2150633730 Cell_147_Temp "Cell n Temp";
CM_ SG_ 2150633730 Cell_148_Voltage "Cell  n voltage";
CM_ SG_ 2150633730 Cell_148_Temp "Cell n Temp";
CM_ SG_ 2150633730 Cell_149_Voltage "Cell  n voltage";
CM_ SG_ 2150633730 Cell_149_Temp "Cell n Temp";
CM_ SG_ 2150633730 Cell_150_Voltage "Cell  n voltage";
CM_ SG_ 2150633730 Cell_150_Temp "Cell n Temp";
CM_ SG_ 2150633730 Cell_151_Voltage "Cell  n voltage";
CM_ SG_ 2150633730 Cell_151_Temp "Cell n Temp";
CM_ SG_ 2150633730 Cell_152_Voltage "Cell  n voltage";
CM_ SG_ 2150633730 Cell_152_Temp "Cell n Temp";
CM_ SG_ 2150633730 Cell_153_Voltage "Cell  n voltage";
CM_ SG_ 2150633730 Cell_153_Temp "Cell n Temp";
CM_ SG_ 2150633730 Cell_154_Voltage "Cell  n voltage";
CM_ SG_ 2150633730 Cell_154_Temp "Cell n Temp";
CM_ SG_ 2150633730 Cell_155_Voltage "Cell  n voltage";
CM_ SG_ 2150633730 Cell_155_Temp "Cell n Temp";
CM_ SG_ 2150633730 Cell_156_Voltage "Cell  n voltage";
CM_ SG_ 2150633730 Cell_156_Temp "Cell n Temp";
CM_ SG_ 2150633730 Cell_157_Voltage "Cell  n voltage";
CM_ SG_ 2150633730 Cell_157_Temp "Cell n Temp";
CM_ SG_ 2150633730 Cell_158_Voltage "Cell  n voltage";
CM_ SG_ 2150633730 Cell_158_Temp "Cell n Temp";
CM_ SG_ 2150633730 Cell_159_Voltage "Cell  n voltage";
CM_ SG_ 2150633730 Cell_159_Temp "Cell n Temp";
CM_ SG_ 2148532738 Timestamp "Time in millis";
CM_ SG_ 2148532739 Timestamp "Time in millis";
CM_ SG_ 2148532740 Timestamp "Time in millis";
CM_ SG_ 2149581313 Timestamp "Time in millis";
CM_ SG_ 2149592580 BSPD_Signal "4-20 mA signal";
CM_ SG_ 2149592580 BSE_Signal "4-20 mA signal";
CM_ SG_ 2149592580 APPS_1_Signal "4-20 mA signal";
CM_ SG_ 2149592580 APPS_2_Signal "4-20 mA signal";
CM_ SG_ 2149592580 Brakeline_F_Signal "4-20 mA signal";
CM_ SG_ 2149592580 Brakeline_R_Signal "4-20 mA signal";
CM_ SG_ 2149592580 Steering_Angle_Signal "4-20 mA signal";
CM_ SG_ 2149592580 AUX_Signal "4-20 mA signal";
CM_ SG_ 2149592580 Acc_Pedal_Travel "0-100% percentage";
CM_ SG_ 2149592580 Brake_Pedal_Pressure "Pressure";
CM_ SG_ 2149592324 ACU_RTT "Round trip time";
CM_ SG_ 2149592324 GR_Inv_RTT "Round trip time";
CM_ SG_ 2149592324 Fan_Ctrl_1_RTT "Round trip time";
CM_ SG_ 2149592324 Fan_Ctrl_2_RTT "Round trip time";
CM_ SG_ 2149592324 Fan_Ctrl_3_RTT "Round trip time";
CM_ SG_ 2149592324 Dash_Panel_RTT "Round trip time";
CM_ SG_ 2149592324 TCM_RTT "Round trip time";
CM_ SG_ 2149592324 Tire_Temp_FL_RTT "Round trip time";
CM_ SG_ 2149592324 Tire_Temp_FR_RTT "Round trip time";
CM_ SG_ 2149592324 Tire_Temp_RL_RTT "Round trip time";
CM_ SG_ 2149592324 Tire_Temp_RR_RTT "Round trip time";
CM_ SG_ 2149592324 Suspension_Node_FL_RTT "Round trip time";
CM_ SG_ 2149592324 Suspension_Node_FR_RTT "Round trip time";
CM_ SG_ 2149592324 Suspension_Node_RL_RTT "Round trip time";
CM_ SG_ 2149592324 Suspension_Node_RR_RTT "Round trip time";
CM_ SG_ 2149592324 Inboard_Floor_FL_RTT "Round trip time";
CM_ SG_ 2149592324 Inboard_Floor_FR_RTT "Round trip time";
CM_ SG_ 2149592324 Inboard_Floor_RL_RTT "Round trip time";
CM_ SG_ 2149592324 Inboard_Floor_RR_RTT "Round trip time";
CM_ SG_ 2149592324 Brake_Temp_FL_RTT "Round trip time";
CM_ SG_ 2149592324 Brake_Temp_FR_RTT "Round trip time";
CM_ SG_ 2149592324 Brake_Temp_RL_RTT "Round trip time";
CM_ SG_ 2149592324 Brake_Temp_RR_RTT "Round trip time";
CM_ SG_ 2149592324 DGPS_RTT "Round trip time";
CM_ SG_ 2149592836 Ping_Timeout_Delay "Delay for which to consider pings timed out";
CM_ SG_ 2149592836 Brake_F_Min "Minimum brake f psi for which to consider the brakes pressed";
CM_ SG_ 2149592836 Brake_R_Min "Minimum brake r psi for which to consider the brakes pressed";
CM_ SG_ 2149592836 Brake_BSE_Min "Minimum brake bse psi for which to consider the brakes pressed";
CM_ SG_ 2149592836 APPS_1_Min "Minimum value that the APPS 1 sensor is expected to read";
CM_ SG_ 2149592836 APPS_2_Min "Minimum value that the APPS 2 sensor is expected to read";
CM_ SG_ 2149592836 APPS_1_Max "Maximum value that the APPS 1 sensor is expected to read";
CM_ SG_ 2149592836 APPS_2_Max "Maximum value that the APPS 2 sensor is expected to read";
CM_ SG_ 2149592836 APPS_Deadzone "Percentage deadzone of the APPS for which to not consider the pedals to have traveled";
CM_ SG_ 2149592836 BMS_Min_Threshold "Minimum acceptable BMS sense value such that the BMS is not considered in failure";
CM_ SG_ 2149592836 BMS_Max_Threshold "Maximum acceptable BMS sense value such that the BMS is not considered in failure";
CM_ SG_ 2149592836 IMD_Min_Threshold "Minimum acceptable IMD sense value such that the BMS is not considered in failure";
CM_ SG_ 2149592836 IMD_Max_Threshold "Maximum acceptable IMD sense value such that the BMS is not considered in failure";
CM_ SG_ 2149592836 BSPD_Min_Threshold "Minimum acceptable BSPD sense value such that the BMS is not considered in failure";
CM_ SG_ 2149592836 BSPD_Max_Threshold "Maximum acceptable BSPD sense value such that the BMS is not considered in failure";
CM_ SG_ 2149592836 Max_Precharge_Time "Maximum acceptable time to remain precharging before discharging";
CM_ SG_ 2149592836 Regen_Strength "TBD";
CM_ SG_ 2149592836 Enable_Regen "Enable or disable regenerative braking";
CM_ SG_ 2149581312 Timestamp "Time in millis";
CM_ SG_ 2151689986 Ping_Timeout_Delay "Delay for which to consider pings timed out";
CM_ SG_ 2151689986 Brake_F_Min "Minimum brake f psi for which to consider the brakes pressed";
CM_ SG_ 2151689986 Brake_R_Min "Minimum brake r psi for which to consider the brakes pressed";
CM_ SG_ 2151689986 Brake_BSE_Min "Minimum brake bse psi for which to consider the brakes pressed";
CM_ SG_ 2151689986 APPS_1_Min "Minimum value that the APPS 1 sensor is expected to read";
CM_ SG_ 2151689986 APPS_2_Min "Minimum value that the APPS 2 sensor is expected to read";
CM_ SG_ 2151689986 APPS_1_Max "Maximum value that the APPS 1 sensor is expected to read";
CM_ SG_ 2151689986 APPS_2_Max "Maximum value that the APPS 2 sensor is expected to read";
CM_ SG_ 2151689986 APPS_Deadzone "Percentage deadzone of the APPS for which to not consider the pedals to have traveled";
CM_ SG_ 2151689986 BMS_Min_Threshold "Minimum acceptable BMS sense value such that the BMS is not considered in failure";
CM_ SG_ 2151689986 BMS_Max_Threshold "Maximum acceptable BMS sense value such that the BMS is not considered in failure";
CM_ SG_ 2151689986 IMD_Min_Threshold "Minimum acceptable IMD sense value such that the BMS is not considered in failure";
CM_ SG_ 2151689986 IMD_Max_Threshold "Maximum acceptable IMD sense value such that the BMS is not considered in failure";
CM_ SG_ 2151689986 BSPD_Min_Threshold "Minimum acceptable BSPD sense value such that the BMS is not considered in failure";
CM_ SG_ 2151689986 BSPD_Max_Threshold "Maximum acceptable BSPD sense value such that the BMS is not considered in failure";
CM_ SG_ 2151689986 Max_Precharge_Time "Maximum acceptable time to remain precharging before discharging";
CM_ SG_ 2151689986 Regen_Strength "TBD";
CM_ SG_ 2151689986 Enable_Regen "Enable or disable regenerative braking";
CM_ SG_ 2151678465 Timestamp "Time in millis";
CM_ SG_ 2181038594 Timestamp "Time in millis";
CM_ SG_ 2181051140 ALT "altitude";
CM_ SG_ 2181050628 LAT "lattitude";
CM_ SG_ 2181050884 LON "longitude";
CM_ SG_ 2181050372 DGPS_U "U";
CM_ SG_ 2181050372 DGPS_V "V";
CM_ SG_ 2181050372 DGPS_W "W";
CM_ SG_ 2168455682 Timestamp "Time in millis";
CM_ SG_ 2168475908 bmi323_acc_x "BMI323 accelerometer X";
CM_ SG_ 2168475908 bmi323_acc_y "BMI323 accelerometer Y";
CM_ SG_ 2168475908 bmi323_acc_z "BMI323 accelerometer Z";
CM_ SG_ 2168475908 bmi323_gyro_x "BMI323 gyroscope X";
CM_ SG_ 2168475908 bmi323_gyro_y "BMI323 gyroscope Y";
CM_ SG_ 2168475908 bmi323_gyro_z "BMI323 gyroscope Z";
CM_ SG_ 2168475908 bmi323_temp "BMI323 temperature";
CM_ SG_ 2168475908 bmi323_status "BMI323 status";
CM_ SG_ 2168475908 mag_temp "Magnetic encoder temperature";
CM_ SG_ 2168475908 mag_hysteresis "The lineation of groupings for hysteresis";
CM_ SG_ 2168475908 mag_angle "Magnetic encoder angle";
CM_ SG_ 2168475908 mag_turns "Magnetic encoder turns";
CM_ SG_ 2169504258 Timestamp "Time in millis";
CM_ SG_ 2169524484 bmi323_acc_x "BMI323 accelerometer X";
CM_ SG_ 2169524484 bmi323_acc_y "BMI323 accelerometer Y";
CM_ SG_ 2169524484 bmi323_acc_z "BMI323 accelerometer Z";
CM_ SG_ 2169524484 bmi323_gyro_x "BMI323 gyroscope X";
CM_ SG_ 2169524484 bmi323_gyro_y "BMI323 gyroscope Y";
CM_ SG_ 2169524484 bmi323_gyro_z "BMI323 gyroscope Z";
CM_ SG_ 2169524484 bmi323_temp "BMI323 temperature";
CM_ SG_ 2169524484 bmi323_status "BMI323 status";
CM_ SG_ 2169524484 mag_temp "Magnetic encoder temperature";
CM_ SG_ 2169524484 mag_hysteresis "The lineation of groupings for hysteresis";
CM_ SG_ 2169524484 mag_angle "Magnetic encoder angle";
CM_ SG_ 2169524484 mag_turns "Magnetic encoder turns";
CM_ SG_ 2170552834 Timestamp "Time in millis";
CM_ SG_ 2170573060 bmi323_acc_x "BMI323 accelerometer X";
CM_ SG_ 2170573060 bmi323_acc_y "BMI323 accelerometer Y";
CM_ SG_ 2170573060 bmi323_acc_z "BMI323 accelerometer Z";
CM_ SG_ 2170573060 bmi323_gyro_x "BMI323 gyroscope X";
CM_ SG_ 2170573060 bmi323_gyro_y "BMI323 gyroscope Y";
CM_ SG_ 2170573060 bmi323_gyro_z "BMI323 gyroscope Z";
CM_ SG_ 2170573060 bmi323_temp "BMI323 temperature";
CM_ SG_ 2170573060 bmi323_status "BMI323 status";
CM_ SG_ 2170573060 mag_temp "Magnetic encoder temperature";
CM_ SG_ 2170573060 mag_hysteresis "The lineation of groupings for hysteresis";
CM_ SG_ 2170573060 mag_angle "Magnetic encoder angle";
CM_ SG_ 2170573060 mag_turns "Magnetic encoder turns";
CM_ SG_ 2171601410 Timestamp "Time in millis";
CM_ SG_ 2171621636 bmi323_acc_x "BMI323 accelerometer X";
CM_ SG_ 2171621636 bmi323_acc_y "BMI323 accelerometer Y";
CM_ SG_ 2171621636 bmi323_acc_z "BMI323 accelerometer Z";
CM_ SG_ 2171621636 bmi323_gyro_x "BMI323 gyroscope X";
CM_ SG_ 2171621636 bmi323_gyro_y "BMI323 gyroscope Y";
CM_ SG_ 2171621636 bmi323_gyro_z "BMI323 gyroscope Z";
CM_ SG_ 2171621636 bmi323_temp "BMI323 temperature";
CM_ SG_ 2171621636 bmi323_status "BMI323 status";
CM_ SG_ 2171621636 mag_temp "Magnetic encoder temperature";
CM_ SG_ 2171621636 mag_hysteresis "The lineation of groupings for hysteresis";
CM_ SG_ 2171621636 mag_angle "Magnetic encoder angle";
CM_ SG_ 2171621636 mag_turns "Magnetic encoder turns";
CM_ SG_ 2172649986 Timestamp "Time in millis";
CM_ SG_ 2172670468 bmi323_acc_x "BMI323 accelerometer X";
CM_ SG_ 2172670468 bmi323_acc_y "BMI323 accelerometer Y";
CM_ SG_ 2172670468 bmi323_acc_z "BMI323 accelerometer Z";
CM_ SG_ 2172670468 bmi323_gyro_x "BMI323 gyroscope X";
CM_ SG_ 2172670468 bmi323_gyro_y "BMI323 gyroscope Y";
CM_ SG_ 2172670468 bmi323_gyro_z "BMI323 gyroscope Z";
CM_ SG_ 2172670468 bmi323_temp "BMI323 temperature";
CM_ SG_ 2172670468 bmi323_status "BMI323 status";
CM_ SG_ 2172670468 range_status "Time-of-flight range status";
CM_ SG_ 2172670468 distance_mm "Time-of-flight distance";
CM_ SG_ 2172670468 ambient_rate_kcps "Time-of-flight ambient rate";
CM_ SG_ 2172670468 ambient_per_spad_kcps "Time-of-flight ambient rate per SPAD";
CM_ SG_ 2172670468 signal_rate_kcps "Time-of-flight signal rate";
CM_ SG_ 2172670468 signal_per_spad_kcps "Time-of-flight signal rate per SPAD";
CM_ SG_ 2172670468 number_of_spad "Time-of-flight SPAD count";
CM_ SG_ 2172670468 sigma_mm "Time-of-flight sigma";
CM_ SG_ 2173698562 Timestamp "Time in millis";
CM_ SG_ 2173719044 bmi323_acc_x "BMI323 accelerometer X";
CM_ SG_ 2173719044 bmi323_acc_y "BMI323 accelerometer Y";
CM_ SG_ 2173719044 bmi323_acc_z "BMI323 accelerometer Z";
CM_ SG_ 2173719044 bmi323_gyro_x "BMI323 gyroscope X";
CM_ SG_ 2173719044 bmi323_gyro_y "BMI323 gyroscope Y";
CM_ SG_ 2173719044 bmi323_gyro_z "BMI323 gyroscope Z";
CM_ SG_ 2173719044 bmi323_temp "BMI323 temperature";
CM_ SG_ 2173719044 bmi323_status "BMI323 status";
CM_ SG_ 2173719044 range_status "Time-of-flight range status";
CM_ SG_ 2173719044 distance_mm "Time-of-flight distance";
CM_ SG_ 2173719044 ambient_rate_kcps "Time-of-flight ambient rate";
CM_ SG_ 2173719044 ambient_per_spad_kcps "Time-of-flight ambient rate per SPAD";
CM_ SG_ 2173719044 signal_rate_kcps "Time-of-flight signal rate";
CM_ SG_ 2173719044 signal_per_spad_kcps "Time-of-flight signal rate per SPAD";
CM_ SG_ 2173719044 number_of_spad "Time-of-flight SPAD count";
CM_ SG_ 2173719044 sigma_mm "Time-of-flight sigma";
CM_ SG_ 2174747138 Timestamp "Time in millis";
CM_ SG_ 2174767620 bmi323_acc_x "BMI323 accelerometer X";
CM_ SG_ 2174767620 bmi323_acc_y "BMI323 accelerometer Y";
CM_ SG_ 2174767620 bmi323_acc_z "BMI323 accelerometer Z";
CM_ SG_ 2174767620 bmi323_gyro_x "BMI323 gyroscope X";
CM_ SG_ 2174767620 bmi323_gyro_y "BMI323 gyroscope Y";
CM_ SG_ 2174767620 bmi323_gyro_z "BMI323 gyroscope Z";
CM_ SG_ 2174767620 bmi323_temp "BMI323 temperature";
CM_ SG_ 2174767620 bmi323_status "BMI323 status";
CM_ SG_ 2174767620 range_status "Time-of-flight range status";
CM_ SG_ 2174767620 distance_mm "Time-of-flight distance";
CM_ SG_ 2174767620 ambient_rate_kcps "Time-of-flight ambient rate";
CM_ SG_ 2174767620 ambient_per_spad_kcps "Time-of-flight ambient rate per SPAD";
CM_ SG_ 2174767620 signal_rate_kcps "Time-of-flight signal rate";
CM_ SG_ 2174767620 signal_per_spad_kcps "Time-of-flight signal rate per SPAD";
CM_ SG_ 2174767620 number_of_spad "Time-of-flight SPAD count";
CM_ SG_ 2174767620 sigma_mm "Time-of-flight sigma";
CM_ SG_ 2175795714 Timestamp "Time in millis";
CM_ SG_ 2175816196 bmi323_acc_x "BMI323 accelerometer X";
CM_ SG_ 2175816196 bmi323_acc_y "BMI323 accelerometer Y";
CM_ SG_ 2175816196 bmi323_acc_z "BMI323 accelerometer Z";
CM_ SG_ 2175816196 bmi323_gyro_x "BMI323 gyroscope X";
CM_ SG_ 2175816196 bmi323_gyro_y "BMI323 gyroscope Y";
CM_ SG_ 2175816196 bmi323_gyro_z "BMI323 gyroscope Z";
CM_ SG_ 2175816196 bmi323_temp "BMI323 temperature";
CM_ SG_ 2175816196 bmi323_status "BMI323 status";
CM_ SG_ 2175816196 range_status "Time-of-flight range status";
CM_ SG_ 2175816196 distance_mm "Time-of-flight distance";
CM_ SG_ 2175816196 ambient_rate_kcps "Time-of-flight ambient rate";
CM_ SG_ 2175816196 ambient_per_spad_kcps "Time-of-flight ambient rate per SPAD";
CM_ SG_ 2175816196 signal_rate_kcps "Time-of-flight signal rate";
CM_ SG_ 2175816196 signal_per_spad_kcps "Time-of-flight signal rate per SPAD";
CM_ SG_ 2175816196 number_of_spad "Time-of-flight SPAD count";
CM_ SG_ 2175816196 sigma_mm "Time-of-flight sigma";
CM_ SG_ 2164261378 Timestamp "Time in millis";
CM_ SG_ 2164274948 pixel0 "Tire Temp frame 0 pixel 0";
CM_ SG_ 2164274948 pixel1 "Tire Temp frame 0 pixel 1";
CM_ SG_ 2164274948 pixel2 "Tire Temp frame 0 pixel 2";
CM_ SG_ 2164274948 pixel3 "Tire Temp frame 0 pixel 3";
CM_ SG_ 2164274948 pixel4 "Tire Temp frame 0 pixel 4";
CM_ SG_ 2164274948 pixel5 "Tire Temp frame 0 pixel 5";
CM_ SG_ 2164274948 pixel6 "Tire Temp frame 0 pixel 6";
CM_ SG_ 2164274948 pixel7 "Tire Temp frame 0 pixel 7";
CM_ SG_ 2164274948 pixel8 "Tire Temp frame 0 pixel 8";
CM_ SG_ 2164274948 pixel9 "Tire Temp frame 0 pixel 9";
CM_ SG_ 2164274948 pixel10 "Tire Temp frame 0 pixel 10";
CM_ SG_ 2164274948 pixel11 "Tire Temp frame 0 pixel 11";
CM_ SG_ 2164274948 pixel12 "Tire Temp frame 0 pixel 12";
CM_ SG_ 2164274948 pixel13 "Tire Temp frame 0 pixel 13";
CM_ SG_ 2164274948 pixel14 "Tire Temp frame 0 pixel 14";
CM_ SG_ 2164274948 pixel15 "Tire Temp frame 0 pixel 15";
CM_ SG_ 2164274948 pixel16 "Tire Temp frame 0 pixel 16";
CM_ SG_ 2164274948 pixel17 "Tire Temp frame 0 pixel 17";
CM_ SG_ 2164274948 pixel18 "Tire Temp frame 0 pixel 18";
CM_ SG_ 2164274948 pixel19 "Tire Temp frame 0 pixel 19";
CM_ SG_ 2164274948 pixel20 "Tire Temp frame 0 pixel 20";
CM_ SG_ 2164274948 pixel21 "Tire Temp frame 0 pixel 21";
CM_ SG_ 2164274948 pixel22 "Tire Temp frame 0 pixel 22";
CM_ SG_ 2164274948 pixel23 "Tire Temp frame 0 pixel 23";
CM_ SG_ 2164274948 pixel24 "Tire Temp frame 0 pixel 24";
CM_ SG_ 2164274948 pixel25 "Tire Temp frame 0 pixel 25";
CM_ SG_ 2164274948 pixel26 "Tire Temp frame 0 pixel 26";
CM_ SG_ 2164274948 pixel27 "Tire Temp frame 0 pixel 27";
CM_ SG_ 2164274948 pixel28 "Tire Temp frame 0 pixel 28";
CM_ SG_ 2164274948 pixel29 "Tire Temp frame 0 pixel 29";
CM_ SG_ 2164274948 pixel30 "Tire Temp frame 0 pixel 30";
CM_ SG_ 2164274948 pixel31 "Tire Temp frame 0 pixel 31";
CM_ SG_ 2164275204 pixel0 "Tire Temp frame 1 pixel 0";
CM_ SG_ 2164275204 pixel1 "Tire Temp frame 1 pixel 1";
CM_ SG_ 2164275204 pixel2 "Tire Temp frame 1 pixel 2";
CM_ SG_ 2164275204 pixel3 "Tire Temp frame 1 pixel 3";
CM_ SG_ 2164275204 pixel4 "Tire Temp frame 1 pixel 4";
CM_ SG_ 2164275204 pixel5 "Tire Temp frame 1 pixel 5";
CM_ SG_ 2164275204 pixel6 "Tire Temp frame 1 pixel 6";
CM_ SG_ 2164275204 pixel7 "Tire Temp frame 1 pixel 7";
CM_ SG_ 2164275204 pixel8 "Tire Temp frame 1 pixel 8";
CM_ SG_ 2164275204 pixel9 "Tire Temp frame 1 pixel 9";
CM_ SG_ 2164275204 pixel10 "Tire Temp frame 1 pixel 10";
CM_ SG_ 2164275204 pixel11 "Tire Temp frame 1 pixel 11";
CM_ SG_ 2164275204 pixel12 "Tire Temp frame 1 pixel 12";
CM_ SG_ 2164275204 pixel13 "Tire Temp frame 1 pixel 13";
CM_ SG_ 2164275204 pixel14 "Tire Temp frame 1 pixel 14";
CM_ SG_ 2164275204 pixel15 "Tire Temp frame 1 pixel 15";
CM_ SG_ 2164275204 pixel16 "Tire Temp frame 1 pixel 16";
CM_ SG_ 2164275204 pixel17 "Tire Temp frame 1 pixel 17";
CM_ SG_ 2164275204 pixel18 "Tire Temp frame 1 pixel 18";
CM_ SG_ 2164275204 pixel19 "Tire Temp frame 1 pixel 19";
CM_ SG_ 2164275204 pixel20 "Tire Temp frame 1 pixel 20";
CM_ SG_ 2164275204 pixel21 "Tire Temp frame 1 pixel 21";
CM_ SG_ 2164275204 pixel22 "Tire Temp frame 1 pixel 22";
CM_ SG_ 2164275204 pixel23 "Tire Temp frame 1 pixel 23";
CM_ SG_ 2164275204 pixel24 "Tire Temp frame 1 pixel 24";
CM_ SG_ 2164275204 pixel25 "Tire Temp frame 1 pixel 25";
CM_ SG_ 2164275204 pixel26 "Tire Temp frame 1 pixel 26";
CM_ SG_ 2164275204 pixel27 "Tire Temp frame 1 pixel 27";
CM_ SG_ 2164275204 pixel28 "Tire Temp frame 1 pixel 28";
CM_ SG_ 2164275204 pixel29 "Tire Temp frame 1 pixel 29";
CM_ SG_ 2164275204 pixel30 "Tire Temp frame 1 pixel 30";
CM_ SG_ 2164275204 pixel31 "Tire Temp frame 1 pixel 31";
CM_ SG_ 2164275460 pixel0 "Tire Temp frame 2 pixel 0";
CM_ SG_ 2164275460 pixel1 "Tire Temp frame 2 pixel 1";
CM_ SG_ 2164275460 pixel2 "Tire Temp frame 2 pixel 2";
CM_ SG_ 2164275460 pixel3 "Tire Temp frame 2 pixel 3";
CM_ SG_ 2164275460 pixel4 "Tire Temp frame 2 pixel 4";
CM_ SG_ 2164275460 pixel5 "Tire Temp frame 2 pixel 5";
CM_ SG_ 2164275460 pixel6 "Tire Temp frame 2 pixel 6";
CM_ SG_ 2164275460 pixel7 "Tire Temp frame 2 pixel 7";
CM_ SG_ 2164275460 pixel8 "Tire Temp frame 2 pixel 8";
CM_ SG_ 2164275460 pixel9 "Tire Temp frame 2 pixel 9";
CM_ SG_ 2164275460 pixel10 "Tire Temp frame 2 pixel 10";
CM_ SG_ 2164275460 pixel11 "Tire Temp frame 2 pixel 11";
CM_ SG_ 2164275460 pixel12 "Tire Temp frame 2 pixel 12";
CM_ SG_ 2164275460 pixel13 "Tire Temp frame 2 pixel 13";
CM_ SG_ 2164275460 pixel14 "Tire Temp frame 2 pixel 14";
CM_ SG_ 2164275460 pixel15 "Tire Temp frame 2 pixel 15";
CM_ SG_ 2164275460 pixel16 "Tire Temp frame 2 pixel 16";
CM_ SG_ 2164275460 pixel17 "Tire Temp frame 2 pixel 17";
CM_ SG_ 2164275460 pixel18 "Tire Temp frame 2 pixel 18";
CM_ SG_ 2164275460 pixel19 "Tire Temp frame 2 pixel 19";
CM_ SG_ 2164275460 pixel20 "Tire Temp frame 2 pixel 20";
CM_ SG_ 2164275460 pixel21 "Tire Temp frame 2 pixel 21";
CM_ SG_ 2164275460 pixel22 "Tire Temp frame 2 pixel 22";
CM_ SG_ 2164275460 pixel23 "Tire Temp frame 2 pixel 23";
CM_ SG_ 2164275460 pixel24 "Tire Temp frame 2 pixel 24";
CM_ SG_ 2164275460 pixel25 "Tire Temp frame 2 pixel 25";
CM_ SG_ 2164275460 pixel26 "Tire Temp frame 2 pixel 26";
CM_ SG_ 2164275460 pixel27 "Tire Temp frame 2 pixel 27";
CM_ SG_ 2164275460 pixel28 "Tire Temp frame 2 pixel 28";
CM_ SG_ 2164275460 pixel29 "Tire Temp frame 2 pixel 29";
CM_ SG_ 2164275460 pixel30 "Tire Temp frame 2 pixel 30";
CM_ SG_ 2164275460 pixel31 "Tire Temp frame 2 pixel 31";
CM_ SG_ 2164275716 pixel0 "Tire Temp frame 3 pixel 0";
CM_ SG_ 2164275716 pixel1 "Tire Temp frame 3 pixel 1";
CM_ SG_ 2164275716 pixel2 "Tire Temp frame 3 pixel 2";
CM_ SG_ 2164275716 pixel3 "Tire Temp frame 3 pixel 3";
CM_ SG_ 2164275716 pixel4 "Tire Temp frame 3 pixel 4";
CM_ SG_ 2164275716 pixel5 "Tire Temp frame 3 pixel 5";
CM_ SG_ 2164275716 pixel6 "Tire Temp frame 3 pixel 6";
CM_ SG_ 2164275716 pixel7 "Tire Temp frame 3 pixel 7";
CM_ SG_ 2164275716 pixel8 "Tire Temp frame 3 pixel 8";
CM_ SG_ 2164275716 pixel9 "Tire Temp frame 3 pixel 9";
CM_ SG_ 2164275716 pixel10 "Tire Temp frame 3 pixel 10";
CM_ SG_ 2164275716 pixel11 "Tire Temp frame 3 pixel 11";
CM_ SG_ 2164275716 pixel12 "Tire Temp frame 3 pixel 12";
CM_ SG_ 2164275716 pixel13 "Tire Temp frame 3 pixel 13";
CM_ SG_ 2164275716 pixel14 "Tire Temp frame 3 pixel 14";
CM_ SG_ 2164275716 pixel15 "Tire Temp frame 3 pixel 15";
CM_ SG_ 2164275716 pixel16 "Tire Temp frame 3 pixel 16";
CM_ SG_ 2164275716 pixel17 "Tire Temp frame 3 pixel 17";
CM_ SG_ 2164275716 pixel18 "Tire Temp frame 3 pixel 18";
CM_ SG_ 2164275716 pixel19 "Tire Temp frame 3 pixel 19";
CM_ SG_ 2164275716 pixel20 "Tire Temp frame 3 pixel 20";
CM_ SG_ 2164275716 pixel21 "Tire Temp frame 3 pixel 21";
CM_ SG_ 2164275716 pixel22 "Tire Temp frame 3 pixel 22";
CM_ SG_ 2164275716 pixel23 "Tire Temp frame 3 pixel 23";
CM_ SG_ 2164275716 pixel24 "Tire Temp frame 3 pixel 24";
CM_ SG_ 2164275716 pixel25 "Tire Temp frame 3 pixel 25";
CM_ SG_ 2164275716 pixel26 "Tire Temp frame 3 pixel 26";
CM_ SG_ 2164275716 pixel27 "Tire Temp frame 3 pixel 27";
CM_ SG_ 2164275716 pixel28 "Tire Temp frame 3 pixel 28";
CM_ SG_ 2164275716 pixel29 "Tire Temp frame 3 pixel 29";
CM_ SG_ 2164275716 pixel30 "Tire Temp frame 3 pixel 30";
CM_ SG_ 2164275716 pixel31 "Tire Temp frame 3 pixel 31";
CM_ SG_ 2164275972 pixel0 "Tire Temp frame 4 pixel 0";
CM_ SG_ 2164275972 pixel1 "Tire Temp frame 4 pixel 1";
CM_ SG_ 2164275972 pixel2 "Tire Temp frame 4 pixel 2";
CM_ SG_ 2164275972 pixel3 "Tire Temp frame 4 pixel 3";
CM_ SG_ 2164275972 pixel4 "Tire Temp frame 4 pixel 4";
CM_ SG_ 2164275972 pixel5 "Tire Temp frame 4 pixel 5";
CM_ SG_ 2164275972 pixel6 "Tire Temp frame 4 pixel 6";
CM_ SG_ 2164275972 pixel7 "Tire Temp frame 4 pixel 7";
CM_ SG_ 2164275972 pixel8 "Tire Temp frame 4 pixel 8";
CM_ SG_ 2164275972 pixel9 "Tire Temp frame 4 pixel 9";
CM_ SG_ 2164275972 pixel10 "Tire Temp frame 4 pixel 10";
CM_ SG_ 2164275972 pixel11 "Tire Temp frame 4 pixel 11";
CM_ SG_ 2164275972 pixel12 "Tire Temp frame 4 pixel 12";
CM_ SG_ 2164275972 pixel13 "Tire Temp frame 4 pixel 13";
CM_ SG_ 2164275972 pixel14 "Tire Temp frame 4 pixel 14";
CM_ SG_ 2164275972 pixel15 "Tire Temp frame 4 pixel 15";
CM_ SG_ 2164275972 pixel16 "Tire Temp frame 4 pixel 16";
CM_ SG_ 2164275972 pixel17 "Tire Temp frame 4 pixel 17";
CM_ SG_ 2164275972 pixel18 "Tire Temp frame 4 pixel 18";
CM_ SG_ 2164275972 pixel19 "Tire Temp frame 4 pixel 19";
CM_ SG_ 2164275972 pixel20 "Tire Temp frame 4 pixel 20";
CM_ SG_ 2164275972 pixel21 "Tire Temp frame 4 pixel 21";
CM_ SG_ 2164275972 pixel22 "Tire Temp frame 4 pixel 22";
CM_ SG_ 2164275972 pixel23 "Tire Temp frame 4 pixel 23";
CM_ SG_ 2164275972 pixel24 "Tire Temp frame 4 pixel 24";
CM_ SG_ 2164275972 pixel25 "Tire Temp frame 4 pixel 25";
CM_ SG_ 2164275972 pixel26 "Tire Temp frame 4 pixel 26";
CM_ SG_ 2164275972 pixel27 "Tire Temp frame 4 pixel 27";
CM_ SG_ 2164275972 pixel28 "Tire Temp frame 4 pixel 28";
CM_ SG_ 2164275972 pixel29 "Tire Temp frame 4 pixel 29";
CM_ SG_ 2164275972 pixel30 "Tire Temp frame 4 pixel 30";
CM_ SG_ 2164275972 pixel31 "Tire Temp frame 4 pixel 31";
CM_ SG_ 2164276228 pixel0 "Tire Temp frame 5 pixel 0";
CM_ SG_ 2164276228 pixel1 "Tire Temp frame 5 pixel 1";
CM_ SG_ 2164276228 pixel2 "Tire Temp frame 5 pixel 2";
CM_ SG_ 2164276228 pixel3 "Tire Temp frame 5 pixel 3";
CM_ SG_ 2164276228 pixel4 "Tire Temp frame 5 pixel 4";
CM_ SG_ 2164276228 pixel5 "Tire Temp frame 5 pixel 5";
CM_ SG_ 2164276228 pixel6 "Tire Temp frame 5 pixel 6";
CM_ SG_ 2164276228 pixel7 "Tire Temp frame 5 pixel 7";
CM_ SG_ 2164276228 pixel8 "Tire Temp frame 5 pixel 8";
CM_ SG_ 2164276228 pixel9 "Tire Temp frame 5 pixel 9";
CM_ SG_ 2164276228 pixel10 "Tire Temp frame 5 pixel 10";
CM_ SG_ 2164276228 pixel11 "Tire Temp frame 5 pixel 11";
CM_ SG_ 2164276228 pixel12 "Tire Temp frame 5 pixel 12";
CM_ SG_ 2164276228 pixel13 "Tire Temp frame 5 pixel 13";
CM_ SG_ 2164276228 pixel14 "Tire Temp frame 5 pixel 14";
CM_ SG_ 2164276228 pixel15 "Tire Temp frame 5 pixel 15";
CM_ SG_ 2164276228 pixel16 "Tire Temp frame 5 pixel 16";
CM_ SG_ 2164276228 pixel17 "Tire Temp frame 5 pixel 17";
CM_ SG_ 2164276228 pixel18 "Tire Temp frame 5 pixel 18";
CM_ SG_ 2164276228 pixel19 "Tire Temp frame 5 pixel 19";
CM_ SG_ 2164276228 pixel20 "Tire Temp frame 5 pixel 20";
CM_ SG_ 2164276228 pixel21 "Tire Temp frame 5 pixel 21";
CM_ SG_ 2164276228 pixel22 "Tire Temp frame 5 pixel 22";
CM_ SG_ 2164276228 pixel23 "Tire Temp frame 5 pixel 23";
CM_ SG_ 2164276228 pixel24 "Tire Temp frame 5 pixel 24";
CM_ SG_ 2164276228 pixel25 "Tire Temp frame 5 pixel 25";
CM_ SG_ 2164276228 pixel26 "Tire Temp frame 5 pixel 26";
CM_ SG_ 2164276228 pixel27 "Tire Temp frame 5 pixel 27";
CM_ SG_ 2164276228 pixel28 "Tire Temp frame 5 pixel 28";
CM_ SG_ 2164276228 pixel29 "Tire Temp frame 5 pixel 29";
CM_ SG_ 2164276228 pixel30 "Tire Temp frame 5 pixel 30";
CM_ SG_ 2164276228 pixel31 "Tire Temp frame 5 pixel 31";
CM_ SG_ 2164276484 pixel0 "Tire Temp frame 6 pixel 0";
CM_ SG_ 2164276484 pixel1 "Tire Temp frame 6 pixel 1";
CM_ SG_ 2164276484 pixel2 "Tire Temp frame 6 pixel 2";
CM_ SG_ 2164276484 pixel3 "Tire Temp frame 6 pixel 3";
CM_ SG_ 2164276484 pixel4 "Tire Temp frame 6 pixel 4";
CM_ SG_ 2164276484 pixel5 "Tire Temp frame 6 pixel 5";
CM_ SG_ 2164276484 pixel6 "Tire Temp frame 6 pixel 6";
CM_ SG_ 2164276484 pixel7 "Tire Temp frame 6 pixel 7";
CM_ SG_ 2164276484 pixel8 "Tire Temp frame 6 pixel 8";
CM_ SG_ 2164276484 pixel9 "Tire Temp frame 6 pixel 9";
CM_ SG_ 2164276484 pixel10 "Tire Temp frame 6 pixel 10";
CM_ SG_ 2164276484 pixel11 "Tire Temp frame 6 pixel 11";
CM_ SG_ 2164276484 pixel12 "Tire Temp frame 6 pixel 12";
CM_ SG_ 2164276484 pixel13 "Tire Temp frame 6 pixel 13";
CM_ SG_ 2164276484 pixel14 "Tire Temp frame 6 pixel 14";
CM_ SG_ 2164276484 pixel15 "Tire Temp frame 6 pixel 15";
CM_ SG_ 2164276484 pixel16 "Tire Temp frame 6 pixel 16";
CM_ SG_ 2164276484 pixel17 "Tire Temp frame 6 pixel 17";
CM_ SG_ 2164276484 pixel18 "Tire Temp frame 6 pixel 18";
CM_ SG_ 2164276484 pixel19 "Tire Temp frame 6 pixel 19";
CM_ SG_ 2164276484 pixel20 "Tire Temp frame 6 pixel 20";
CM_ SG_ 2164276484 pixel21 "Tire Temp frame 6 pixel 21";
CM_ SG_ 2164276484 pixel22 "Tire Temp frame 6 pixel 22";
CM_ SG_ 2164276484 pixel23 "Tire Temp frame 6 pixel 23";
CM_ SG_ 2164276484 pixel24 "Tire Temp frame 6 pixel 24";
CM_ SG_ 2164276484 pixel25 "Tire Temp frame 6 pixel 25";
CM_ SG_ 2164276484 pixel26 "Tire Temp frame 6 pixel 26";
CM_ SG_ 2164276484 pixel27 "Tire Temp frame 6 pixel 27";
CM_ SG_ 2164276484 pixel28 "Tire Temp frame 6 pixel 28";
CM_ SG_ 2164276484 pixel29 "Tire Temp frame 6 pixel 29";
CM_ SG_ 2164276484 pixel30 "Tire Temp frame 6 pixel 30";
CM_ SG_ 2164276484 pixel31 "Tire Temp frame 6 pixel 31";
CM_ SG_ 2164276740 pixel0 "Tire Temp frame 7 pixel 0";
CM_ SG_ 2164276740 pixel1 "Tire Temp frame 7 pixel 1";
CM_ SG_ 2164276740 pixel2 "Tire Temp frame 7 pixel 2";
CM_ SG_ 2164276740 pixel3 "Tire Temp frame 7 pixel 3";
CM_ SG_ 2164276740 pixel4 "Tire Temp frame 7 pixel 4";
CM_ SG_ 2164276740 pixel5 "Tire Temp frame 7 pixel 5";
CM_ SG_ 2164276740 pixel6 "Tire Temp frame 7 pixel 6";
CM_ SG_ 2164276740 pixel7 "Tire Temp frame 7 pixel 7";
CM_ SG_ 2164276740 pixel8 "Tire Temp frame 7 pixel 8";
CM_ SG_ 2164276740 pixel9 "Tire Temp frame 7 pixel 9";
CM_ SG_ 2164276740 pixel10 "Tire Temp frame 7 pixel 10";
CM_ SG_ 2164276740 pixel11 "Tire Temp frame 7 pixel 11";
CM_ SG_ 2164276740 pixel12 "Tire Temp frame 7 pixel 12";
CM_ SG_ 2164276740 pixel13 "Tire Temp frame 7 pixel 13";
CM_ SG_ 2164276740 pixel14 "Tire Temp frame 7 pixel 14";
CM_ SG_ 2164276740 pixel15 "Tire Temp frame 7 pixel 15";
CM_ SG_ 2164276740 pixel16 "Tire Temp frame 7 pixel 16";
CM_ SG_ 2164276740 pixel17 "Tire Temp frame 7 pixel 17";
CM_ SG_ 2164276740 pixel18 "Tire Temp frame 7 pixel 18";
CM_ SG_ 2164276740 pixel19 "Tire Temp frame 7 pixel 19";
CM_ SG_ 2164276740 pixel20 "Tire Temp frame 7 pixel 20";
CM_ SG_ 2164276740 pixel21 "Tire Temp frame 7 pixel 21";
CM_ SG_ 2164276740 pixel22 "Tire Temp frame 7 pixel 22";
CM_ SG_ 2164276740 pixel23 "Tire Temp frame 7 pixel 23";
CM_ SG_ 2164276740 pixel24 "Tire Temp frame 7 pixel 24";
CM_ SG_ 2164276740 pixel25 "Tire Temp frame 7 pixel 25";
CM_ SG_ 2164276740 pixel26 "Tire Temp frame 7 pixel 26";
CM_ SG_ 2164276740 pixel27 "Tire Temp frame 7 pixel 27";
CM_ SG_ 2164276740 pixel28 "Tire Temp frame 7 pixel 28";
CM_ SG_ 2164276740 pixel29 "Tire Temp frame 7 pixel 29";
CM_ SG_ 2164276740 pixel30 "Tire Temp frame 7 pixel 30";
CM_ SG_ 2164276740 pixel31 "Tire Temp frame 7 pixel 31";
CM_ SG_ 2164276996 pixel0 "Tire Temp frame 8 pixel 0";
CM_ SG_ 2164276996 pixel1 "Tire Temp frame 8 pixel 1";
CM_ SG_ 2164276996 pixel2 "Tire Temp frame 8 pixel 2";
CM_ SG_ 2164276996 pixel3 "Tire Temp frame 8 pixel 3";
CM_ SG_ 2164276996 pixel4 "Tire Temp frame 8 pixel 4";
CM_ SG_ 2164276996 pixel5 "Tire Temp frame 8 pixel 5";
CM_ SG_ 2164276996 pixel6 "Tire Temp frame 8 pixel 6";
CM_ SG_ 2164276996 pixel7 "Tire Temp frame 8 pixel 7";
CM_ SG_ 2164276996 pixel8 "Tire Temp frame 8 pixel 8";
CM_ SG_ 2164276996 pixel9 "Tire Temp frame 8 pixel 9";
CM_ SG_ 2164276996 pixel10 "Tire Temp frame 8 pixel 10";
CM_ SG_ 2164276996 pixel11 "Tire Temp frame 8 pixel 11";
CM_ SG_ 2164276996 pixel12 "Tire Temp frame 8 pixel 12";
CM_ SG_ 2164276996 pixel13 "Tire Temp frame 8 pixel 13";
CM_ SG_ 2164276996 pixel14 "Tire Temp frame 8 pixel 14";
CM_ SG_ 2164276996 pixel15 "Tire Temp frame 8 pixel 15";
CM_ SG_ 2164276996 pixel16 "Tire Temp frame 8 pixel 16";
CM_ SG_ 2164276996 pixel17 "Tire Temp frame 8 pixel 17";
CM_ SG_ 2164276996 pixel18 "Tire Temp frame 8 pixel 18";
CM_ SG_ 2164276996 pixel19 "Tire Temp frame 8 pixel 19";
CM_ SG_ 2164276996 pixel20 "Tire Temp frame 8 pixel 20";
CM_ SG_ 2164276996 pixel21 "Tire Temp frame 8 pixel 21";
CM_ SG_ 2164276996 pixel22 "Tire Temp frame 8 pixel 22";
CM_ SG_ 2164276996 pixel23 "Tire Temp frame 8 pixel 23";
CM_ SG_ 2164276996 pixel24 "Tire Temp frame 8 pixel 24";
CM_ SG_ 2164276996 pixel25 "Tire Temp frame 8 pixel 25";
CM_ SG_ 2164276996 pixel26 "Tire Temp frame 8 pixel 26";
CM_ SG_ 2164276996 pixel27 "Tire Temp frame 8 pixel 27";
CM_ SG_ 2164276996 pixel28 "Tire Temp frame 8 pixel 28";
CM_ SG_ 2164276996 pixel29 "Tire Temp frame 8 pixel 29";
CM_ SG_ 2164276996 pixel30 "Tire Temp frame 8 pixel 30";
CM_ SG_ 2164276996 pixel31 "Tire Temp frame 8 pixel 31";
CM_ SG_ 2164277252 pixel0 "Tire Temp frame 9 pixel 0";
CM_ SG_ 2164277252 pixel1 "Tire Temp frame 9 pixel 1";
CM_ SG_ 2164277252 pixel2 "Tire Temp frame 9 pixel 2";
CM_ SG_ 2164277252 pixel3 "Tire Temp frame 9 pixel 3";
CM_ SG_ 2164277252 pixel4 "Tire Temp frame 9 pixel 4";
CM_ SG_ 2164277252 pixel5 "Tire Temp frame 9 pixel 5";
CM_ SG_ 2164277252 pixel6 "Tire Temp frame 9 pixel 6";
CM_ SG_ 2164277252 pixel7 "Tire Temp frame 9 pixel 7";
CM_ SG_ 2164277252 pixel8 "Tire Temp frame 9 pixel 8";
CM_ SG_ 2164277252 pixel9 "Tire Temp frame 9 pixel 9";
CM_ SG_ 2164277252 pixel10 "Tire Temp frame 9 pixel 10";
CM_ SG_ 2164277252 pixel11 "Tire Temp frame 9 pixel 11";
CM_ SG_ 2164277252 pixel12 "Tire Temp frame 9 pixel 12";
CM_ SG_ 2164277252 pixel13 "Tire Temp frame 9 pixel 13";
CM_ SG_ 2164277252 pixel14 "Tire Temp frame 9 pixel 14";
CM_ SG_ 2164277252 pixel15 "Tire Temp frame 9 pixel 15";
CM_ SG_ 2164277252 pixel16 "Tire Temp frame 9 pixel 16";
CM_ SG_ 2164277252 pixel17 "Tire Temp frame 9 pixel 17";
CM_ SG_ 2164277252 pixel18 "Tire Temp frame 9 pixel 18";
CM_ SG_ 2164277252 pixel19 "Tire Temp frame 9 pixel 19";
CM_ SG_ 2164277252 pixel20 "Tire Temp frame 9 pixel 20";
CM_ SG_ 2164277252 pixel21 "Tire Temp frame 9 pixel 21";
CM_ SG_ 2164277252 pixel22 "Tire Temp frame 9 pixel 22";
CM_ SG_ 2164277252 pixel23 "Tire Temp frame 9 pixel 23";
CM_ SG_ 2164277252 pixel24 "Tire Temp frame 9 pixel 24";
CM_ SG_ 2164277252 pixel25 "Tire Temp frame 9 pixel 25";
CM_ SG_ 2164277252 pixel26 "Tire Temp frame 9 pixel 26";
CM_ SG_ 2164277252 pixel27 "Tire Temp frame 9 pixel 27";
CM_ SG_ 2164277252 pixel28 "Tire Temp frame 9 pixel 28";
CM_ SG_ 2164277252 pixel29 "Tire Temp frame 9 pixel 29";
CM_ SG_ 2164277252 pixel30 "Tire Temp frame 9 pixel 30";
CM_ SG_ 2164277252 pixel31 "Tire Temp frame 9 pixel 31";
CM_ SG_ 2164277508 pixel0 "Tire Temp frame 10 pixel 0";
CM_ SG_ 2164277508 pixel1 "Tire Temp frame 10 pixel 1";
CM_ SG_ 2164277508 pixel2 "Tire Temp frame 10 pixel 2";
CM_ SG_ 2164277508 pixel3 "Tire Temp frame 10 pixel 3";
CM_ SG_ 2164277508 pixel4 "Tire Temp frame 10 pixel 4";
CM_ SG_ 2164277508 pixel5 "Tire Temp frame 10 pixel 5";
CM_ SG_ 2164277508 pixel6 "Tire Temp frame 10 pixel 6";
CM_ SG_ 2164277508 pixel7 "Tire Temp frame 10 pixel 7";
CM_ SG_ 2164277508 pixel8 "Tire Temp frame 10 pixel 8";
CM_ SG_ 2164277508 pixel9 "Tire Temp frame 10 pixel 9";
CM_ SG_ 2164277508 pixel10 "Tire Temp frame 10 pixel 10";
CM_ SG_ 2164277508 pixel11 "Tire Temp frame 10 pixel 11";
CM_ SG_ 2164277508 pixel12 "Tire Temp frame 10 pixel 12";
CM_ SG_ 2164277508 pixel13 "Tire Temp frame 10 pixel 13";
CM_ SG_ 2164277508 pixel14 "Tire Temp frame 10 pixel 14";
CM_ SG_ 2164277508 pixel15 "Tire Temp frame 10 pixel 15";
CM_ SG_ 2164277508 pixel16 "Tire Temp frame 10 pixel 16";
CM_ SG_ 2164277508 pixel17 "Tire Temp frame 10 pixel 17";
CM_ SG_ 2164277508 pixel18 "Tire Temp frame 10 pixel 18";
CM_ SG_ 2164277508 pixel19 "Tire Temp frame 10 pixel 19";
CM_ SG_ 2164277508 pixel20 "Tire Temp frame 10 pixel 20";
CM_ SG_ 2164277508 pixel21 "Tire Temp frame 10 pixel 21";
CM_ SG_ 2164277508 pixel22 "Tire Temp frame 10 pixel 22";
CM_ SG_ 2164277508 pixel23 "Tire Temp frame 10 pixel 23";
CM_ SG_ 2164277508 pixel24 "Tire Temp frame 10 pixel 24";
CM_ SG_ 2164277508 pixel25 "Tire Temp frame 10 pixel 25";
CM_ SG_ 2164277508 pixel26 "Tire Temp frame 10 pixel 26";
CM_ SG_ 2164277508 pixel27 "Tire Temp frame 10 pixel 27";
CM_ SG_ 2164277508 pixel28 "Tire Temp frame 10 pixel 28";
CM_ SG_ 2164277508 pixel29 "Tire Temp frame 10 pixel 29";
CM_ SG_ 2164277508 pixel30 "Tire Temp frame 10 pixel 30";
CM_ SG_ 2164277508 pixel31 "Tire Temp frame 10 pixel 31";
CM_ SG_ 2164277764 pixel0 "Tire Temp frame 11 pixel 0";
CM_ SG_ 2164277764 pixel1 "Tire Temp frame 11 pixel 1";
CM_ SG_ 2164277764 pixel2 "Tire Temp frame 11 pixel 2";
CM_ SG_ 2164277764 pixel3 "Tire Temp frame 11 pixel 3";
CM_ SG_ 2164277764 pixel4 "Tire Temp frame 11 pixel 4";
CM_ SG_ 2164277764 pixel5 "Tire Temp frame 11 pixel 5";
CM_ SG_ 2164277764 pixel6 "Tire Temp frame 11 pixel 6";
CM_ SG_ 2164277764 pixel7 "Tire Temp frame 11 pixel 7";
CM_ SG_ 2164277764 pixel8 "Tire Temp frame 11 pixel 8";
CM_ SG_ 2164277764 pixel9 "Tire Temp frame 11 pixel 9";
CM_ SG_ 2164277764 pixel10 "Tire Temp frame 11 pixel 10";
CM_ SG_ 2164277764 pixel11 "Tire Temp frame 11 pixel 11";
CM_ SG_ 2164277764 pixel12 "Tire Temp frame 11 pixel 12";
CM_ SG_ 2164277764 pixel13 "Tire Temp frame 11 pixel 13";
CM_ SG_ 2164277764 pixel14 "Tire Temp frame 11 pixel 14";
CM_ SG_ 2164277764 pixel15 "Tire Temp frame 11 pixel 15";
CM_ SG_ 2164277764 pixel16 "Tire Temp frame 11 pixel 16";
CM_ SG_ 2164277764 pixel17 "Tire Temp frame 11 pixel 17";
CM_ SG_ 2164277764 pixel18 "Tire Temp frame 11 pixel 18";
CM_ SG_ 2164277764 pixel19 "Tire Temp frame 11 pixel 19";
CM_ SG_ 2164277764 pixel20 "Tire Temp frame 11 pixel 20";
CM_ SG_ 2164277764 pixel21 "Tire Temp frame 11 pixel 21";
CM_ SG_ 2164277764 pixel22 "Tire Temp frame 11 pixel 22";
CM_ SG_ 2164277764 pixel23 "Tire Temp frame 11 pixel 23";
CM_ SG_ 2164277764 pixel24 "Tire Temp frame 11 pixel 24";
CM_ SG_ 2164277764 pixel25 "Tire Temp frame 11 pixel 25";
CM_ SG_ 2164277764 pixel26 "Tire Temp frame 11 pixel 26";
CM_ SG_ 2164277764 pixel27 "Tire Temp frame 11 pixel 27";
CM_ SG_ 2164277764 pixel28 "Tire Temp frame 11 pixel 28";
CM_ SG_ 2164277764 pixel29 "Tire Temp frame 11 pixel 29";
CM_ SG_ 2164277764 pixel30 "Tire Temp frame 11 pixel 30";
CM_ SG_ 2164277764 pixel31 "Tire Temp frame 11 pixel 31";
CM_ SG_ 2164278020 pixel0 "Tire Temp frame 12 pixel 0";
CM_ SG_ 2164278020 pixel1 "Tire Temp frame 12 pixel 1";
CM_ SG_ 2164278020 pixel2 "Tire Temp frame 12 pixel 2";
CM_ SG_ 2164278020 pixel3 "Tire Temp frame 12 pixel 3";
CM_ SG_ 2164278020 pixel4 "Tire Temp frame 12 pixel 4";
CM_ SG_ 2164278020 pixel5 "Tire Temp frame 12 pixel 5";
CM_ SG_ 2164278020 pixel6 "Tire Temp frame 12 pixel 6";
CM_ SG_ 2164278020 pixel7 "Tire Temp frame 12 pixel 7";
CM_ SG_ 2164278020 pixel8 "Tire Temp frame 12 pixel 8";
CM_ SG_ 2164278020 pixel9 "Tire Temp frame 12 pixel 9";
CM_ SG_ 2164278020 pixel10 "Tire Temp frame 12 pixel 10";
CM_ SG_ 2164278020 pixel11 "Tire Temp frame 12 pixel 11";
CM_ SG_ 2164278020 pixel12 "Tire Temp frame 12 pixel 12";
CM_ SG_ 2164278020 pixel13 "Tire Temp frame 12 pixel 13";
CM_ SG_ 2164278020 pixel14 "Tire Temp frame 12 pixel 14";
CM_ SG_ 2164278020 pixel15 "Tire Temp frame 12 pixel 15";
CM_ SG_ 2164278020 pixel16 "Tire Temp frame 12 pixel 16";
CM_ SG_ 2164278020 pixel17 "Tire Temp frame 12 pixel 17";
CM_ SG_ 2164278020 pixel18 "Tire Temp frame 12 pixel 18";
CM_ SG_ 2164278020 pixel19 "Tire Temp frame 12 pixel 19";
CM_ SG_ 2164278020 pixel20 "Tire Temp frame 12 pixel 20";
CM_ SG_ 2164278020 pixel21 "Tire Temp frame 12 pixel 21";
CM_ SG_ 2164278020 pixel22 "Tire Temp frame 12 pixel 22";
CM_ SG_ 2164278020 pixel23 "Tire Temp frame 12 pixel 23";
CM_ SG_ 2164278020 pixel24 "Tire Temp frame 12 pixel 24";
CM_ SG_ 2164278020 pixel25 "Tire Temp frame 12 pixel 25";
CM_ SG_ 2164278020 pixel26 "Tire Temp frame 12 pixel 26";
CM_ SG_ 2164278020 pixel27 "Tire Temp frame 12 pixel 27";
CM_ SG_ 2164278020 pixel28 "Tire Temp frame 12 pixel 28";
CM_ SG_ 2164278020 pixel29 "Tire Temp frame 12 pixel 29";
CM_ SG_ 2164278020 pixel30 "Tire Temp frame 12 pixel 30";
CM_ SG_ 2164278020 pixel31 "Tire Temp frame 12 pixel 31";
CM_ SG_ 2164278276 pixel0 "Tire Temp frame 13 pixel 0";
CM_ SG_ 2164278276 pixel1 "Tire Temp frame 13 pixel 1";
CM_ SG_ 2164278276 pixel2 "Tire Temp frame 13 pixel 2";
CM_ SG_ 2164278276 pixel3 "Tire Temp frame 13 pixel 3";
CM_ SG_ 2164278276 pixel4 "Tire Temp frame 13 pixel 4";
CM_ SG_ 2164278276 pixel5 "Tire Temp frame 13 pixel 5";
CM_ SG_ 2164278276 pixel6 "Tire Temp frame 13 pixel 6";
CM_ SG_ 2164278276 pixel7 "Tire Temp frame 13 pixel 7";
CM_ SG_ 2164278276 pixel8 "Tire Temp frame 13 pixel 8";
CM_ SG_ 2164278276 pixel9 "Tire Temp frame 13 pixel 9";
CM_ SG_ 2164278276 pixel10 "Tire Temp frame 13 pixel 10";
CM_ SG_ 2164278276 pixel11 "Tire Temp frame 13 pixel 11";
CM_ SG_ 2164278276 pixel12 "Tire Temp frame 13 pixel 12";
CM_ SG_ 2164278276 pixel13 "Tire Temp frame 13 pixel 13";
CM_ SG_ 2164278276 pixel14 "Tire Temp frame 13 pixel 14";
CM_ SG_ 2164278276 pixel15 "Tire Temp frame 13 pixel 15";
CM_ SG_ 2164278276 pixel16 "Tire Temp frame 13 pixel 16";
CM_ SG_ 2164278276 pixel17 "Tire Temp frame 13 pixel 17";
CM_ SG_ 2164278276 pixel18 "Tire Temp frame 13 pixel 18";
CM_ SG_ 2164278276 pixel19 "Tire Temp frame 13 pixel 19";
CM_ SG_ 2164278276 pixel20 "Tire Temp frame 13 pixel 20";
CM_ SG_ 2164278276 pixel21 "Tire Temp frame 13 pixel 21";
CM_ SG_ 2164278276 pixel22 "Tire Temp frame 13 pixel 22";
CM_ SG_ 2164278276 pixel23 "Tire Temp frame 13 pixel 23";
CM_ SG_ 2164278276 pixel24 "Tire Temp frame 13 pixel 24";
CM_ SG_ 2164278276 pixel25 "Tire Temp frame 13 pixel 25";
CM_ SG_ 2164278276 pixel26 "Tire Temp frame 13 pixel 26";
CM_ SG_ 2164278276 pixel27 "Tire Temp frame 13 pixel 27";
CM_ SG_ 2164278276 pixel28 "Tire Temp frame 13 pixel 28";
CM_ SG_ 2164278276 pixel29 "Tire Temp frame 13 pixel 29";
CM_ SG_ 2164278276 pixel30 "Tire Temp frame 13 pixel 30";
CM_ SG_ 2164278276 pixel31 "Tire Temp frame 13 pixel 31";
CM_ SG_ 2164278532 pixel0 "Tire Temp frame 14 pixel 0";
CM_ SG_ 2164278532 pixel1 "Tire Temp frame 14 pixel 1";
CM_ SG_ 2164278532 pixel2 "Tire Temp frame 14 pixel 2";
CM_ SG_ 2164278532 pixel3 "Tire Temp frame 14 pixel 3";
CM_ SG_ 2164278532 pixel4 "Tire Temp frame 14 pixel 4";
CM_ SG_ 2164278532 pixel5 "Tire Temp frame 14 pixel 5";
CM_ SG_ 2164278532 pixel6 "Tire Temp frame 14 pixel 6";
CM_ SG_ 2164278532 pixel7 "Tire Temp frame 14 pixel 7";
CM_ SG_ 2164278532 pixel8 "Tire Temp frame 14 pixel 8";
CM_ SG_ 2164278532 pixel9 "Tire Temp frame 14 pixel 9";
CM_ SG_ 2164278532 pixel10 "Tire Temp frame 14 pixel 10";
CM_ SG_ 2164278532 pixel11 "Tire Temp frame 14 pixel 11";
CM_ SG_ 2164278532 pixel12 "Tire Temp frame 14 pixel 12";
CM_ SG_ 2164278532 pixel13 "Tire Temp frame 14 pixel 13";
CM_ SG_ 2164278532 pixel14 "Tire Temp frame 14 pixel 14";
CM_ SG_ 2164278532 pixel15 "Tire Temp frame 14 pixel 15";
CM_ SG_ 2164278532 pixel16 "Tire Temp frame 14 pixel 16";
CM_ SG_ 2164278532 pixel17 "Tire Temp frame 14 pixel 17";
CM_ SG_ 2164278532 pixel18 "Tire Temp frame 14 pixel 18";
CM_ SG_ 2164278532 pixel19 "Tire Temp frame 14 pixel 19";
CM_ SG_ 2164278532 pixel20 "Tire Temp frame 14 pixel 20";
CM_ SG_ 2164278532 pixel21 "Tire Temp frame 14 pixel 21";
CM_ SG_ 2164278532 pixel22 "Tire Temp frame 14 pixel 22";
CM_ SG_ 2164278532 pixel23 "Tire Temp frame 14 pixel 23";
CM_ SG_ 2164278532 pixel24 "Tire Temp frame 14 pixel 24";
CM_ SG_ 2164278532 pixel25 "Tire Temp frame 14 pixel 25";
CM_ SG_ 2164278532 pixel26 "Tire Temp frame 14 pixel 26";
CM_ SG_ 2164278532 pixel27 "Tire Temp frame 14 pixel 27";
CM_ SG_ 2164278532 pixel28 "Tire Temp frame 14 pixel 28";
CM_ SG_ 2164278532 pixel29 "Tire Temp frame 14 pixel 29";
CM_ SG_ 2164278532 pixel30 "Tire Temp frame 14 pixel 30";
CM_ SG_ 2164278532 pixel31 "Tire Temp frame 14 pixel 31";
CM_ SG_ 2164278788 pixel0 "Tire Temp frame 15 pixel 0";
CM_ SG_ 2164278788 pixel1 "Tire Temp frame 15 pixel 1";
CM_ SG_ 2164278788 pixel2 "Tire Temp frame 15 pixel 2";
CM_ SG_ 2164278788 pixel3 "Tire Temp frame 15 pixel 3";
CM_ SG_ 2164278788 pixel4 "Tire Temp frame 15 pixel 4";
CM_ SG_ 2164278788 pixel5 "Tire Temp frame 15 pixel 5";
CM_ SG_ 2164278788 pixel6 "Tire Temp frame 15 pixel 6";
CM_ SG_ 2164278788 pixel7 "Tire Temp frame 15 pixel 7";
CM_ SG_ 2164278788 pixel8 "Tire Temp frame 15 pixel 8";
CM_ SG_ 2164278788 pixel9 "Tire Temp frame 15 pixel 9";
CM_ SG_ 2164278788 pixel10 "Tire Temp frame 15 pixel 10";
CM_ SG_ 2164278788 pixel11 "Tire Temp frame 15 pixel 11";
CM_ SG_ 2164278788 pixel12 "Tire Temp frame 15 pixel 12";
CM_ SG_ 2164278788 pixel13 "Tire Temp frame 15 pixel 13";
CM_ SG_ 2164278788 pixel14 "Tire Temp frame 15 pixel 14";
CM_ SG_ 2164278788 pixel15 "Tire Temp frame 15 pixel 15";
CM_ SG_ 2164278788 pixel16 "Tire Temp frame 15 pixel 16";
CM_ SG_ 2164278788 pixel17 "Tire Temp frame 15 pixel 17";
CM_ SG_ 2164278788 pixel18 "Tire Temp frame 15 pixel 18";
CM_ SG_ 2164278788 pixel19 "Tire Temp frame 15 pixel 19";
CM_ SG_ 2164278788 pixel20 "Tire Temp frame 15 pixel 20";
CM_ SG_ 2164278788 pixel21 "Tire Temp frame 15 pixel 21";
CM_ SG_ 2164278788 pixel22 "Tire Temp frame 15 pixel 22";
CM_ SG_ 2164278788 pixel23 "Tire Temp frame 15 pixel 23";
CM_ SG_ 2164278788 pixel24 "Tire Temp frame 15 pixel 24";
CM_ SG_ 2164278788 pixel25 "Tire Temp frame 15 pixel 25";
CM_ SG_ 2164278788 pixel26 "Tire Temp frame 15 pixel 26";
CM_ SG_ 2164278788 pixel27 "Tire Temp frame 15 pixel 27";
CM_ SG_ 2164278788 pixel28 "Tire Temp frame 15 pixel 28";
CM_ SG_ 2164278788 pixel29 "Tire Temp frame 15 pixel 29";
CM_ SG_ 2164278788 pixel30 "Tire Temp frame 15 pixel 30";
CM_ SG_ 2164278788 pixel31 "Tire Temp frame 15 pixel 31";
BA_DEF_  "BusType" STRING ;
BA_DEF_  "DBName" STRING ;
BA_DEF_  "GRBusID" INT 0 255;
BA_DEF_ BU_  "GRID" INT 0 255;
BA_DEF_ BO_  "VFrameFormat" ENUM  "StandardCAN","ExtendedCAN","reserved","reserved","reserved","reserved","reserved","reserved","reserved","reserved","reserved","reserved","reserved","reserved","StandardCAN_FD","ExtendedCAN_FD";
BA_DEF_ BO_  "CANFD_BRS" ENUM  "0","1";
BA_DEF_ BO_  "GRMsgName" STRING ;
BA_DEF_ BO_  "GRMsgID" INT -1 4095;
BA_DEF_ SG_  "GRValueType" ENUM  "Number","ASCII";
BA_DEF_DEF_  "BusType" "CAN FD";
BA_DEF_DEF_  "DBName" "";
BA_DEF_DEF_  "GRBusID" 0;
BA_DEF_DEF_  "GRID" 0;
BA_DEF_DEF_  "VFrameFormat" "StandardCAN_FD";
BA_DEF_DEF_  "CANFD_BRS" "1";
BA_DEF_DEF_  "GRMsgName" "";
BA_DEF_DEF_  "GRMsgID" -1;
BA_DEF_DEF_  "GRValueType" "Number";
BA_ "DBName" "Data";
BA_ "GRBusID" 2;
BA_ "GRID" BU_ ACU 3;
BA_ "GRID" BU_ BrakeTemp_FL 28;
BA_ "GRID" BU_ BrakeTemp_FR 29;
BA_ "GRID" BU_ BrakeTemp_RL 30;
BA_ "GRID" BU_ BrakeTemp_RR 31;
BA_ "GRID" BU_ DGPS 32;
BA_ "GRID" BU_ Debugger 1;
BA_ "GRID" BU_ ECU 2;
BA_ "GRID" BU_ InboardFloor_FL 24;
BA_ "GRID" BU_ InboardFloor_FR 25;
BA_ "GRID" BU_ InboardFloor_RL 26;
BA_ "GRID" BU_ InboardFloor_RR 27;
BA_ "GRID" BU_ Steering_Wheel 34;
BA_ "GRID" BU_ Suspension_FL 20;
BA_ "GRID" BU_ Suspension_FR 21;
BA_ "GRID" BU_ Suspension_RL 22;
BA_ "GRID" BU_ Suspension_RR 23;
BA_ "GRID" BU_ TCM 4;
BA_ "GRID" BU_ TireTemp_FL 16;
BA_ "GRID" BU_ TireTemp_FR 17;
BA_ "GRID" BU_ TireTemp_RL 18;
BA_ "GRID" BU_ TireTemp_RR 19;
BA_ "VFrameFormat" BO_ 2183159554 15;
BA_ "VFrameFormat" BO_ 2150629633 15;
BA_ "VFrameFormat" BO_ 2150629889 15;
BA_ "VFrameFormat" BO_ 2150629890 15;
BA_ "VFrameFormat" BO_ 2150632706 15;
BA_ "VFrameFormat" BO_ 2150632962 15;
BA_ "VFrameFormat" BO_ 2150633218 15;
BA_ "VFrameFormat" BO_ 2150633474 15;
BA_ "VFrameFormat" BO_ 2150633730 15;
BA_ "VFrameFormat" BO_ 2148532482 15;
BA_ "VFrameFormat" BO_ 2148532738 15;
BA_ "VFrameFormat" BO_ 2148532483 15;
BA_ "VFrameFormat" BO_ 2148532739 15;
BA_ "VFrameFormat" BO_ 2148532484 15;
BA_ "VFrameFormat" BO_ 2148532740 15;
BA_ "VFrameFormat" BO_ 2149581057 15;
BA_ "VFrameFormat" BO_ 2149581313 15;
BA_ "VFrameFormat" BO_ 2149592580 15;
BA_ "VFrameFormat" BO_ 2149592324 15;
BA_ "VFrameFormat" BO_ 2149592836 15;
BA_ "VFrameFormat" BO_ 2149581312 15;
BA_ "VFrameFormat" BO_ 2151689986 15;
BA_ "VFrameFormat" BO_ 2151678465 15;
BA_ "VFrameFormat" BO_ 2181038594 15;
BA_ "VFrameFormat" BO_ 2181051140 15;
BA_ "VFrameFormat" BO_ 2181050628 15;
BA_ "VFrameFormat" BO_ 2181050884 15;
BA_ "VFrameFormat" BO_ 2181051396 15;
BA_ "VFrameFormat" BO_ 2181051652 15;
BA_ "VFrameFormat" BO_ 2181051908 15;
BA_ "VFrameFormat" BO_ 2181050372 15;
BA_ "VFrameFormat" BO_ 2168455682 15;
BA_ "VFrameFormat" BO_ 2168475908 15;
BA_ "VFrameFormat" BO_ 2169504258 15;
BA_ "VFrameFormat" BO_ 2169524484 15;
BA_ "VFrameFormat" BO_ 2170552834 15;
BA_ "VFrameFormat" BO_ 2170573060 15;
BA_ "VFrameFormat" BO_ 2171601410 15;
BA_ "VFrameFormat" BO_ 2171621636 15;
BA_ "VFrameFormat" BO_ 2172649986 15;
BA_ "VFrameFormat" BO_ 2172670468 15;
BA_ "VFrameFormat" BO_ 2173698562 15;
BA_ "VFrameFormat" BO_ 2173719044 15;
BA_ "VFrameFormat" BO_ 2174747138 15;
BA_ "VFrameFormat" BO_ 2174767620 15;
BA_ "VFrameFormat" BO_ 2175795714 15;
BA_ "VFrameFormat" BO_ 2175816196 15;
BA_ "VFrameFormat" BO_ 2164261378 15;
BA_ "VFrameFormat" BO_ 2164274948 15;
BA_ "VFrameFormat" BO_ 2164275204 15;
BA_ "VFrameFormat" BO_ 2164275460 15;
BA_ "VFrameFormat" BO_ 2164275716 15;
BA_ "VFrameFormat" BO_ 2164275972 15;
BA_ "VFrameFormat" BO_ 2164276228 15;
BA_ "VFrameFormat" BO_ 2164276484 15;
BA_ "VFrameFormat" BO_ 2164276740 15;
BA_ "VFrameFormat" BO_ 2164276996 15;
BA_ "VFrameFormat" BO_ 2164277252 15;
BA_ "VFrameFormat" BO_ 2164277508 15;
BA_ "VFrameFormat" BO_ 2164277764 15;
BA_ "VFrameFormat" BO_ 2164278020 15;
BA_ "VFrameFormat" BO_ 2164278276 15;
BA_ "VFrameFormat" BO_ 2164278532 15;
BA_ "VFrameFormat" BO_ 2164278788 15;
BA_ "GRMsgName" BO_ 2183159554 "Regen_Buttons";
BA_ "GRMsgName" BO_ 2150629633 "Debug_FD";
BA_ "GRMsgName" BO_ 2150629889 "Ping";
BA_ "GRMsgName" BO_ 2150629890 "Ping";
BA_ "GRMsgName" BO_ 2150632706 "ACU_Cell_Data_1";
BA_ "GRMsgName" BO_ 2150632962 "ACU_Cell_Data_2";
BA_ "GRMsgName" BO_ 2150633218 "ACU_Cell_Data_3";
BA_ "GRMsgName" BO_ 2150633474 "ACU_Cell_Data_4";
BA_ "GRMsgName" BO_ 2150633730 "ACU_Cell_Data_5";
BA_ "GRMsgName" BO_ 2148532482 "Debug_FD";
BA_ "GRMsgName" BO_ 2148532738 "Ping";
BA_ "GRMsgName" BO_ 2148532483 "Debug_FD";
BA_ "GRMsgName" BO_ 2148532739 "Ping";
BA_ "GRMsgName" BO_ 2148532484 "Debug_FD";
BA_ "GRMsgName" BO_ 2148532740 "Ping";
BA_ "GRMsgName" BO_ 2149581057 "Debug_FD";
BA_ "GRMsgName" BO_ 2149581313 "Ping";
BA_ "GRMsgName" BO_ 2149592580 "ECU_Analog_Data";
BA_ "GRMsgName" BO_ 2149592324 "ECU_Pinging_RTT";
BA_ "GRMsgName" BO_ 2149592836 "ECU_Config";
BA_ "GRMsgName" BO_ 2149581312 "Ping";
BA_ "GRMsgName" BO_ 2151689986 "ECU_Config";
BA_ "GRMsgName" BO_ 2151678465 "Ping";
BA_ "GRMsgName" BO_ 2181038594 "Ping";
BA_ "GRMsgName" BO_ 2181051140 "GPS_ALT";
BA_ "GRMsgName" BO_ 2181050628 "GPS_LAT";
BA_ "GRMsgName" BO_ 2181050884 "GPS_LON";
BA_ "GRMsgName" BO_ 2181051396 "GPS_PX";
BA_ "GRMsgName" BO_ 2181051652 "GPS_QY";
BA_ "GRMsgName" BO_ 2181051908 "GPS_RZ";
BA_ "GRMsgName" BO_ 2181050372 "UVW_DGPS";
BA_ "GRMsgName" BO_ 2168455682 "Ping";
BA_ "GRMsgName" BO_ 2168475908 "Suspension_IMU_Mag_Data";
BA_ "GRMsgName" BO_ 2169504258 "Ping";
BA_ "GRMsgName" BO_ 2169524484 "Suspension_IMU_Mag_Data";
BA_ "GRMsgName" BO_ 2170552834 "Ping";
BA_ "GRMsgName" BO_ 2170573060 "Suspension_IMU_Mag_Data";
BA_ "GRMsgName" BO_ 2171601410 "Ping";
BA_ "GRMsgName" BO_ 2171621636 "Suspension_IMU_Mag_Data";
BA_ "GRMsgName" BO_ 2172649986 "Ping";
BA_ "GRMsgName" BO_ 2172670468 "InboardFloor_IMU_ToF_Data";
BA_ "GRMsgName" BO_ 2173698562 "Ping";
BA_ "GRMsgName" BO_ 2173719044 "InboardFloor_IMU_ToF_Data";
BA_ "GRMsgName" BO_ 2174747138 "Ping";
BA_ "GRMsgName" BO_ 2174767620 "InboardFloor_IMU_ToF_Data";
BA_ "GRMsgName" BO_ 2175795714 "Ping";
BA_ "GRMsgName" BO_ 2175816196 "InboardFloor_IMU_ToF_Data";
BA_ "GRMsgName" BO_ 2164261378 "Ping";
BA_ "GRMsgName" BO_ 2164274948 "Tire_Temp_Frame_0";
BA_ "GRMsgName" BO_ 2164275204 "Tire_Temp_Frame_1";
BA_ "GRMsgName" BO_ 2164275460 "Tire_Temp_Frame_2";
BA_ "GRMsgName" BO_ 2164275716 "Tire_Temp_Frame_3";
BA_ "GRMsgName" BO_ 2164275972 "Tire_Temp_Frame_4";
BA_ "GRMsgName" BO_ 2164276228 "Tire_Temp_Frame_5";
BA_ "GRMsgName" BO_ 2164276484 "Tire_Temp_Frame_6";
BA_ "GRMsgName" BO_ 2164276740 "Tire_Temp_Frame_7";
BA_ "GRMsgName" BO_ 2164276996 "Tire_Temp_Frame_8";
BA_ "GRMsgName" BO_ 2164277252 "Tire_Temp_Frame_9";
BA_ "GRMsgName" BO_ 2164277508 "Tire_Temp_Frame_10";
BA_ "GRMsgName" BO_ 2164277764 "Tire_Temp_Frame_11";
BA_ "GRMsgName" BO_ 2164278020 "Tire_Temp_Frame_12";
BA_ "GRMsgName" BO_ 2164278276 "Tire_Temp_Frame_13";
BA_ "GRMsgName" BO_ 2164278532 "Tire_Temp_Frame_14";
BA_ "GRMsgName" BO_ 2164278788 "Tire_Temp_Frame_15";
BA_ "GRMsgID" BO_ 2183159554 95;
BA_ "GRMsgID" BO_ 2150629633 1;
BA_ "GRMsgID" BO_ 2150629889 2;
BA_ "GRMsgID" BO_ 2150629890 2;
BA_ "GRMsgID" BO_ 2150632706 13;
BA_ "GRMsgID" BO_ 2150632962 14;
BA_ "GRMsgID" BO_ 2150633218 15;
BA_ "GRMsgID" BO_ 2150633474 16;
BA_ "GRMsgID" BO_ 2150633730 17;
BA_ "GRMsgID" BO_ 2148532482 1;
BA_ "GRMsgID" BO_ 2148532738 2;
BA_ "GRMsgID" BO_ 2148532483 1;
BA_ "GRMsgID" BO_ 2148532739 2;
BA_ "GRMsgID" BO_ 2148532484 1;
BA_ "GRMsgID" BO_ 2148532740 2;
BA_ "GRMsgID" BO_ 2149581057 1;
BA_ "GRMsgID" BO_ 2149581313 2;
BA_ "GRMsgID" BO_ 2149592580 46;
BA_ "GRMsgID" BO_ 2149592324 45;
BA_ "GRMsgID" BO_ 2149592836 47;
BA_ "GRMsgID" BO_ 2149581312 2;
BA_ "GRMsgID" BO_ 2151689986 47;
BA_ "GRMsgID" BO_ 2151678465 2;
BA_ "GRMsgID" BO_ 2181038594 2;
BA_ "GRMsgID" BO_ 2181051140 51;
BA_ "GRMsgID" BO_ 2181050628 49;
BA_ "GRMsgID" BO_ 2181050884 50;
BA_ "GRMsgID" BO_ 2181051396 52;
BA_ "GRMsgID" BO_ 2181051652 53;
BA_ "GRMsgID" BO_ 2181051908 54;
BA_ "GRMsgID" BO_ 2181050372 48;
BA_ "GRMsgID" BO_ 2168455682 2;
BA_ "GRMsgID" BO_ 2168475908 81;
BA_ "GRMsgID" BO_ 2169504258 2;
BA_ "GRMsgID" BO_ 2169524484 81;
BA_ "GRMsgID" BO_ 2170552834 2;
BA_ "GRMsgID" BO_ 2170573060 81;
BA_ "GRMsgID" BO_ 2171601410 2;
BA_ "GRMsgID" BO_ 2171621636 81;
BA_ "GRMsgID" BO_ 2172649986 2;
BA_ "GRMsgID" BO_ 2172670468 82;
BA_ "GRMsgID" BO_ 2173698562 2;
BA_ "GRMsgID" BO_ 2173719044 82;
BA_ "GRMsgID" BO_ 2174747138 2;
BA_ "GRMsgID" BO_ 2174767620 82;
BA_ "GRMsgID" BO_ 2175795714 2;
BA_ "GRMsgID" BO_ 2175816196 82;
BA_ "GRMsgID" BO_ 2164261378 2;
BA_ "GRMsgID" BO_ 2164274948 55;
BA_ "GRMsgID" BO_ 2164275204 56;
BA_ "GRMsgID" BO_ 2164275460 57;
BA_ "GRMsgID" BO_ 2164275716 58;
BA_ "GRMsgID" BO_ 2164275972 59;
BA_ "GRMsgID" BO_ 2164276228 60;
BA_ "GRMsgID" BO_ 2164276484 61;
BA_ "GRMsgID" BO_ 2164276740 62;
BA_ "GRMsgID" BO_ 2164276996 63;
BA_ "GRMsgID" BO_ 2164277252 64;
BA_ "GRMsgID" BO_ 2164277508 65;
BA_ "GRMsgID" BO_ 2164277764 66;
BA_ "GRMsgID" BO_ 2164278020 67;
BA_ "GRMsgID" BO_ 2164278276 68;
BA_ "GRMsgID" BO_ 2164278532 69;
BA_ "GRMsgID" BO_ 2164278788 70;
BA_ "GRValueType" SG_ 2150629633 Debug_0 1;
BA_ "GRValueType" SG_ 2150629633 Debug_1 1;
BA_ "GRValueType" SG_ 2150629633 Debug_2 1;
BA_ "GRValueType" SG_ 2150629633 Debug_3 1;
BA_ "GRValueType" SG_ 2150629633 Debug_4 1;
BA_ "GRValueType" SG_ 2150629633 Debug_5 1;
BA_ "GRValueType" SG_ 2150629633 Debug_6 1;
BA_ "GRValueType" SG_ 2150629633 Debug_7 1;
BA_ "GRValueType" SG_ 2150629633 Debug_8 1;
BA_ "GRValueType" SG_ 2150629633 Debug_9 1;
BA_ "GRValueType" SG_ 2150629633 Debug_10 1;
BA_ "GRValueType" SG_ 2150629633 Debug_11 1;
BA_ "GRValueType" SG_ 2150629633 Debug_12 1;
BA_ "GRValueType" SG_ 2150629633 Debug_13 1;
BA_ "GRValueType" SG_ 2150629633 Debug_14 1;
BA_ "GRValueType" SG_ 2150629633 Debug_15 1;
BA_ "GRValueType" SG_ 2150629633 Debug_16 1;
BA_ "GRValueType" SG_ 2150629633 Debug_17 1;
BA_ "GRValueType" SG_ 2150629633 Debug_18 1;
BA_ "GRValueType" SG_ 2150629633 Debug_19 1;
BA_ "GRValueType" SG_ 2150629633 Debug_20 1;
BA_ "GRValueType" SG_ 2150629633 Debug_21 1;
BA_ "GRValueType" SG_ 2150629633 Debug_22 1;
BA_ "GRValueType" SG_ 2150629633 Debug_23 1;
BA_ "GRValueType" SG_ 2150629633 Debug_24 1;
BA_ "GRValueType" SG_ 2150629633 Debug_25 1;
BA_ "GRValueType" SG_ 2150629633 Debug_26 1;
BA_ "GRValueType" SG_ 2150629633 Debug_27 1;
BA_ "GRValueType" SG_ 2150629633 Debug_28 1;
BA_ "GRValueType" SG_ 2150629633 Debug_29 1;
BA_ "GRValueType" SG_ 2150629633 Debug_30 1;
BA_ "GRValueType" SG_ 2150629633 Debug_31 1;
BA_ "GRValueType" SG_ 2150629633 Debug_32 1;
BA_ "GRValueType" SG_ 2150629633 Debug_33 1;
BA_ "GRValueType" SG_ 2150629633 Debug_34 1;
BA_ "GRValueType" SG_ 2150629633 Debug_35 1;
BA_ "GRValueType" SG_ 2150629633 Debug_36 1;
BA_ "GRValueType" SG_ 2150629633 Debug_37 1;
BA_ "GRValueType" SG_ 2150629633 Debug_38 1;
BA_ "GRValueType" SG_ 2150629633 Debug_39 1;
BA_ "GRValueType" SG_ 2150629633 Debug_40 1;
BA_ "GRValueType" SG_ 2150629633 Debug_41 1;
BA_ "GRValueType" SG_ 2150629633 Debug_42 1;
BA_ "GRValueType" SG_ 2150629633 Debug_43 1;
BA_ "GRValueType" SG_ 2150629633 Debug_44 1;
BA_ "GRValueType" SG_ 2150629633 Debug_45 1;
BA_ "GRValueType" SG_ 2150629633 Debug_46 1;
BA_ "GRValueType" SG_ 2150629633 Debug_47 1;
BA_ "GRValueType" SG_ 2150629633 Debug_48 1;
BA_ "GRValueType" SG_ 2150629633 Debug_49 1;
BA_ "GRValueType" SG_ 2150629633 Debug_50 1;
BA_ "GRValueType" SG_ 2150629633 Debug_51 1;
BA_ "GRValueType" SG_ 2150629633 Debug_52 1;
BA_ "GRValueType" SG_ 2150629633 Debug_53 1;
BA_ "GRValueType" SG_ 2150629633 Debug_54 1;
BA_ "GRValueType" SG_ 2150629633 Debug_55 1;
BA_ "GRValueType" SG_ 2150629633 Debug_56 1;
BA_ "GRValueType" SG_ 2150629633 Debug_57 1;
BA_ "GRValueType" SG_ 2150629633 Debug_58 1;
BA_ "GRValueType" SG_ 2150629633 Debug_59 1;
BA_ "GRValueType" SG_ 2150629633 Debug_60 1;
BA_ "GRValueType" SG_ 2150629633 Debug_61 1;
BA_ "GRValueType" SG_ 2150629633 Debug_62 1;
BA_ "GRValueType" SG_ 2150629633 Debug_63 1;
BA_ "GRValueType" SG_ 2148532482 Debug_0 1;
BA_ "GRValueType" SG_ 2148532482 Debug_1 1;
BA_ "GRValueType" SG_ 2148532482 Debug_2 1;
BA_ "GRValueType" SG_ 2148532482 Debug_3 1;
BA_ "GRValueType" SG_ 2148532482 Debug_4 1;
BA_ "GRValueType" SG_ 2148532482 Debug_5 1;
BA_ "GRValueType" SG_ 2148532482 Debug_6 1;
BA_ "GRValueType" SG_ 2148532482 Debug_7 1;
BA_ "GRValueType" SG_ 2148532482 Debug_8 1;
BA_ "GRValueType" SG_ 2148532482 Debug_9 1;
BA_ "GRValueType" SG_ 2148532482 Debug_10 1;
BA_ "GRValueType" SG_ 2148532482 Debug_11 1;
BA_ "GRValueType" SG_ 2148532482 Debug_12 1;
BA_ "GRValueType" SG_ 2148532482 Debug_13 1;
BA_ "GRValueType" SG_ 2148532482 Debug_14 1;
BA_ "GRValueType" SG_ 2148532482 Debug_15 1;
BA_ "GRValueType" SG_ 2148532482 Debug_16 1;
BA_ "GRValueType" SG_ 2148532482 Debug_17 1;
BA_ "GRValueType" SG_ 2148532482 Debug_18 1;
BA_ "GRValueType" SG_ 2148532482 Debug_19 1;
BA_ "GRValueType" SG_ 2148532482 Debug_20 1;
BA_ "GRValueType" SG_ 2148532482 Debug_21 1;
BA_ "GRValueType" SG_ 2148532482 Debug_22 1;
BA_ "GRValueType" SG_ 2148532482 Debug_23 1;
BA_ "GRValueType" SG_ 2148532482 Debug_24 1;
BA_ "GRValueType" SG_ 2148532482 Debug_25 1;
BA_ "GRValueType" SG_ 2148532482 Debug_26 1;
BA_ "GRValueType" SG_ 2148532482 Debug_27 1;
BA_ "GRValueType" SG_ 2148532482 Debug_28 1;
BA_ "GRValueType" SG_ 2148532482 Debug_29 1;
BA_ "GRValueType" SG_ 2148532482 Debug_30 1;
BA_ "GRValueType" SG_ 2148532482 Debug_31 1;
BA_ "GRValueType" SG_ 2148532482 Debug_32 1;
BA_ "GRValueType" SG_ 2148532482 Debug_33 1;
BA_ "GRValueType" SG_ 2148532482 Debug_34 1;
BA_ "GRValueType" SG_ 2148532482 Debug_35 1;
BA_ "GRValueType" SG_ 2148532482 Debug_36 1;
BA_ "GRValueType" SG_ 2148532482 Debug_37 1;
BA_ "GRValueType" SG_ 2148532482 Debug_38 1;
BA_ "GRValueType" SG_ 2148532482 Debug_39 1;
BA_ "GRValueType" SG_ 2148532482 Debug_40 1;
BA_ "GRValueType" SG_ 2148532482 Debug_41 1;
BA_ "GRValueType" SG_ 2148532482 Debug_42 1;
BA_ "GRValueType" SG_ 2148532482 Debug_43 1;
BA_ "GRValueType" SG_ 2148532482 Debug_44 1;
BA_ "GRValueType" SG_ 2148532482 Debug_45 1;
BA_ "GRValueType" SG_ 2148532482 Debug_46 1;
BA_ "GRValueType" SG_ 2148532482 Debug_47 1;
BA_ "GRValueType" SG_ 2148532482 Debug_48 1;
BA_ "GRValueType" SG_ 2148532482 Debug_49 1;
BA_ "GRValueType" SG_ 2148532482 Debug_50 1;
BA_ "GRValueType" SG_ 2148532482 Debug_51 1;
BA_ "GRValueType" SG_ 2148532482 Debug_52 1;
BA_ "GRValueType" SG_ 2148532482 Debug_53 1;
BA_ "GRValueType" SG_ 2148532482 Debug_54 1;
BA_ "GRValueType" SG_ 2148532482 Debug_55 1;
BA_ "GRValueType" SG_ 2148532482 Debug_56 1;
BA_ "GRValueType" SG_ 2148532482 Debug_57 1;
BA_ "GRValueType" SG_ 2148532482 Debug_58 1;
BA_ "GRValueType" SG_ 2148532482 Debug_59 1;
BA_ "GRValueType" SG_ 2148532482 Debug_60 1;
BA_ "GRValueType" SG_ 2148532482 Debug_61 1;
BA_ "GRValueType" SG_ 2148532482 Debug_62 1;
BA_ "GRValueType" SG_ 2148532482 Debug_63 1;
BA_ "GRValueType" SG_ 2148532483 Debug_0 1;
BA_ "GRValueType" SG_ 2148532483 Debug_1 1;
BA_ "GRValueType" SG_ 2148532483 Debug_2 1;
BA_ "GRValueType" SG_ 2148532483 Debug_3 1;
BA_ "GRValueType" SG_ 2148532483 Debug_4 1;
BA_ "GRValueType" SG_ 2148532483 Debug_5 1;
BA_ "GRValueType" SG_ 2148532483 Debug_6 1;
BA_ "GRValueType" SG_ 2148532483 Debug_7 1;
BA_ "GRValueType" SG_ 2148532483 Debug_8 1;
BA_ "GRValueType" SG_ 2148532483 Debug_9 1;
BA_ "GRValueType" SG_ 2148532483 Debug_10 1;
BA_ "GRValueType" SG_ 2148532483 Debug_11 1;
BA_ "GRValueType" SG_ 2148532483 Debug_12 1;
BA_ "GRValueType" SG_ 2148532483 Debug_13 1;
BA_ "GRValueType" SG_ 2148532483 Debug_14 1;
BA_ "GRValueType" SG_ 2148532483 Debug_15 1;
BA_ "GRValueType" SG_ 2148532483 Debug_16 1;
BA_ "GRValueType" SG_ 2148532483 Debug_17 1;
BA_ "GRValueType" SG_ 2148532483 Debug_18 1;
BA_ "GRValueType" SG_ 2148532483 Debug_19 1;
BA_ "GRValueType" SG_ 2148532483 Debug_20 1;
BA_ "GRValueType" SG_ 2148532483 Debug_21 1;
BA_ "GRValueType" SG_ 2148532483 Debug_22 1;
BA_ "GRValueType" SG_ 2148532483 Debug_23 1;
BA_ "GRValueType" SG_ 2148532483 Debug_24 1;
BA_ "GRValueType" SG_ 2148532483 Debug_25 1;
BA_ "GRValueType" SG_ 2148532483 Debug_26 1;
BA_ "GRValueType" SG_ 2148532483 Debug_27 1;
BA_ "GRValueType" SG_ 2148532483 Debug_28 1;
BA_ "GRValueType" SG_ 2148532483 Debug_29 1;
BA_ "GRValueType" SG_ 2148532483 Debug_30 1;
BA_ "GRValueType" SG_ 2148532483 Debug_31 1;
BA_ "GRValueType" SG_ 2148532483 Debug_32 1;
BA_ "GRValueType" SG_ 2148532483 Debug_33 1;
BA_ "GRValueType" SG_ 2148532483 Debug_34 1;
BA_ "GRValueType" SG_ 2148532483 Debug_35 1;
BA_ "GRValueType" SG_ 2148532483 Debug_36 1;
BA_ "GRValueType" SG_ 2148532483 Debug_37 1;
BA_ "GRValueType" SG_ 2148532483 Debug_38 1;
BA_ "GRValueType" SG_ 2148532483 Debug_39 1;
BA_ "GRValueType" SG_ 2148532483 Debug_40 1;
BA_ "GRValueType" SG_ 2148532483 Debug_41 1;
BA_ "GRValueType" SG_ 2148532483 Debug_42 1;
BA_ "GRValueType" SG_ 2148532483 Debug_43 1;
BA_ "GRValueType" SG_ 2148532483 Debug_44 1;
BA_ "GRValueType" SG_ 2148532483 Debug_45 1;
BA_ "GRValueType" SG_ 2148532483 Debug_46 1;
BA_ "GRValueType" SG_ 2148532483 Debug_47 1;
BA_ "GRValueType" SG_ 2148532483 Debug_48 1;
BA_ "GRValueType" SG_ 2148532483 Debug_49 1;
BA_ "GRValueType" SG_ 2148532483 Debug_50 1;
BA_ "GRValueType" SG_ 2148532483 Debug_51 1;
BA_ "GRValueType" SG_ 2148532483 Debug_52 1;
BA_ "GRValueType" SG_ 2148532483 Debug_53 1;
BA_ "GRValueType" SG_ 2148532483 Debug_54 1;
BA_ "GRValueType" SG_ 2148532483 Debug_55 1;
BA_ "GRValueType" SG_ 2148532483 Debug_56 1;
BA_ "GRValueType" SG_ 2148532483 Debug_57 1;
BA_ "GRValueType" SG_ 2148532483 Debug_58 1;
BA_ "GRValueType" SG_ 2148532483 Debug_59 1;
BA_ "GRValueType" SG_ 2148532483 Debug_60 1;
BA_ "GRValueType" SG_ 2148532483 Debug_61 1;
BA_ "GRValueType" SG_ 2148532483 Debug_62 1;
BA_ "GRValueType" SG_ 2148532483 Debug_63 1;
BA_ "GRValueType" SG_ 2148532484 Debug_0 1;
BA_ "GRValueType" SG_ 2148532484 Debug_1 1;
BA_ "GRValueType" SG_ 2148532484 Debug_2 1;
BA_ "GRValueType" SG_ 2148532484 Debug_3 1;
BA_ "GRValueType" SG_ 2148532484 Debug_4 1;
BA_ "GRValueType" SG_ 2148532484 Debug_5 1;
BA_ "GRValueType" SG_ 2148532484 Debug_6 1;
BA_ "GRValueType" SG_ 2148532484 Debug_7 1;
BA_ "GRValueType" SG_ 2148532484 Debug_8 1;
BA_ "GRValueType" SG_ 2148532484 Debug_9 1;
BA_ "GRValueType" SG_ 2148532484 Debug_10 1;
BA_ "GRValueType" SG_ 2148532484 Debug_11 1;
BA_ "GRValueType" SG_ 2148532484 Debug_12 1;
BA_ "GRValueType" SG_ 2148532484 Debug_13 1;
BA_ "GRValueType" SG_ 2148532484 Debug_14 1;
BA_ "GRValueType" SG_ 2148532484 Debug_15 1;
BA_ "GRValueType" SG_ 2148532484 Debug_16 1;
BA_ "GRValueType" SG_ 2148532484 Debug_17 1;
BA_ "GRValueType" SG_ 2148532484 Debug_18 1;
BA_ "GRValueType" SG_ 2148532484 Debug_19 1;
BA_ "GRValueType" SG_ 2148532484 Debug_20 1;
BA_ "GRValueType" SG_ 2148532484 Debug_21 1;
BA_ "GRValueType" SG_ 2148532484 Debug_22 1;
BA_ "GRValueType" SG_ 2148532484 Debug_23 1;
BA_ "GRValueType" SG_ 2148532484 Debug_24 1;
BA_ "GRValueType" SG_ 2148532484 Debug_25 1;
BA_ "GRValueType" SG_ 2148532484 Debug_26 1;
BA_ "GRValueType" SG_ 2148532484 Debug_27 1;
BA_ "GRValueType" SG_ 2148532484 Debug_28 1;
BA_ "GRValueType" SG_ 2148532484 Debug_29 1;
BA_ "GRValueType" SG_ 2148532484 Debug_30 1;
BA_ "GRValueType" SG_ 2148532484 Debug_31 1;
BA_ "GRValueType" SG_ 2148532484 Debug_32 1;
BA_ "GRValueType" SG_ 2148532484 Debug_33 1;
BA_ "GRValueType" SG_ 2148532484 Debug_34 1;
BA_ "GRValueType" SG_ 2148532484 Debug_35 1;
BA_ "GRValueType" SG_ 2148532484 Debug_36 1;
BA_ "GRValueType" SG_ 2148532484 Debug_37 1;
BA_ "GRValueType" SG_ 2148532484 Debug_38 1;
BA_ "GRValueType" SG_ 2148532484 Debug_39 1;
BA_ "GRValueType" SG_ 2148532484 Debug_40 1;
BA_ "GRValueType" SG_ 2148532484 Debug_41 1;
BA_ "GRValueType" SG_ 2148532484 Debug_42 1;
BA_ "GRValueType" SG_ 2148532484 Debug_43 1;
BA_ "GRValueType" SG_ 2148532484 Debug_44 1;
BA_ "GRValueType" SG_ 2148532484 Debug_45 1;
BA_ "GRValueType" SG_ 2148532484 Debug_46 1;
BA_ "GRValueType" SG_ 2148532484 Debug_47 1;
BA_ "GRValueType" SG_ 2148532484 Debug_48 1;
BA_ "GRValueType" SG_ 2148532484 Debug_49 1;
BA_ "GRValueType" SG_ 2148532484 Debug_50 1;
BA_ "GRValueType" SG_ 2148532484 Debug_51 1;
BA_ "GRValueType" SG_ 2148532484 Debug_52 1;
BA_ "GRValueType" SG_ 2148532484 Debug_53 1;
BA_ "GRValueType" SG_ 2148532484 Debug_54 1;
BA_ "GRValueType" SG_ 2148532484 Debug_55 1;
BA_ "GRValueType" SG_ 2148532484 Debug_56 1;
BA_ "GRValueType" SG_ 2148532484 Debug_57 1;
BA_ "GRValueType" SG_ 2148532484 Debug_58 1;
BA_ "GRValueType" SG_ 2148532484 Debug_59 1;
BA_ "GRValueType" SG_ 2148532484 Debug_60 1;
BA_ "GRValueType" SG_ 2148532484 Debug_61 1;
BA_ "GRValueType" SG_ 2148532484 Debug_62 1;
BA_ "GRValueType" SG_ 2148532484 Debug_63 1;
BA_ "GRValueType" SG_ 2149581057 Debug_0 1;
BA_ "GRValueType" SG_ 2149581057 Debug_1 1;
BA_ "GRValueType" SG_ 2149581057 Debug_2 1;
BA_ "GRValueType" SG_ 2149581057 Debug_3 1;
BA_ "GRValueType" SG_ 2149581057 Debug_4 1;
BA_ "GRValueType" SG_ 2149581057 Debug_5 1;
BA_ "GRValueType" SG_ 2149581057 Debug_6 1;
BA_ "GRValueType" SG_ 2149581057 Debug_7 1;
BA_ "GRValueType" SG_ 2149581057 Debug_8 1;
BA_ "GRValueType" SG_ 2149581057 Debug_9 1;
BA_ "GRValueType" SG_ 2149581057 Debug_10 1;
BA_ "GRValueType" SG_ 2149581057 Debug_11 1;
BA_ "GRValueType" SG_ 2149581057 Debug_12 1;
BA_ "GRValueType" SG_ 2149581057 Debug_13 1;
BA_ "GRValueType" SG_ 2149581057 Debug_14 1;
BA_ "GRValueType" SG_ 2149581057 Debug_15 1;
BA_ "GRValueType" SG_ 2149581057 Debug_16 1;
BA_ "GRValueType" SG_ 2149581057 Debug_17 1;
BA_ "GRValueType" SG_ 2149581057 Debug_18 1;
BA_ "GRValueType" SG_ 2149581057 Debug_19 1;
BA_ "GRValueType" SG_ 2149581057 Debug_20 1;
BA_ "GRValueType" SG_ 2149581057 Debug_21 1;
BA_ "GRValueType" SG_ 2149581057 Debug_22 1;
BA_ "GRValueType" SG_ 2149581057 Debug_23 1;
BA_ "GRValueType" SG_ 2149581057 Debug_24 1;
BA_ "GRValueType" SG_ 2149581057 Debug_25 1;
BA_ "GRValueType" SG_ 2149581057 Debug_26 1;
BA_ "GRValueType" SG_ 2149581057 Debug_27 1;
BA_ "GRValueType" SG_ 2149581057 Debug_28 1;
BA_ "GRValueType" SG_ 2149581057 Debug_29 1;
BA_ "GRValueType" SG_ 2149581057 Debug_30 1;
BA_ "GRValueType" SG_ 2149581057 Debug_31 1;
BA_ "GRValueType" SG_ 2149581057 Debug_32 1;
BA_ "GRValueType" SG_ 2149581057 Debug_33 1;
BA_ "GRValueType" SG_ 2149581057 Debug_34 1;
BA_ "GRValueType" SG_ 2149581057 Debug_35 1;
BA_ "GRValueType" SG_ 2149581057 Debug_36 1;
BA_ "GRValueType" SG_ 2149581057 Debug_37 1;
BA_ "GRValueType" SG_ 2149581057 Debug_38 1;
BA_ "GRValueType" SG_ 2149581057 Debug_39 1;
BA_ "GRValueType" SG_ 2149581057 Debug_40 1;
BA_ "GRValueType" SG_ 2149581057 Debug_41 1;
BA_ "GRValueType" SG_ 2149581057 Debug_42 1;
BA_ "GRValueType" SG_ 2149581057 Debug_43 1;
BA_ "GRValueType" SG_ 2149581057 Debug_44 1;
BA_ "GRValueType" SG_ 2149581057 Debug_45 1;
BA_ "GRValueType" SG_ 2149581057 Debug_46 1;
BA_ "GRValueType" SG_ 2149581057 Debug_47 1;
BA_ "GRValueType" SG_ 2149581057 Debug_48 1;
BA_ "GRValueType" SG_ 2149581057 Debug_49 1;
BA_ "GRValueType" SG_ 2149581057 Debug_50 1;
BA_ "GRValueType" SG_ 2149581057 Debug_51 1;
BA_ "GRValueType" SG_ 2149581057 Debug_52 1;
BA_ "GRValueType" SG_ 2149581057 Debug_53 1;
BA_ "GRValueType" SG_ 2149581057 Debug_54 1;
BA_ "GRValueType" SG_ 2149581057 Debug_55 1;
BA_ "GRValueType" SG_ 2149581057 Debug_56 1;
BA_ "GRValueType" SG_ 2149581057 Debug_57 1;
BA_ "GRValueType" SG_ 2149581057 Debug_58 1;
BA_ "GRValueType" SG_ 2149581057 Debug_59 1;
BA_ "GRValueType" SG_ 2149581057 Debug_60 1;
BA_ "GRValueType" SG_ 2149581057 Debug_61 1;
BA_ "GRValueType" SG_ 2149581057 Debug_62 1;
BA_ "GRValueType" SG_ 2149581057 Debug_63 1;
SIG_VALTYPE_ 2181051140 ALT : 2;
SIG_VALTYPE_ 2181050628 LAT : 2;
SIG_VALTYPE_ 2181050884 LON : 2;
